VERSION "2021.24.4"

NS_ :

BS_:

BU_: VEH CH Receiver X

BA_DEF_ BO_ "GenMsgSendType" ENUM "Cyclic";
BA_DEF_ BO_ "GenMsgCycleTime" INT 0 10000;

BA_ "GenMsgSendType" BO_ 1019 0;
BA_ "GenMsgCycleTime" BO_ 1019 1000;

BO_ 946 BMS_log2: 8 Vector__XXX
 SG_ BMS_cacAgedMinRawIsValid m1 : 63|1@1+ (1,0) [0|0] "" Vector__XXX
 SG_ BMS_spmeBrick1ValidForCorrection m51 : 63|1@1+ (1,0) [0|0] "" Vector__XXX
 SG_ BMS_thermalEvent1pDetectConfigDi m71 : 63|1@1+ (1,0) [0|0] "" Vector__XXX
 SG_ BMS_vChangeWindowChangeIsOutlier m23 : 63|1@1+ (1,0) [0|0] "" Vector__XXX
 SG_ BMS_energyBufferConfigNvramValid m71 : 62|1@1+ (1,0) [0|0] "" Vector__XXX
 SG_ BMS_histogramTemperatureIrration m30 : 62|1@1+ (1,0) [0|0] "" Vector__XXX
 SG_ BMS_spmeMaxBrickValidForCorrecti m53 : 62|1@1+ (1,0) [0|0] "" Vector__XXX
 SG_ BMS_spmeMinBrickValidForCorrecti m52 : 62|1@1+ (1,0) [0|0] "" Vector__XXX
 SG_ BMS_histogramStorageDataIsLow m30 : 61|1@1+ (1,0) [0|0] "" Vector__XXX
 SG_ BMS_sampleChargePower m4 : 61|1@1+ (1,0) [0|0] "" Vector__XXX
 SG_ BMS_cacEstimationSource m65 : 60|2@1+ (1,0) [0|0] "" Vector__XXX
 SG_ BMS_histogramTotalTimeIrrational m30 : 60|1@1+ (1,0) [0|0] "" Vector__XXX
 SG_ BMS_lifeModelNvramIsValid m63 : 60|1@1+ (1,0) [0|0] "" Vector__XXX
 SG_ BMS_spmeBrick1LowestCostIndex m50 : 60|4@1+ (1,0) [0|0] "" Vector__XXX
 SG_ BMS_histogramChargeThroughputIrr m30 : 59|1@1+ (1,0) [0|0] "" Vector__XXX
 SG_ BMS_maxSocCorrectionTypeWindowed m73 : 59|2@1+ (1,0) [0|0] "" Vector__XXX
 SG_ BMS_cpUserChargeStatus m4 : 58|3@1+ (1,0) [0|0] "" Vector__XXX
 SG_ BMS_histogramDischargeThroughput m30 : 58|1@1+ (1,0) [0|0] "" Vector__XXX
 SG_ BMS_hvChainConfig m2 : 58|3@1+ (1,0) [0|0] "" Vector__XXX
 SG_ BMS_packCalibrationBirthDat_0000 m67 : 58|1@1+ (1,0) [0|0] "" Vector__XXX
 SG_ BMS_spmeMaxSocLowestCostIndex m53 : 58|4@1+ (1,0) [0|0] "" Vector__XXX
 SG_ BMS_spmeMinSocLowestCostIndex m52 : 58|4@1+ (1,0) [0|0] "" Vector__XXX
 SG_ BMS_cacMaxBrickId m0 : 57|7@1+ (1,1) [0|0] "" Vector__XXX
 SG_ BMS_histogramStartTimeIrrational m30 : 57|1@1+ (1,0) [0|0] "" Vector__XXX
 SG_ BMS_lifeModelOutputsAreTrustwort m31 : 57|1@1+ (1,0) [0|0] "" Vector__XXX
 SG_ BMS_spmeLastReInitReason m48 : 57|2@1+ (1,0) [0|0] "" Vector__XXX
 SG_ BMS_brickBleedByVoltageTargetBri m35 : 56|7@1+ (1,1) [0|0] "" Vector__XXX
 SG_ BMS_cacNvramEstimationSource m2 : 56|2@1+ (1,0) [0|0] "" Vector__XXX
 SG_ BMS_largestSynchronizedCacErrorP m56 : 56|8@1+ (0.1,0) [0|0] "" Vector__XXX
 SG_ BMS_minPackTempForChargeToStart m91 : 56|7@1+ (0.5,-40) [0|0] "" Vector__XXX
 SG_ BMS_numBricksRestingForCac m58 : 56|8@1+ (1,0) [0|0] "" Vector__XXX
 SG_ BMS_peakRegenCurrentLimitMode m3 : 56|4@1+ (1,0) [0|0] "" Vector__XXX
 SG_ BMS_powerVsVoltageChgEnergy_0000 m68 : 56|8@1+ (0.01,2) [0|0] "" Vector__XXX
 SG_ BMS_runtimeSocMinTempForModel m71 : 56|6@1+ (0.5,0) [0|0] "" Vector__XXX
 SG_ BMS_socByDvMaxBrickId m90 : 56|8@1+ (1,1) [0|0] "" Vector__XXX
 SG_ BMS_socImbalancePct m82 : 56|8@1+ (0.1,0) [0|0] "" Vector__XXX
 SG_ BMS_tempVsVoltageDcChgWeigh_0000 m69 : 56|8@1+ (0.01,2) [0|0] "" Vector__XXX
 SG_ BMS_thmGradient m21 : 56|8@1+ (0.1,0) [0|0] "" Vector__XXX
 SG_ BMS_vChangeWindowTimeAfterWake m23 : 56|7@1+ (0.1,0) [0|0] "" Vector__XXX
 SG_ BMS_acRippleStartTemperatureMin m18 : 55|9@1+ (0.25,-25) [0|0] "" Vector__XXX
 SG_ BMS_cellAttributesShipPackForFai m85 : 55|1@1+ (1,0) [0|0] "" Vector__XXX
 SG_ BMS_dSocCacMargin m33 : 55|9@1+ (0.0030517578125,0) [0|0] "" Vector__XXX
 SG_ BMS_passiveCoolCellTargetT m54 : 55|9@1+ (0.25,-25) [0|0] "" Vector__XXX
 SG_ BMS_rubberBandingConfigNvramVali m71 : 55|1@1+ (1,0) [0|0] "" Vector__XXX
 SG_ BMS_spmeInitCountSinceReset m51 : 55|8@1+ (1,0) [0|0] "" Vector__XXX
 SG_ BMS_acRippleMaxSocAllowed m36 : 54|10@1+ (0.1,0) [0|0] "" Vector__XXX
 SG_ BMS_acRippleMinSocAllowed m37 : 54|10@1+ (0.1,0) [0|0] "" Vector__XXX
 SG_ BMS_brick1SocCorrectionSpmeLower m74 : 54|10@1+ (0.1,0) [0|0] "" Vector__XXX
 SG_ BMS_cacBlendPercentPerDayUpperBo m27 : 54|10@1+ (0.001,0) [0|0] "" Vector__XXX
 SG_ BMS_cellAttributesAutocloseAndSc m85 : 54|1@1+ (1,0) [0|0] "" Vector__XXX
 SG_ BMS_continuousDcrBlendFactor m34 : 54|10@1+ (0.001,0) [0|0] "" Vector__XXX
 SG_ BMS_dcrBlendFactorPerDayUpperBou m57 : 54|10@1+ (0.001,0) [0|0] "" Vector__XXX
 SG_ BMS_energyChargeSocTarget m87 : 54|10@1+ (0.1,0) [0|0] "" Vector__XXX
 SG_ BMS_percentCacUpdatesInTimeWindo m64 : 54|10@1+ (0.1,0) [0|0] "" Vector__XXX
 SG_ BMS_rubberBandingEnabled m71 : 54|1@1+ (1,0) [0|0] "" Vector__XXX
 SG_ BMS_cacBlendPercentPerCycle m20 : 53|10@1+ (0.001,0) [0|0] "" Vector__XXX
 SG_ BMS_cacImbalanceCurrentAdjustmen m38 : 53|10@1+ (0.1,0) [0|0] "" Vector__XXX
 SG_ BMS_cacMaxKalmanError m1 : 53|10@1+ (0.01,0) [0|0] "" Vector__XXX
 SG_ BMS_diNodeModelTemp m60 : 53|11@1+ (0.1,-50) [0|0] "" Vector__XXX
 SG_ BMS_lowCurrentInterruptionCurren m45 : 53|9@1- (0.1,0) [0|0] "" Vector__XXX
 SG_ BMS_runtimeSocCorrectionsEnabled m71 : 53|1@1+ (1,0) [0|0] "" Vector__XXX
 SG_ BMS_shuntOffsetCalibrationTemp m84 : 53|11@1- (0.05,0) [0|0] "" Vector__XXX
 SG_ BMS_cacBlendingEnabled m20 : 52|1@1+ (1,0) [0|0] "" Vector__XXX
 SG_ BMS_dSocNoiseMargin m24 : 52|10@1+ (0.0030517578125,0) [0|0] "" Vector__XXX
 SG_ BMS_lifeModelThroughputDcrCycleC m80 : 52|12@1+ (1,0) [0|0] "" Vector__XXX
 SG_ BMS_prevUserFacingSohEnergy m79 : 52|11@1+ (0.1,0) [0|0] "" Vector__XXX
 SG_ BMS_restingPointCacBrick1 m66 : 52|12@1+ (0.1,0) [0|0] "" Vector__XXX
 SG_ BMS_runtimeSocConfigNvramValid m71 : 52|1@1+ (1,0) [0|0] "" Vector__XXX
 SG_ BMS_runtimeSocElectrolyteVoltage m72 : 52|10@1- (0.001,-0.5) [0|0] "" Vector__XXX
 SG_ BMS_soloWakeCount m44 : 52|12@1+ (1,0) [0|0] "" Vector__XXX
 SG_ BMS_spmeBrick1CathodeSurfaceConc m49 : 52|10@1+ (0.001,0) [0|0] "" Vector__XXX
 SG_ BMS_vshResMax2 m25 : 52|12@1+ (0.002,0) [0|0] "" Vector__XXX
 SG_ BMS_vshResMin3 m26 : 52|12@1+ (0.002,0) [0|0] "" Vector__XXX
 SG_ BMS_cacBlendingConfigNvramValid m20 : 51|1@1+ (1,0) [0|0] "" Vector__XXX
 SG_ BMS_cellChargeDcCurrentLimit m89 : 51|12@1+ (0.5,0) [0|0] "" Vector__XXX
 SG_ BMS_largestSyncCacErrorLower m62 : 51|12@1+ (0.1,0) [0|0] "" Vector__XXX
 SG_ BMS_lowCurrentInterruptionReason m45 : 51|2@1+ (1,0) [0|0] "" Vector__XXX
 SG_ BMS_cacAvgAgedRawEstimate m59 : 50|13@1+ (0.1,0) [0|0] "" Vector__XXX
 SG_ BMS_cacAvgOffsetUpdateEndPointSo m81 : 50|10@1+ (0.1,0) [0|0] "" Vector__XXX
 SG_ BMS_cacTransitionBlendOffset m40 : 50|10@1- (0.1,0) [0|0] "" Vector__XXX
 SG_ BMS_cacUpdateDeltaSocByAhSpread m61 : 50|11@1- (0.01,0) [0|0] "" Vector__XXX
 SG_ BMS_dSocMinAlphaSocBleedMargin m41 : 50|12@1+ (0.0030517578125,0) [0|0] "" Vector__XXX
 SG_ BMS_maxSpreadChangeSocStart m75 : 50|10@1+ (0.1,0) [0|0] "" Vector__XXX
 SG_ BMS_negCtrDeviationConfidenceMax m14 : 50|13@1+ (0.000122100107192,0) [0|0] "" Vector__XXX
 SG_ BMS_negCtrDeviationFiltConfMax m15 : 50|13@1+ (0.000122100107192,0) [0|0] "" Vector__XXX
 SG_ BMS_negCtrDropCorrectedFiltMax m16 : 50|13@1- (0.001221299164314,0) [0|0] "" Vector__XXX
 SG_ BMS_negCtrOffsetErrorConf m17 : 50|13@1+ (0.000122100107192,0) [0|0] "" Vector__XXX
 SG_ BMS_negCtrResistanceConfidence m9 : 50|13@1+ (12.21001071916841,0) [0|0] "" Vector__XXX
 SG_ BMS_posCtrDeviationConfidenceMax m10 : 50|13@1+ (0.000122100107192,0) [0|0] "" Vector__XXX
 SG_ BMS_posCtrDeviationFiltConfMax m11 : 50|13@1+ (0.000122100107192,0) [0|0] "" Vector__XXX
 SG_ BMS_posCtrDropCorrectedFiltMax m12 : 50|13@1- (0.001221299164314,0) [0|0] "" Vector__XXX
 SG_ BMS_posCtrOffsetErrorConf m13 : 50|13@1+ (0.000122100107192,0) [0|0] "" Vector__XXX
 SG_ BMS_recentBmbMiaAlert m20 : 50|1@1+ (1,0) [0|0] "" Vector__XXX
 SG_ BMS_rubberBandingConfigDischarge m76 : 50|10@1+ (0.1,0) [0|0] "" Vector__XXX
 SG_ BMS_socTopVsSocBtmDchWeightedAvg m46 : 50|14@1+ (0.01,0) [0|0] "" Vector__XXX
 SG_ BMS_1kHzTask_maxExecTime m8 : 49|11@1+ (1,0) [0|0] "" Vector__XXX
 SG_ BMS_cellTempTargetMode m91 : 49|4@1+ (1,0) [0|0] "" Vector__XXX
 SG_ BMS_dcrBlendFactorPerCycle m43 : 49|10@1+ (0.001,0) [0|0] "" Vector__XXX
 SG_ BMS_recentIsoAlert m20 : 49|1@1+ (1,0) [0|0] "" Vector__XXX
 SG_ BMS_avgShuntAsicCurrentOffset m83 : 48|15@1- (0.2,0) [0|0] "" Vector__XXX
 SG_ BMS_capacityImbalancePct m22 : 48|10@1+ (0.1,0) [0|0] "" Vector__XXX
 SG_ BMS_cellAttributesCellType m85 : 48|6@1+ (1,0) [0|0] "" Vector__XXX
 SG_ BMS_chargeTimeEstimate m86 : 48|14@1+ (0.1,0) [0|0] "" Vector__XXX
 SG_ BMS_dSocMinAlphaBrickID m33 : 48|7@1+ (1,1) [0|0] "" Vector__XXX
 SG_ BMS_dcrBlendingEnabled m43 : 48|1@1+ (1,0) [0|0] "" Vector__XXX
 SG_ BMS_energyReserveAvg m19 : 48|16@1+ (0.001,0) [0|0] "" Vector__XXX
 SG_ BMS_largestCacSpreadErrorUpper m63 : 48|12@1+ (0.1,0) [0|0] "" Vector__XXX
 SG_ BMS_latchedFullPackEnergyError m88 : 48|10@1- (0.1,0) [0|0] "" Vector__XXX
 SG_ BMS_lifeModelDcrGrowthPercent m55 : 48|14@1- (0.1,200) [0|0] "" Vector__XXX
 SG_ BMS_lifeModelThroughputDcrGrowth m77 : 48|14@1- (0.1,200) [0|0] "" Vector__XXX
 SG_ BMS_maxCapacityLossModuleId m38 : 48|5@1+ (1,1) [0|0] "" Vector__XXX
 SG_ BMS_maxPossibleDcChargePower m2 : 48|8@1+ (1,0) [0|0] "" Vector__XXX
 SG_ BMS_maxSocChangeWindowed m73 : 48|11@1- (0.1,0) [0|0] "" Vector__XXX
 SG_ BMS_recentOvUvAlert m20 : 48|1@1+ (1,0) [0|0] "" Vector__XXX
 SG_ BMS_restingPointCacAvg m65 : 48|12@1+ (0.1,0) [0|0] "" Vector__XXX
 SG_ BMS_sohTestBlockReason m45 : 48|3@1+ (1,0) [0|0] "" Vector__XXX
 SG_ BMS_spmeBrick1BestFitCost m50 : 48|12@1+ (1e-05,0) [0|0] "" Vector__XXX
 SG_ BMS_stateOfHealthMinCacLowerBoun m78 : 48|13@1+ (0.1,0) [0|0] "" Vector__XXX
 SG_ BMS_unexpectedLossOfLvCounter m57 : 48|6@1+ (1,0) [0|0] "" Vector__XXX
 SG_ BMS_vshTestMinDeltaVBrickID m3 : 48|7@1+ (1,1) [0|0] "" Vector__XXX
 SG_ BMS_brickBleedByAhMinBrickId m36 : 47|7@1+ (1,1) [0|0] "" Vector__XXX
 SG_ BMS_brickBleedChargeMaxBrickId m34 : 47|7@1+ (1,1) [0|0] "" Vector__XXX
 SG_ BMS_brickBleedExcessChargeMaxBri m37 : 47|7@1+ (1,1) [0|0] "" Vector__XXX
 SG_ BMS_currentReg_targetI m4 : 47|11@1+ (0.5,0) [0|0] "" Vector__XXX
 SG_ BMS_powerVsVoltageChgEnergyWeigh m68 : 47|9@1+ (0.01,0) [0|0] "" Vector__XXX
 SG_ BMS_acRippleStartTemperatureMax m18 : 46|9@1+ (0.25,-25) [0|0] "" Vector__XXX
 SG_ BMS_lifeModelThroughputCapacityL m54 : 46|9@1+ (0.1,0) [0|0] "" Vector__XXX
 SG_ BMS_sohMinCacConfidenceBound m82 : 46|10@1+ (0.1,0) [0|0] "" Vector__XXX
 SG_ BMS_spmeMaxSocBestFitCost m53 : 46|12@1+ (1e-05,0) [0|0] "" Vector__XXX
 SG_ BMS_spmeMinSocBestFitCost m52 : 46|12@1+ (1e-05,0) [0|0] "" Vector__XXX
 SG_ BMS_vshResMaxIndex2 m25 : 46|6@1+ (1,0) [0|0] "" Vector__XXX
 SG_ BMS_vshResMinIndex3 m26 : 46|6@1+ (1,0) [0|0] "" Vector__XXX
 SG_ BMS_acRippleIsSupported m18 : 45|1@1+ (1,0) [0|0] "" Vector__XXX
 SG_ BMS_brick1SocCorrectionSpmeUpper m74 : 44|10@1+ (0.1,0) [0|0] "" Vector__XXX
 SG_ BMS_brick1SocCorrectionType m73 : 44|2@1+ (1,0) [0|0] "" Vector__XXX
 SG_ BMS_cacBlendPercentPerDayLowerBo m27 : 44|10@1+ (0.001,0) [0|0] "" Vector__XXX
 SG_ BMS_cacMax m0 : 44|13@1+ (0.1,0) [0|0] "" Vector__XXX
 SG_ BMS_cellAttributesConfigNvramVal m85 : 44|1@1+ (1,0) [0|0] "" Vector__XXX
 SG_ BMS_dSocMaxLowAlphaCounter m33 : 44|4@1+ (1,0) [0|0] "" Vector__XXX
 SG_ BMS_lifeModelAverageOffset m64 : 44|10@1- (0.1,0) [0|0] "" Vector__XXX
 SG_ BMS_sohTestEndMode m45 : 44|4@1+ (1,0) [0|0] "" Vector__XXX
 SG_ BMS_spmeBrick1ModelVsNominalSocO m51 : 44|11@1- (0.1,0) [0|0] "" Vector__XXX
 SG_ BMS_thmGradientSlope m21 : 44|10@1- (0.01,0) [0|0] "" Vector__XXX
 SG_ BMS_userChargeCalibratingReason m57 : 44|2@1+ (1,0) [0|0] "" Vector__XXX
 SG_ BMS_vChangeWindowMinBrickV m23 : 44|12@1+ (0.002,0) [0|0] "" Vector__XXX
 SG_ BMS_cacMinAgedUpperBoundEst m58 : 43|13@1+ (0.1,0) [0|0] "" Vector__XXX
 SG_ BMS_cellAttributesRemanufactured m85 : 43|1@1+ (1,0) [0|0] "" Vector__XXX
 SG_ BMS_numOfBricks m89 : 43|8@1+ (1,0) [0|0] "" Vector__XXX
 SG_ BMS_temperatureCondition m21 : 43|1@1+ (1,0) [0|0] "" Vector__XXX
 SG_ BMS_largestSyncCacErrorEndSoc m71 : 42|10@1+ (0.1,0) [0|0] "" Vector__XXX
 SG_ BMS_runtimeSocMinCorrectionThres m72 : 42|10@1+ (0.1,0) [0|0] "" Vector__XXX
 SG_ BMS_socChangeSocByOcvMax m24 : 42|10@1+ (0.1,0) [0|0] "" Vector__XXX
 SG_ BMS_spmeBrick1CathodeBulkConcent m49 : 42|10@1+ (0.001,0) [0|0] "" Vector__XXX
 SG_ BMS_energyLowestDchBrickCac m87 : 41|13@1+ (0.1,0) [0|0] "" Vector__XXX
 SG_ BMS_estimatedCapacitySohEnergy m79 : 41|11@1+ (0.1,0) [0|0] "" Vector__XXX
 SG_ BMS_spmeAhDischargedAfterZero m48 : 41|16@1+ (0.1,0) [0|0] "" Vector__XXX
 SG_ BMS_activeCoolCellTargetT m91 : 40|9@1+ (0.25,-25) [0|0] "" Vector__XXX
 SG_ BMS_brickBleedByAhTargetBrickId m36 : 40|7@1+ (1,1) [0|0] "" Vector__XXX
 SG_ BMS_brickBleedByVoltageTarget m35 : 40|16@1+ (0.0001,0) [0|0] "" Vector__XXX
 SG_ BMS_brickBleedChargeMinBrickId m34 : 40|7@1+ (1,1) [0|0] "" Vector__XXX
 SG_ BMS_brickBleedExcessChargeMinBri m37 : 40|7@1+ (1,1) [0|0] "" Vector__XXX
 SG_ BMS_cacAvgOffsetUpdateStartPoint m81 : 40|10@1+ (0.1,0) [0|0] "" Vector__XXX
 SG_ BMS_cacEndPointSocSpread m61 : 40|10@1+ (0.1,0) [0|0] "" Vector__XXX
 SG_ BMS_cacMinUpperBoundEst m1 : 40|13@1+ (0.1,0) [0|0] "" Vector__XXX
 SG_ BMS_cellAttributesPackManufactur m85 : 40|3@1+ (1,0) [0|0] "" Vector__XXX
 SG_ BMS_cumulativeBrickBleedTimeMaxB m41 : 40|10@1+ (1,1) [0|0] "" Vector__XXX
 SG_ BMS_cumulativeBrickBleedTimeMinB m40 : 40|10@1+ (1,1) [0|0] "" Vector__XXX
 SG_ BMS_energyChgWhWhPerDayTotalTime m28 : 40|24@1+ (0.05,0) [0|0] "" Vector__XXX
 SG_ BMS_energyDcChgWhWhPerDayTotalTi m29 : 40|24@1+ (0.05,0) [0|0] "" Vector__XXX
 SG_ BMS_idealEnergyRemainingBuffered m56 : 40|16@1+ (0.02,0) [0|0] "" Vector__XXX
 SG_ BMS_lifeModelThroughputCycleCoun m80 : 40|12@1+ (1,0) [0|0] "" Vector__XXX
 SG_ BMS_lifeModelThroughputDcrTemper m78 : 40|7@1+ (0.1,0) [0|0] "" Vector__XXX
 SG_ BMS_minCapacityLossModuleId m38 : 40|5@1+ (1,1) [0|0] "" Vector__XXX
 SG_ BMS_pctTimeAtHighSoc m70 : 40|14@1+ (0.01,0) [0|0] "" Vector__XXX
 SG_ BMS_restingPointCacMin m66 : 40|12@1+ (0.1,0) [0|0] "" Vector__XXX
 SG_ BMS_shuntMeasurementSoloWakeCoun m44 : 40|12@1+ (1,0) [0|0] "" Vector__XXX
 SG_ BMS_socByDvMaxBrickVoltage m90 : 40|12@1+ (0.002,0) [0|0] "" Vector__XXX
 SG_ BMS_synchronizedCacRawAverage m60 : 40|13@1+ (0.1,0) [0|0] "" Vector__XXX
 SG_ BMS_tempVsVoltageDcChgWeightedAv m69 : 40|14@1- (0.1,0) [0|0] "" Vector__XXX
 SG_ BMS_cacMinUpdateAhError m22 : 39|9@1- (0.05,0) [0|0] "" Vector__XXX
 SG_ BMS_largestSyncCacErrorUpper m62 : 39|12@1+ (0.1,0) [0|0] "" Vector__XXX
 SG_ BMS_isoResistanceExtNegative m43 : 38|10@1+ (10,0) [0|0] "" Vector__XXX
 SG_ BMS_maxSpreadChangeCacPrev m75 : 38|12@1+ (0.1,0) [0|0] "" Vector__XXX
 SG_ BMS_missingCellCurrentLimit m88 : 38|10@1+ (1,0) [0|0] "" Vector__XXX
 SG_ BMS_numOfThermistors m89 : 38|5@1+ (1,0) [0|0] "" Vector__XXX
 SG_ BMS_shuntAsicCurrentOffset m84 : 38|15@1- (0.2,0) [0|0] "" Vector__XXX
 SG_ BMS_spmeBrick1SocUpperBound m50 : 38|10@1+ (0.1,0) [0|0] "" Vector__XXX
 SG_ BMS_acRippleCurrentAmplitudeIdea m68 : 37|10@1+ (1,0) [0|0] "" Vector__XXX
 SG_ BMS_cacAgedUpperBoundEstBrick1 m59 : 37|13@1+ (0.1,0) [0|0] "" Vector__XXX
 SG_ BMS_cacMinBrickId m0 : 37|7@1+ (1,1) [0|0] "" Vector__XXX
 SG_ BMS_lifeModelStorageCapacityLoss m54 : 37|9@1+ (0.1,0) [0|0] "" Vector__XXX
 SG_ BMS_negCtrDeviationConfidenceMin m14 : 37|13@1+ (0.000122100107192,0) [0|0] "" Vector__XXX
 SG_ BMS_negCtrDeviationFiltConfMin m15 : 37|13@1+ (0.000122100107192,0) [0|0] "" Vector__XXX
 SG_ BMS_negCtrDropCorrectedFiltMin m16 : 37|13@1- (0.001221299164314,0) [0|0] "" Vector__XXX
 SG_ BMS_negCtrOffsetError m17 : 37|13@1- (0.001221299164314,0) [0|0] "" Vector__XXX
 SG_ BMS_negCtrResistance m9 : 37|13@1- (2.442598329e-06,0) [0|0] "" Vector__XXX
 SG_ BMS_posCtrDeviationConfidenceMin m10 : 37|13@1+ (0.000122100107192,0) [0|0] "" Vector__XXX
 SG_ BMS_posCtrDeviationFiltConfMin m11 : 37|13@1+ (0.000122100107192,0) [0|0] "" Vector__XXX
 SG_ BMS_posCtrDropCorrectedFiltMin m12 : 37|13@1- (0.001221299164314,0) [0|0] "" Vector__XXX
 SG_ BMS_posCtrOffsetError m13 : 37|13@1- (0.001221299164314,0) [0|0] "" Vector__XXX
 SG_ BMS_predictedEnergyCharged m86 : 37|11@1+ (0.1,0) [0|0] "" Vector__XXX
 SG_ BMS_largestCacSpreadErrorRaw m63 : 36|12@1+ (0.1,0) [0|0] "" Vector__XXX
 SG_ BMS_lifeModelMinCac m65 : 36|12@1+ (0.1,0) [0|0] "" Vector__XXX
 SG_ BMS_maxDcCurrentAvailable m4 : 36|11@1+ (0.5,0) [0|0] "" Vector__XXX
 SG_ BMS_sohCacMinSocByOcvStart m82 : 36|10@1+ (0.1,0) [0|0] "" Vector__XXX
 SG_ BMS_spmeMaxSocUpperBound m53 : 36|10@1+ (0.1,0) [0|0] "" Vector__XXX
 SG_ BMS_spmeMinSocUpperBound m52 : 36|10@1+ (0.1,0) [0|0] "" Vector__XXX
 SG_ BMS_tempVsSocChgAndDchWeightedAv m46 : 36|14@1- (0.1,0) [0|0] "" Vector__XXX
 SG_ BMS_100HzTask_maxExecTime m8 : 35|14@1+ (1,0) [0|0] "" Vector__XXX
 SG_ BMS_stateOfHealth m83 : 35|10@1+ (0.1,0) [0|0] "" Vector__XXX
 SG_ BMS_cacMinSocByAgedOcvEnd m57 : 34|10@1+ (0.1,0) [0|0] "" Vector__XXX
 SG_ BMS_lifeModelStorageDcrGrowthPer m77 : 34|14@1- (0.1,200) [0|0] "" Vector__XXX
 SG_ BMS_vshResMax3 m26 : 34|12@1+ (0.002,0) [0|0] "" Vector__XXX
 SG_ BMS_vshResMin1 m25 : 34|12@1+ (0.002,0) [0|0] "" Vector__XXX
 SG_ BMS_chargeNeededState m4 : 33|3@1+ (1,0) [0|0] "" Vector__XXX
 SG_ BMS_dynamicEnergyBuffer m21 : 33|10@1+ (0.1,0) [0|0] "" Vector__XXX
 SG_ BMS_lifeModelHistogramBrickCapac m55 : 33|13@1+ (0.1,0) [0|0] "" Vector__XXX
 SG_ BMS_10HzTask_maxExecTime m7 : 32|17@1+ (1,0) [0|0] "" Vector__XXX
 SG_ BMS_1HzTask_maxExecTime m6 : 32|20@1+ (1,0) [0|0] "" Vector__XXX
 SG_ BMS_ahDischargeTotal m5 : 32|24@1+ (0.1,0) [0|0] "" Vector__XXX
 SG_ BMS_brick1SocCorrectionSpmeCost m74 : 32|12@1+ (1e-05,0) [0|0] "" Vector__XXX
 SG_ BMS_cumulativeAvailableBleedTime m39 : 32|24@1+ (1,0) [0|0] "" Vector__XXX
 SG_ BMS_cumulativeAvailableBlee_0000 m47 : 32|24@1+ (1,0) [0|0] "" Vector__XXX
 SG_ BMS_cumulativeBrickBleedTimeAvg m42 : 32|32@1+ (1,0) [0|0] "" Vector__XXX
 SG_ BMS_dSocMinAlpha m33 : 32|12@1+ (0.0030517578125,-12.4969482421875) [0|0] "" Vector__XXX
 SG_ BMS_energyReserveMax m19 : 32|16@1+ (0.001,0) [0|0] "" Vector__XXX
 SG_ BMS_floodPortV2 m2 : 32|16@1+ (0.001,0) [0|0] "" Vector__XXX
 SG_ BMS_hvChain_limitingStateTempera m18 : 32|13@1- (0.1,367.6) [0|0] "" Vector__XXX
 SG_ BMS_largestSyncCacErrorStartSoc m71 : 32|10@1+ (0.1,0) [0|0] "" Vector__XXX
 SG_ BMS_lifeModelCacBrick1 m64 : 32|12@1+ (0.1,0) [0|0] "" Vector__XXX
 SG_ BMS_lifeModelThroughputTemperatu m78 : 32|6@1+ (0.1,0) [0|0] "" Vector__XXX
 SG_ BMS_minBrickSocCorrectionSpmeCos m73 : 32|12@1+ (1e-05,0) [0|0] "" Vector__XXX
 SG_ BMS_pcsPrechargeTargetVoltage m20 : 32|16@1- (0.1,0) [0|0] "" Vector__XXX
 SG_ BMS_powerVsVoltageTotalChgEnergy m31 : 32|25@1+ (0.0001490116163793688,0) [0|0] "" Vector__XXX
 SG_ BMS_recentSlopeConditon m21 : 32|1@1+ (1,0) [0|0] "" Vector__XXX
 SG_ BMS_restingPointCacMinBrickId m66 : 32|8@1+ (1,1) [0|0] "" Vector__XXX
 SG_ BMS_runtimeSocResetThresholdInSu m72 : 32|10@1+ (0.1,0) [0|0] "" Vector__XXX
 SG_ BMS_socChangeSocByOcvMin m24 : 32|10@1+ (0.1,0) [0|0] "" Vector__XXX
 SG_ BMS_socTopVsSocBottomTotalDchEne m32 : 32|25@1+ (0.0001490116163793688,0) [0|0] "" Vector__XXX
 SG_ BMS_spmeBrick1AnodeSurfaceConcen m49 : 32|10@1+ (0.001,0) [0|0] "" Vector__XXX
 SG_ BMS_spmeMinBrickModel10Cost m51 : 32|12@1+ (1e-05,0) [0|0] "" Vector__XXX
 SG_ BMS_tempVsSocTotalDchEnergy m30 : 32|25@1+ (0.0001490116163793688,0) [0|0] "" Vector__XXX
 SG_ BMS_vChangeWindowChangeInitV m23 : 32|12@1+ (0.002,0) [0|0] "" Vector__XXX
 SG_ BMS_vshResMin4 m27 : 32|12@1+ (0.002,0) [0|0] "" Vector__XXX
 SG_ BMS_vshTestMinDeltaV m3 : 32|16@1+ (0.0002,0) [0|0] "" Vector__XXX
 SG_ BMS_energyLowestDchBrickSoc m87 : 31|10@1+ (0.1,0) [0|0] "" Vector__XXX
 SG_ BMS_thmGradientSlopeCondition m21 : 31|1@1+ (1,0) [0|0] "" Vector__XXX
 SG_ BMS_cacMinAgedRawEstimate m58 : 30|13@1+ (0.1,0) [0|0] "" Vector__XXX
 SG_ BMS_cacStartPointSocSpread m61 : 30|10@1+ (0.1,0) [0|0] "" Vector__XXX
 SG_ BMS_calibratedCapacitySohEnergy m79 : 30|11@1+ (0.1,0) [0|0] "" Vector__XXX
 SG_ BMS_maxModelThermistorTempDelta m91 : 30|10@1- (0.1,0) [0|0] "" Vector__XXX
 SG_ BMS_pcsPrechargeRequest m20 : 30|2@1+ (1,0) [0|0] "" Vector__XXX
 SG_ BMS_percentCacAvgOffsetUpdatesIn m81 : 30|10@1+ (0.1,0) [0|0] "" Vector__XXX
 SG_ BMS_cacsSynchronizedForSpreadUpd m61 : 29|1@1+ (1,0) [0|0] "" Vector__XXX
 SG_ BMS_avgCapacityLoss m38 : 28|10@1+ (0.1,0) [0|0] "" Vector__XXX
 SG_ BMS_cacMinDeltaAh m22 : 28|11@1- (0.5,0) [0|0] "" Vector__XXX
 SG_ BMS_cacRawImbalanceLowerBound m44 : 28|10@1+ (0.1,0) [0|0] "" Vector__XXX
 SG_ BMS_cacsSynchronizedForAvgUpdate m61 : 28|1@1+ (1,0) [0|0] "" Vector__XXX
 SG_ BMS_energyRemainingTDisplayError m89 : 28|10@1- (0.1,0) [0|0] "" Vector__XXX
 SG_ BMS_fuseChargeCurrentLimit m88 : 28|10@1+ (1,0) [0|0] "" Vector__XXX
 SG_ BMS_isoResistanceExtPositive m43 : 28|10@1+ (10,0) [0|0] "" Vector__XXX
 SG_ BMS_lifeModelMinCacBrickId m65 : 28|8@1+ (1,1) [0|0] "" Vector__XXX
 SG_ BMS_lifeModelSpreadAvgOffset m60 : 28|10@1- (0.1,0) [0|0] "" Vector__XXX
 SG_ BMS_socByDvMaxSocByAhCorrected m90 : 28|10@1+ (0.1,0) [0|0] "" Vector__XXX
 SG_ BMS_socByOcvMin m69 : 28|10@1+ (0.1,0) [0|0] "" Vector__XXX
 SG_ BMS_spmeBrick1SocLowerBound m50 : 28|10@1+ (0.1,0) [0|0] "" Vector__XXX
 SG_ BMS_vshResMaxIndex3 m26 : 28|6@1+ (1,0) [0|0] "" Vector__XXX
 SG_ BMS_vshResMinIndex1 m25 : 28|6@1+ (1,0) [0|0] "" Vector__XXX
 SG_ BMS_largestSyncCacErrorRaw m62 : 27|12@1+ (0.1,0) [0|0] "" Vector__XXX
 SG_ BMS_largestCacSpreadErrorBrickEn m63 : 26|10@1+ (0.1,0) [0|0] "" Vector__XXX
 SG_ BMS_maxSpreadChangeCacRaw m75 : 26|12@1+ (0.1,0) [0|0] "" Vector__XXX
 SG_ BMS_packCalibrationBirthDateBinn m67 : 26|32@1+ (1,0) [0|0] "" Vector__XXX
 SG_ BMS_sohCacMinSocByOcvEnd m82 : 26|10@1+ (0.1,0) [0|0] "" Vector__XXX
 SG_ BMS_spmeMaxSocLowerBound m53 : 26|10@1+ (0.1,0) [0|0] "" Vector__XXX
 SG_ BMS_spmeMinSocLowerBound m52 : 26|10@1+ (0.1,0) [0|0] "" Vector__XXX
 SG_ BMS_chargeTargetLookupSoc m83 : 25|10@1+ (0.1,0) [0|0] "" Vector__XXX
 SG_ BMS_energyLatchedMaxChargeCurren m86 : 25|12@1+ (1,0) [0|0] "" Vector__XXX
 SG_ BMS_socChangeByAgedOcvTempCorrec m68 : 25|12@1+ (0.001,1) [0|0] "" Vector__XXX
 SG_ BMS_spmeRestAhThroughput m48 : 25|16@1+ (0.1,0) [0|0] "" Vector__XXX
 SG_ BMS_1kHzTask_avgExecTime m8 : 24|11@1+ (1,0) [0|0] "" Vector__XXX
 SG_ BMS_balanceTimeThisCycle m35 : 24|16@1+ (0.5,0) [0|0] "" Vector__XXX
 SG_ BMS_brick1AhDischargedAfterZero m70 : 24|16@1+ (0.1,0) [0|0] "" Vector__XXX
 SG_ BMS_brickBleedByAhMin m36 : 24|13@1+ (0.1,0) [0|0] "" Vector__XXX
 SG_ BMS_brickBleedChargeMax m34 : 24|16@1+ (0.1,0) [0|0] "" Vector__XXX
 SG_ BMS_brickBleedExcessChargeMax m37 : 24|16@1+ (0.1,0) [0|0] "" Vector__XXX
 SG_ BMS_cacAgedRawEstimateBrick1 m59 : 24|13@1+ (0.1,0) [0|0] "" Vector__XXX
 SG_ BMS_cacMin m0 : 24|13@1+ (0.1,0) [0|0] "" Vector__XXX
 SG_ BMS_cacMinRawEstimate m1 : 24|13@1+ (0.1,0) [0|0] "" Vector__XXX
 SG_ BMS_cacMinSocByAgedOcvStart m57 : 24|10@1+ (0.1,0) [0|0] "" Vector__XXX
 SG_ BMS_dSocMaxAlphaBrickID m42 : 24|7@1+ (1,1) [0|0] "" Vector__XXX
 SG_ BMS_dynamicCcvEnabled m83 : 24|1@1+ (1,0) [0|0] "" Vector__XXX
 SG_ BMS_lifeModelHistogramCapacityLo m55 : 24|9@1+ (0.1,0) [0|0] "" Vector__XXX
 SG_ BMS_lifeModelLongDcr m54 : 24|13@1- (0.1,309.6) [0|0] "" Vector__XXX
 SG_ BMS_lifeModelStorageDcr2Temperat m78 : 24|7@1+ (0.025,0) [0|0] "" Vector__XXX
 SG_ BMS_lifeModelStorageLossPackAge m80 : 24|14@1+ (1,0) [0|0] "" Vector__XXX
 SG_ BMS_maxSocChangeBrickId m24 : 24|7@1+ (1,1) [0|0] "" Vector__XXX
 SG_ BMS_minZScoreInTimeWindow m81 : 24|6@1+ (0.1,0) [0|0] "" Vector__XXX
 SG_ BMS_negCtrCommonModeRejErrorConf m17 : 24|13@1+ (1.221001071916841,0) [0|0] "" Vector__XXX
 SG_ BMS_negCtrDeviationFiltMax m15 : 24|13@1- (0.001221299164314,0) [0|0] "" Vector__XXX
 SG_ BMS_negCtrDeviationMax m14 : 24|13@1- (0.001221299164314,0) [0|0] "" Vector__XXX
 SG_ BMS_negCtrDropCorrectedMax m16 : 24|13@1- (0.001221299164314,0) [0|0] "" Vector__XXX
 SG_ BMS_nominalEnergyRemainingBuffer m56 : 24|16@1+ (0.02,0) [0|0] "" Vector__XXX
 SG_ BMS_posCtrCommonModeRejErrorConf m13 : 24|13@1+ (1.221001071916841,0) [0|0] "" Vector__XXX
 SG_ BMS_posCtrDeviationFiltMax m11 : 24|13@1- (0.001221299164314,0) [0|0] "" Vector__XXX
 SG_ BMS_posCtrDeviationMax m10 : 24|13@1- (0.001221299164314,0) [0|0] "" Vector__XXX
 SG_ BMS_posCtrDropCorrectedMax m12 : 24|13@1- (0.001221299164314,0) [0|0] "" Vector__XXX
 SG_ BMS_posCtrResistanceConfidence m9 : 24|13@1+ (12.21001071916841,0) [0|0] "" Vector__XXX
 SG_ BMS_vChangeWindowMinBrickVId m23 : 24|7@1+ (1,1) [0|0] "" Vector__XXX
 SG_ BMS_vshTestMaxDeltaVBrickID m3 : 24|7@1+ (1,1) [0|0] "" Vector__XXX
 SG_ BMS_hvChain_limitingState m18 : 23|9@1+ (1,1) [0|0] "" Vector__XXX
 SG_ BMS_sleepCurrentSampleMax m84 : 23|15@1- (0.2,0) [0|0] "" Vector__XXX
 SG_ BMS_minBrickSocCorrectionFinalSo m73 : 22|10@1+ (0.1,0) [0|0] "" Vector__XXX
 SG_ BMS_tempVsSocTimeWeightedAvgTemp m46 : 22|14@1- (0.1,0) [0|0] "" Vector__XXX
 SG_ BMS_alphaSnapshotExpirationTime m68 : 21|4@1+ (1,0) [0|0] "" Vector__XXX
 SG_ BMS_idealEnergyFloor m21 : 21|10@1+ (0.1,0) [0|0] "" Vector__XXX
 SG_ BMS_maxChargeNearComplete m0 : 21|1@1+ (1,0) [0|0] "" Vector__XXX
 SG_ BMS_rubberBandingConfigMaxPctErr m72 : 21|10@1+ (0.1,0) [0|0] "" Vector__XXX
 SG_ BMS_spmeBrick1AnodeBulkConcentra m49 : 21|10@1+ (0.001,0) [0|0] "" Vector__XXX
 SG_ BMS_stateOfHealthByFreshOcv m77 : 21|13@1+ (0.1,0) [0|0] "" Vector__XXX
 SG_ BMS_dSocNormalizedFiltMin m33 : 20|12@1+ (0.0030517578125,-12.4969482421875) [0|0] "" Vector__XXX
 SG_ BMS_largestSyncCacErrorBrickId m62 : 20|7@1+ (1,1) [0|0] "" Vector__XXX
 SG_ BMS_lifeModelAverageCac m64 : 20|12@1+ (0.1,0) [0|0] "" Vector__XXX
 SG_ BMS_spmeMinBrickModel5Cost m51 : 20|12@1+ (1e-05,0) [0|0] "" Vector__XXX
 SG_ BMS_synchronizedCacMinRaw m71 : 20|12@1+ (0.1,0) [0|0] "" Vector__XXX
 SG_ BMS_vshResMax4 m27 : 20|12@1+ (0.002,0) [0|0] "" Vector__XXX
 SG_ BMS_brick1SocCorrectionFinalSoc m74 : 19|10@1+ (0.1,0) [0|0] "" Vector__XXX
 SG_ BMS_fullCapacitySohEnergy m79 : 19|11@1+ (0.1,0) [0|0] "" Vector__XXX
 SG_ BMS_offsetReg_output m4 : 19|14@1- (0.1,0) [0|0] "" Vector__XXX
 SG_ BMS_socByDvVoltageChangeOverAh m90 : 19|9@1+ (0.002,0) [0|0] "" Vector__XXX
 SG_ BMS_vChangeWindowNumOutlierChang m24 : 19|5@1+ (1,0) [0|0] "" Vector__XXX
 SG_ BMS_cacMinSocByOcvEnd m22 : 18|10@1+ (0.1,0) [0|0] "" Vector__XXX
 SG_ BMS_cacRawImbalanceUpperBound m44 : 18|10@1+ (0.1,0) [0|0] "" Vector__XXX
 SG_ BMS_configChargeCurrentLimit m88 : 18|10@1+ (1,0) [0|0] "" Vector__XXX
 SG_ BMS_energyLowestChgBrickCac m87 : 18|13@1+ (0.1,0) [0|0] "" Vector__XXX
 SG_ BMS_energyRemainingDisplayError m89 : 18|10@1- (0.1,0) [0|0] "" Vector__XXX
 SG_ BMS_fcLinkTestTimeSinceLastRun m20 : 18|12@1+ (0.01758241758,0) [0|0] "" Vector__XXX
 SG_ BMS_firstSynchronizedCacUpdateTi m76 : 18|32@1+ (1,0) [0|0] "" Vector__XXX
 SG_ BMS_isoResistanceIntNegative m43 : 18|10@1+ (10,0) [0|0] "" Vector__XXX
 SG_ BMS_lifeModelSpreadMaxOffset m60 : 18|10@1- (0.1,0) [0|0] "" Vector__XXX
 SG_ BMS_maxCapacityLoss m38 : 18|10@1+ (0.1,0) [0|0] "" Vector__XXX
 SG_ BMS_maxSpreadChangeBrickId m75 : 18|8@1+ (1,1) [0|0] "" Vector__XXX
 SG_ BMS_minCacBrickBiasedSpreadAhErr m61 : 18|10@1+ (0.01,0) [0|0] "" Vector__XXX
 SG_ BMS_socByOcvMax m69 : 18|10@1+ (0.1,0) [0|0] "" Vector__XXX
 SG_ BMS_spmeBrick1SocLowestCost m50 : 18|10@1+ (0.1,0) [0|0] "" Vector__XXX
 SG_ BMS_voltageInstabilityExcessNois m91 : 18|12@1+ (0.1,0) [0|0] "" Vector__XXX
 SG_ BMS_cacMinAgedLowerBoundEst m58 : 17|13@1+ (0.1,0) [0|0] "" Vector__XXX
 SG_ BMS_sohHighSocPointMinPackTemp m82 : 17|9@1+ (0.25,-25) [0|0] "" Vector__XXX
 SG_ BMS_energyLatchedMaxChargePower m86 : 16|9@1+ (1,0) [0|0] "" Vector__XXX
 SG_ BMS_energyReserveMin m19 : 16|16@1+ (0.001,0) [0|0] "" Vector__XXX
 SG_ BMS_energyWalkTimeoutCounter m83 : 16|8@1+ (1,0) [0|0] "" Vector__XXX
 SG_ BMS_floodPortV1 m2 : 16|16@1+ (0.001,0) [0|0] "" Vector__XXX
 SG_ BMS_largestCacSpreadErrorBrickSt m63 : 16|10@1+ (0.1,0) [0|0] "" Vector__XXX
 SG_ BMS_largestDerivedCacError m67 : 16|10@1- (0.01,0) [0|0] "" Vector__XXX
 SG_ BMS_lifeModelDepthOfDischargeSev m55 : 16|8@1+ (0.01,0) [0|0] "" Vector__XXX
 SG_ BMS_lifeModelMaxCac m65 : 16|12@1+ (0.1,0) [0|0] "" Vector__XXX
 SG_ BMS_lifeModelShortDcr m54 : 16|8@1+ (0.01,0) [0|0] "" Vector__XXX
 SG_ BMS_lifeModelStorageDcr1Temperat m78 : 16|7@1+ (0.1,0) [0|0] "" Vector__XXX
 SG_ BMS_maxZScoreInTimeWindow m81 : 16|6@1+ (0.1,0) [0|0] "" Vector__XXX
 SG_ BMS_restingPointCacMax m66 : 16|12@1+ (0.1,0) [0|0] "" Vector__XXX
 SG_ BMS_spmeMaxSocLowestCost m53 : 16|10@1+ (0.1,0) [0|0] "" Vector__XXX
 SG_ BMS_spmeMinSocLowestCost m52 : 16|10@1+ (0.1,0) [0|0] "" Vector__XXX
 SG_ BMS_vChangeWindowMaxVChangeId m23 : 16|7@1+ (1,1) [0|0] "" Vector__XXX
 SG_ BMS_vshResMax1 m25 : 16|12@1+ (0.002,0) [0|0] "" Vector__XXX
 SG_ BMS_vshResMin2 m26 : 16|12@1+ (0.002,0) [0|0] "" Vector__XXX
 SG_ BMS_vshResMinIndex4 m27 : 14|6@1+ (1,0) [0|0] "" Vector__XXX
 SG_ BMS_floodPortState2 m2 : 13|3@1+ (1,0) [0|0] "" Vector__XXX
 SG_ BMS_kwhDchAtSohCapture m45 : 12|32@1+ (1,0) [0|0] "" Vector__XXX
 SG_ BMS_minBrickSocCorrectionMagnitu m73 : 11|11@1- (0.1,0) [0|0] "" Vector__XXX
 SG_ BMS_floodPortState1 m2 : 10|3@1+ (1,0) [0|0] "" Vector__XXX
 SG_ BMS_stateOfHealthAvgCac m57 : 10|13@1+ (0.1,0) [0|0] "" Vector__XXX
 SG_ BMS_alphaAlertThreshold m68 : 9|12@1+ (0.0030517578125,-12.4969482421875) [0|0] "" Vector__XXX
 SG_ BMS_cacNvramIsValid m2 : 9|1@1+ (1,0) [0|0] "" Vector__XXX
 SG_ BMS_hvChain_iLimit m18 : 9|14@1+ (0.2,0) [0|0] "" Vector__XXX
 SG_ BMS_minBrickSocCorrectionType m73 : 9|2@1+ (1,0) [0|0] "" Vector__XXX
 SG_ BMS_packRestTime m21 : 9|12@1+ (0.01758241758,0) [0|0] "" Vector__XXX
 SG_ BMS_socByDvMaxSocLimit m90 : 9|10@1+ (0.1,0) [0|0] "" Vector__XXX
 SG_ BMS_spmeNominalAhThroughput m48 : 9|16@1+ (0.1,0) [0|0] "" Vector__XXX
 SG_ BMS_100HzTask_avgExecTime m8 : 8|14@1+ (1,0) [0|0] "" Vector__XXX
 SG_ BMS_10HzTask_avgExecTime m7 : 8|17@1+ (1,0) [0|0] "" Vector__XXX
 SG_ BMS_1HzTask_avgExecTime m6 : 8|20@1+ (1,0) [0|0] "" Vector__XXX
 SG_ BMS_ahChargeTotal m5 : 8|24@1+ (0.1,0) [0|0] "" Vector__XXX
 SG_ BMS_alphaConfigNvramValid m68 : 8|1@1+ (1,0) [0|0] "" Vector__XXX
 SG_ BMS_avgRawCacForSpread m62 : 8|12@1+ (0.1,0) [0|0] "" Vector__XXX
 SG_ BMS_brick1SocCorrectionMagnitude m74 : 8|11@1- (0.1,0) [0|0] "" Vector__XXX
 SG_ BMS_brickBleedByAhTarget m36 : 8|13@1+ (0.1,0) [0|0] "" Vector__XXX
 SG_ BMS_brickBleedChargeMin m34 : 8|16@1+ (0.1,0) [0|0] "" Vector__XXX
 SG_ BMS_brickBleedChargeRef m35 : 8|16@1+ (0.1,0) [0|0] "" Vector__XXX
 SG_ BMS_brickBleedExcessChargeMin m37 : 8|16@1+ (0.1,0) [0|0] "" Vector__XXX
 SG_ BMS_brickCacSpreadErrorStdDeviat m61 : 8|10@1+ (0.01,0) [0|0] "" Vector__XXX
 SG_ BMS_cacAgedLowerBoundEstBrick1 m59 : 8|13@1+ (0.1,0) [0|0] "" Vector__XXX
 SG_ BMS_cacAgedUpdateShuntAhError m58 : 8|9@1+ (0.1,-10) [0|0] "" Vector__XXX
 SG_ BMS_cacAvg m0 : 8|13@1+ (0.1,0) [0|0] "" Vector__XXX
 SG_ BMS_cacMetadataNvramIsValid m2 : 8|1@1+ (1,0) [0|0] "" Vector__XXX
 SG_ BMS_cacMinLowerBoundEst m1 : 8|13@1+ (0.1,0) [0|0] "" Vector__XXX
 SG_ BMS_cacMinSocByOcvStart m22 : 8|10@1+ (0.1,0) [0|0] "" Vector__XXX
 SG_ BMS_cacRawImbalanceEstimate m44 : 8|10@1+ (0.1,0) [0|0] "" Vector__XXX
 SG_ BMS_cellAttributesGeneralAttribu m85 : 8|32@1+ (1,0) [0|0] "" Vector__XXX
 SG_ BMS_chargeEnergyCounter m86 : 8|8@1+ (1,0) [0|0] "" Vector__XXX
 SG_ BMS_cumulativeBleedTime m39 : 8|24@1+ (1,0) [0|0] "" Vector__XXX
 SG_ BMS_cumulativeBleedTimeDaily m47 : 8|24@1+ (1,0) [0|0] "" Vector__XXX
 SG_ BMS_cumulativeBrickBleedTimeMax m41 : 8|32@1+ (1,0) [0|0] "" Vector__XXX
 SG_ BMS_cumulativeBrickBleedTimeMin m40 : 8|32@1+ (1,0) [0|0] "" Vector__XXX
 SG_ BMS_dSocMaxAlphaSocBleedMargin m42 : 8|12@1+ (0.0030517578125,0) [0|0] "" Vector__XXX
 SG_ BMS_dSocNormalizedMin m33 : 8|12@1+ (0.0030517578125,-12.4969482421875) [0|0] "" Vector__XXX
 SG_ BMS_energyLowestChgBrickSoc m87 : 8|10@1+ (0.1,0) [0|0] "" Vector__XXX
 SG_ BMS_energyVariableChgRequested m21 : 8|1@1+ (1,0) [0|0] "" Vector__XXX
 SG_ BMS_energyWalkCounter m83 : 8|8@1+ (1,0) [0|0] "" Vector__XXX
 SG_ BMS_epochTimeEstimate m29 : 8|32@1+ (1,0) [0|0] "" Vector__XXX
 SG_ BMS_fcLinkTestDecayTime m20 : 8|10@1+ (2,0) [0|0] "" Vector__XXX
 SG_ BMS_histStartEpochTime m28 : 8|32@1+ (1,0) [0|0] "" Vector__XXX
 SG_ BMS_hvChain_useLeakyBucket m18 : 8|1@1+ (1,0) [0|0] "" Vector__XXX
 SG_ BMS_hvacCoolingChargeCurrentLimi m88 : 8|10@1+ (1,0) [0|0] "" Vector__XXX
 SG_ BMS_isoResistanceIntPositive m43 : 8|10@1+ (10,0) [0|0] "" Vector__XXX
 SG_ BMS_largestCacSpreadErrorBrickId m63 : 8|7@1+ (1,1) [0|0] "" Vector__XXX
 SG_ BMS_largestCacSpreadErrorLower m64 : 8|12@1+ (0.1,0) [0|0] "" Vector__XXX
 SG_ BMS_largestDerivedCacErrorBrickI m67 : 8|8@1+ (1,1) [0|0] "" Vector__XXX
 SG_ BMS_largestSynchronizedCacE_0000 m81 : 8|8@1+ (0.1,0) [0|0] "" Vector__XXX
 SG_ BMS_lifeModelAvgTempSeverity m55 : 8|5@1+ (0.1,0) [0|0] "" Vector__XXX
 SG_ BMS_lifeModelMaxCacBrickId m65 : 8|8@1+ (1,1) [0|0] "" Vector__XXX
 SG_ BMS_lifeModelSpreadMinOffset m60 : 8|10@1- (0.1,0) [0|0] "" Vector__XXX
 SG_ BMS_lifeModelStorageTemperatureS m78 : 8|7@1+ (0.1,0) [0|0] "" Vector__XXX
 SG_ BMS_limpChargeCurrentLimit m89 : 8|10@1+ (1,0) [0|0] "" Vector__XXX
 SG_ BMS_loadReg_output m4 : 8|11@1- (0.1,0) [0|0] "" Vector__XXX
 SG_ BMS_maxSocChange m24 : 8|11@1- (0.1,0) [0|0] "" Vector__XXX
 SG_ BMS_maxSpreadCacChange m75 : 8|10@1- (0.1,0) [0|0] "" Vector__XXX
 SG_ BMS_maxSpreadChangeSocEnd m76 : 8|10@1+ (0.1,0) [0|0] "" Vector__XXX
 SG_ BMS_minBrickAhDischargedAfterZer m70 : 8|16@1+ (0.1,0) [0|0] "" Vector__XXX
 SG_ BMS_minCapacityLoss m38 : 8|10@1+ (0.1,0) [0|0] "" Vector__XXX
 SG_ BMS_negCtrCommonModeRejError m17 : 8|13@1- (2.442592959e-05,0) [0|0] "" Vector__XXX
 SG_ BMS_negCtrDeviationFiltMin m15 : 8|13@1- (0.001221299164314,0) [0|0] "" Vector__XXX
 SG_ BMS_negCtrDeviationMin m14 : 8|13@1- (0.001221299164314,0) [0|0] "" Vector__XXX
 SG_ BMS_negCtrDropCorrectedMin m16 : 8|13@1- (0.001221299164314,0) [0|0] "" Vector__XXX
 SG_ BMS_nominalFullPackEnergyRaw m56 : 8|16@1+ (0.02,0) [0|0] "" Vector__XXX
 SG_ BMS_posCtrCommonModeRejError m13 : 8|13@1- (2.4425983286e-05,0) [0|0] "" Vector__XXX
 SG_ BMS_posCtrDeviationFiltMin m11 : 8|13@1- (0.001221299164314,0) [0|0] "" Vector__XXX
 SG_ BMS_posCtrDeviationMin m10 : 8|13@1- (0.001221299164314,0) [0|0] "" Vector__XXX
 SG_ BMS_posCtrDropCorrectedMin m12 : 8|13@1- (0.001221299164314,0) [0|0] "" Vector__XXX
 SG_ BMS_posCtrResistance m9 : 8|13@1- (2.442598329e-06,0) [0|0] "" Vector__XXX
 SG_ BMS_restingPointCacMaxBrickId m66 : 8|8@1+ (1,1) [0|0] "" Vector__XXX
 SG_ BMS_rubberBandingConfigMaxBlendR m72 : 8|13@1+ (0.01,0) [0|0] "" Vector__XXX
 SG_ BMS_sleepCurrentSampleMin m84 : 8|15@1- (0.2,0) [0|0] "" Vector__XXX
 SG_ BMS_socByDeltaVEnabled m90 : 8|1@1+ (1,0) [0|0] "" Vector__XXX
 SG_ BMS_socByDvMaxSocByAhRaw m91 : 8|10@1+ (0.1,0) [0|0] "" Vector__XXX
 SG_ BMS_socByOcvEst m69 : 8|10@1+ (0.1,0) [0|0] "" Vector__XXX
 SG_ BMS_socCorrectionCycleFlag m73 : 8|1@1+ (1,0) [0|0] "" Vector__XXX
 SG_ BMS_sohEnergy m79 : 8|11@1+ (0.1,0) [0|0] "" Vector__XXX
 SG_ BMS_sohLowSocPointMinPackTemp m82 : 8|9@1+ (0.25,-25) [0|0] "" Vector__XXX
 SG_ BMS_sohTestStateInternal m45 : 8|4@1+ (1,0) [0|0] "" Vector__XXX
 SG_ BMS_spmeBrick1BrickSocNominal m50 : 8|10@1+ (0.1,0) [0|0] "" Vector__XXX
 SG_ BMS_spmeBrick1ElectrolyteVoltage m49 : 8|13@1- (0.001,0) [0|0] "" Vector__XXX
 SG_ BMS_spmeMaxSocBrickId m53 : 8|8@1+ (1,1) [0|0] "" Vector__XXX
 SG_ BMS_spmeMinBrickModel0Cost m51 : 8|12@1+ (1e-05,0) [0|0] "" Vector__XXX
 SG_ BMS_spmeMinSocBrickId m52 : 8|8@1+ (1,1) [0|0] "" Vector__XXX
 SG_ BMS_spmeModelRunning m48 : 8|1@1+ (1,0) [0|0] "" Vector__XXX
 SG_ BMS_stateOfHealthAvgCacByFreshOc m77 : 8|13@1+ (0.1,0) [0|0] "" Vector__XXX
 SG_ BMS_stateOfHealthMinCac m80 : 8|13@1+ (0.1,0) [0|0] "" Vector__XXX
 SG_ BMS_synchronizedCacMaxRaw m71 : 8|12@1+ (0.1,0) [0|0] "" Vector__XXX
 SG_ BMS_tempVsSocTimeWeightedAvgSoc m46 : 8|14@1+ (0.01,0) [0|0] "" Vector__XXX
 SG_ BMS_unexpectedLossOfLvPcsDcDcLvS m57 : 8|2@1+ (1,0) [0|0] "" Vector__XXX
 SG_ BMS_vChangeWindowMaxVChange m23 : 8|7@1- (0.0025,0) [0|0] "" Vector__XXX
 SG_ BMS_vshResMaxIndex1 m25 : 8|6@1+ (1,0) [0|0] "" Vector__XXX
 SG_ BMS_vshResMaxIndex4 m27 : 8|6@1+ (1,0) [0|0] "" Vector__XXX
 SG_ BMS_vshResMinIndex2 m26 : 8|6@1+ (1,0) [0|0] "" Vector__XXX
 SG_ BMS_vshTestMaxDeltaV m3 : 8|16@1- (0.0002,0) [0|0] "" Vector__XXX
 SG_ BMS_acRippleConfigNvramValid m18 : 7|1@1+ (1,0) [0|0] "" Vector__XXX
 SG_ BMS_acRippleHeatingDesired m28 : 7|1@1+ (1,0) [0|0] "" Vector__XXX
 SG_ BMS_acRippleStopTemperatureMax m19 : 7|9@1+ (0.25,-25) [0|0] "" Vector__XXX
 SG_ BMS_alphaAlertLimitingEnabled m68 : 7|1@1+ (1,0) [0|0] "" Vector__XXX
 SG_ BMS_alphaSoc1SnapshotState m34 : 7|1@1+ (1,0) [0|0] "" Vector__XXX
 SG_ BMS_lifeModelNoCurrentStorageCap m54 : 7|9@1+ (0.1,0) [0|0] "" Vector__XXX
 SG_ BMS_maxChargeRestartNeededByVolt m0 : 7|1@1+ (1,0) [0|0] "" Vector__XXX
 SG_ BMS_spmeElyteModelValidFlag m48 : 7|1@1+ (1,0) [0|0] "" Vector__XXX
 SG_ BMS_tempVsSocTotalChgEnergy m31 : 7|25@1+ (0.0001490116163793688,0) [0|0] "" Vector__XXX
 SG_ BMS_tempVsSocTotalTime m30 : 7|25@1+ (0.01,0) [0|0] "" Vector__XXX
 SG_ BMS_tempVsVoltageTotalDcChgEnerg m32 : 7|25@1+ (0.0001490116163793688,0) [0|0] "" Vector__XXX
 SG_ BMS_unexpectedLossOfLvPcsMia m57 : 7|1@1+ (1,0) [0|0] "" Vector__XXX
 SG_ BMS_log2MuxId M : 0|7@1+ (1,0) [0|0] "" Vector__XXX

BO_ 954 USM_alertMatrix: 8 Vector__XXX
 SG_ USM_a240_s1HwComErrDiagnostics m3 : 63|1@1+ (1,0) [0|0] "" Vector__XXX
 SG_ USM_a180_s4Blocked m2 : 63|1@1+ (1,0) [0|0] "" Vector__XXX
 SG_ USM_a120_DI_DRIVE_MIA m1 : 63|1@1+ (1,0) [0|0] "" Vector__XXX
 SG_ USM_a060_engineeringBuild m0 : 63|1@1+ (1,0) [0|0] "" Vector__XXX
 SG_ USM_a179_s3Blocked m2 : 62|1@1+ (1,0) [0|0] "" Vector__XXX
 SG_ USM_a119_SCCM_MIA m1 : 62|1@1+ (1,0) [0|0] "" Vector__XXX
 SG_ USM_a059_inputResistanceHigh m0 : 62|1@1+ (1,0) [0|0] "" Vector__XXX
 SG_ USM_a238_s12InitError m3 : 61|1@1+ (1,0) [0|0] "" Vector__XXX
 SG_ USM_a178_s2Blocked m2 : 61|1@1+ (1,0) [0|0] "" Vector__XXX
 SG_ USM_a118_VCFRONT_MIA m1 : 61|1@1+ (1,0) [0|0] "" Vector__XXX
 SG_ USM_a058_inputRHighSyncDebug m0 : 61|1@1+ (1,0) [0|0] "" Vector__XXX
 SG_ USM_a237_s11InitError m3 : 60|1@1+ (1,0) [0|0] "" Vector__XXX
 SG_ USM_a177_s1Blocked m2 : 60|1@1+ (1,0) [0|0] "" Vector__XXX
 SG_ USM_a117_VCLEFT_MIA m1 : 60|1@1+ (1,0) [0|0] "" Vector__XXX
 SG_ USM_a057_HVP_MIA m0 : 60|1@1+ (1,0) [0|0] "" Vector__XXX
 SG_ USM_a236_s10InitError m3 : 59|1@1+ (1,0) [0|0] "" Vector__XXX
 SG_ USM_a116_VCRIGHT_MIA m1 : 59|1@1+ (1,0) [0|0] "" Vector__XXX
 SG_ USM_a235_s9InitError m3 : 58|1@1+ (1,0) [0|0] "" Vector__XXX
 SG_ USM_a115_VCSEC_MIA m1 : 58|1@1+ (1,0) [0|0] "" Vector__XXX
 SG_ USM_a234_s8InitError m3 : 57|1@1+ (1,0) [0|0] "" Vector__XXX
 SG_ USM_a114_ESP_MIA m1 : 57|1@1+ (1,0) [0|0] "" Vector__XXX
 SG_ USM_a233_s7InitError m3 : 56|1@1+ (1,0) [0|0] "" Vector__XXX
 SG_ USM_a113_UI_MIA m1 : 56|1@1+ (1,0) [0|0] "" Vector__XXX
 SG_ USM_a232_s6InitError m3 : 55|1@1+ (1,0) [0|0] "" Vector__XXX
 SG_ USM_a112_EPBL_MIA m1 : 55|1@1+ (1,0) [0|0] "" Vector__XXX
 SG_ USM_a231_s5InitError m3 : 54|1@1+ (1,0) [0|0] "" Vector__XXX
 SG_ USM_a111_EPBR_MIA m1 : 54|1@1+ (1,0) [0|0] "" Vector__XXX
 SG_ USM_a230_s4InitError m3 : 53|1@1+ (1,0) [0|0] "" Vector__XXX
 SG_ USM_a110_GTW_MIA m1 : 53|1@1+ (1,0) [0|0] "" Vector__XXX
 SG_ USM_a229_s3InitError m3 : 52|1@1+ (1,0) [0|0] "" Vector__XXX
 SG_ USM_a109_RCM_MIA m1 : 52|1@1+ (1,0) [0|0] "" Vector__XXX
 SG_ USM_a228_s2InitError m3 : 51|1@1+ (1,0) [0|0] "" Vector__XXX
 SG_ USM_a108_DIF_MIA m1 : 51|1@1+ (1,0) [0|0] "" Vector__XXX
 SG_ USM_a227_s1InitError m3 : 50|1@1+ (1,0) [0|0] "" Vector__XXX
 SG_ USM_a107_BMS_MIA m1 : 50|1@1+ (1,0) [0|0] "" Vector__XXX
 SG_ USM_a226_s12DebugEepromInvalid m3 : 49|1@1+ (1,0) [0|0] "" Vector__XXX
 SG_ USM_a166_s12OverTemp m2 : 49|1@1+ (1,0) [0|0] "" Vector__XXX
 SG_ USM_a106_PCS_MIA m1 : 49|1@1+ (1,0) [0|0] "" Vector__XXX
 SG_ USM_a046_Task1000msError m0 : 49|1@1+ (1,0) [0|0] "" Vector__XXX
 SG_ USM_a225_s11DebugEepromInvalid m3 : 48|1@1+ (1,0) [0|0] "" Vector__XXX
 SG_ USM_a165_s11OverTemp m2 : 48|1@1+ (1,0) [0|0] "" Vector__XXX
 SG_ USM_a105_TAS_MIA m1 : 48|1@1+ (1,0) [0|0] "" Vector__XXX
 SG_ USM_a045_Task100msError m0 : 48|1@1+ (1,0) [0|0] "" Vector__XXX
 SG_ USM_a224_s10DebugEepromInvalid m3 : 47|1@1+ (1,0) [0|0] "" Vector__XXX
 SG_ USM_a164_s10OverTemp m2 : 47|1@1+ (1,0) [0|0] "" Vector__XXX
 SG_ USM_a104_DAS_MIA m1 : 47|1@1+ (1,0) [0|0] "" Vector__XXX
 SG_ USM_a044_Task10msError m0 : 47|1@1+ (1,0) [0|0] "" Vector__XXX
 SG_ USM_a223_s9DebugEepromInvalid m3 : 46|1@1+ (1,0) [0|0] "" Vector__XXX
 SG_ USM_a163_s9OverTemp m2 : 46|1@1+ (1,0) [0|0] "" Vector__XXX
 SG_ USM_a103_CP_MIA m1 : 46|1@1+ (1,0) [0|0] "" Vector__XXX
 SG_ USM_a043_Task1msError m0 : 46|1@1+ (1,0) [0|0] "" Vector__XXX
 SG_ USM_a222_s8DebugEepromInvalid m3 : 45|1@1+ (1,0) [0|0] "" Vector__XXX
 SG_ USM_a162_s8OverTemp m2 : 45|1@1+ (1,0) [0|0] "" Vector__XXX
 SG_ USM_a102_PTC_MIA m1 : 45|1@1+ (1,0) [0|0] "" Vector__XXX
 SG_ USM_a042_HighStackUsage m0 : 45|1@1+ (1,0) [0|0] "" Vector__XXX
 SG_ USM_a221_s7DebugEepromInvalid m3 : 44|1@1+ (1,0) [0|0] "" Vector__XXX
 SG_ USM_a161_s7OverTemp m2 : 44|1@1+ (1,0) [0|0] "" Vector__XXX
 SG_ USM_a101_PM_MIA m1 : 44|1@1+ (1,0) [0|0] "" Vector__XXX
 SG_ USM_a041_HighCPULoad m0 : 44|1@1+ (1,0) [0|0] "" Vector__XXX
 SG_ USM_a220_s6DebugEepromInvalid m3 : 43|1@1+ (1,0) [0|0] "" Vector__XXX
 SG_ USM_a160_s6OverTemp m2 : 43|1@1+ (1,0) [0|0] "" Vector__XXX
 SG_ USM_a100_CANbus_MIA m1 : 43|1@1+ (1,0) [0|0] "" Vector__XXX
 SG_ USM_a219_s5DebugEepromInvalid m3 : 42|1@1+ (1,0) [0|0] "" Vector__XXX
 SG_ USM_a159_s5OverTemp m2 : 42|1@1+ (1,0) [0|0] "" Vector__XXX
 SG_ USM_a099_PARK_MIA m1 : 42|1@1+ (1,0) [0|0] "" Vector__XXX
 SG_ USM_a218_s4DebugEepromInvalid m3 : 41|1@1+ (1,0) [0|0] "" Vector__XXX
 SG_ USM_a158_s4OverTemp m2 : 41|1@1+ (1,0) [0|0] "" Vector__XXX
 SG_ USM_a098_DIR_MIA m1 : 41|1@1+ (1,0) [0|0] "" Vector__XXX
 SG_ USM_a217_s3DebugEepromInvalid m3 : 40|1@1+ (1,0) [0|0] "" Vector__XXX
 SG_ USM_a157_s3OverTemp m2 : 40|1@1+ (1,0) [0|0] "" Vector__XXX
 SG_ USM_a097_CMP_MIA m1 : 40|1@1+ (1,0) [0|0] "" Vector__XXX
 SG_ USM_a216_s2DebugEepromInvalid m3 : 39|1@1+ (1,0) [0|0] "" Vector__XXX
 SG_ USM_a156_s2OverTemp m2 : 39|1@1+ (1,0) [0|0] "" Vector__XXX
 SG_ USM_a096_OCS1P_MIA m1 : 39|1@1+ (1,0) [0|0] "" Vector__XXX
 SG_ USM_a215_s1DebugEepromInvalid m3 : 38|1@1+ (1,0) [0|0] "" Vector__XXX
 SG_ USM_a155_s1OverTemp m2 : 38|1@1+ (1,0) [0|0] "" Vector__XXX
 SG_ USM_a095_CHG_MIA m1 : 38|1@1+ (1,0) [0|0] "" Vector__XXX
 SG_ USM_a214_s12NearFieldDetected m3 : 37|1@1+ (1,0) [0|0] "" Vector__XXX
 SG_ USM_a154_s12HwError m2 : 37|1@1+ (1,0) [0|0] "" Vector__XXX
 SG_ USM_a094_EPAS3P_MIA m1 : 37|1@1+ (1,0) [0|0] "" Vector__XXX
 SG_ USM_a213_s11NearFieldDetected m3 : 36|1@1+ (1,0) [0|0] "" Vector__XXX
 SG_ USM_a153_s11HwError m2 : 36|1@1+ (1,0) [0|0] "" Vector__XXX
 SG_ USM_a093_VCSEATP_MIA m1 : 36|1@1+ (1,0) [0|0] "" Vector__XXX
 SG_ USM_a212_s10NearFieldDetected m3 : 35|1@1+ (1,0) [0|0] "" Vector__XXX
 SG_ USM_a152_s10HwError m2 : 35|1@1+ (1,0) [0|0] "" Vector__XXX
 SG_ USM_a092_VCSEATD_MIA m1 : 35|1@1+ (1,0) [0|0] "" Vector__XXX
 SG_ USM_a211_s9NearFieldDetected m3 : 34|1@1+ (1,0) [0|0] "" Vector__XXX
 SG_ USM_a151_s9HwError m2 : 34|1@1+ (1,0) [0|0] "" Vector__XXX
 SG_ USM_a091_CMPD_MIA m1 : 34|1@1+ (1,0) [0|0] "" Vector__XXX
 SG_ USM_a031_UDSActive m0 : 34|1@1+ (1,0) [0|0] "" Vector__XXX
 SG_ USM_a210_s8NearFieldDetected m3 : 33|1@1+ (1,0) [0|0] "" Vector__XXX
 SG_ USM_a150_s8HwError m2 : 33|1@1+ (1,0) [0|0] "" Vector__XXX
 SG_ USM_a090_APS_MIA m1 : 33|1@1+ (1,0) [0|0] "" Vector__XXX
 SG_ USM_a030_ECULogUploadRequest m0 : 33|1@1+ (1,0) [0|0] "" Vector__XXX
 SG_ USM_a209_s7NearFieldDetected m3 : 32|1@1+ (1,0) [0|0] "" Vector__XXX
 SG_ USM_a149_s7HwError m2 : 32|1@1+ (1,0) [0|0] "" Vector__XXX
 SG_ USM_a089_IBST_MIA m1 : 32|1@1+ (1,0) [0|0] "" Vector__XXX
 SG_ USM_a029_CoreDump m0 : 32|1@1+ (1,0) [0|0] "" Vector__XXX
 SG_ USM_a208_s6NearFieldDetected m3 : 31|1@1+ (1,0) [0|0] "" Vector__XXX
 SG_ USM_a148_s6HwError m2 : 31|1@1+ (1,0) [0|0] "" Vector__XXX
 SG_ USM_a088_DIRER_MIA m1 : 31|1@1+ (1,0) [0|0] "" Vector__XXX
 SG_ USM_a207_s5NearFieldDetected m3 : 30|1@1+ (1,0) [0|0] "" Vector__XXX
 SG_ USM_a147_s5HwError m2 : 30|1@1+ (1,0) [0|0] "" Vector__XXX
 SG_ USM_a087_DIREL_MIA m1 : 30|1@1+ (1,0) [0|0] "" Vector__XXX
 SG_ USM_a206_s4NearFieldDetected m3 : 29|1@1+ (1,0) [0|0] "" Vector__XXX
 SG_ USM_a146_s4HwError m2 : 29|1@1+ (1,0) [0|0] "" Vector__XXX
 SG_ USM_a086_VCBATT_MIA m1 : 29|1@1+ (1,0) [0|0] "" Vector__XXX
 SG_ USM_a205_s3NearFieldDetected m3 : 28|1@1+ (1,0) [0|0] "" Vector__XXX
 SG_ USM_a145_s3HwError m2 : 28|1@1+ (1,0) [0|0] "" Vector__XXX
 SG_ USM_a085_CCCM_MIA m1 : 28|1@1+ (1,0) [0|0] "" Vector__XXX
 SG_ USM_a204_s2NearFieldDetected m3 : 27|1@1+ (1,0) [0|0] "" Vector__XXX
 SG_ USM_a144_s2HwError m2 : 27|1@1+ (1,0) [0|0] "" Vector__XXX
 SG_ USM_a084_TPMS_MIA m1 : 27|1@1+ (1,0) [0|0] "" Vector__XXX
 SG_ USM_a203_s1NearFieldDetected m3 : 26|1@1+ (1,0) [0|0] "" Vector__XXX
 SG_ USM_a143_s1HwError m2 : 26|1@1+ (1,0) [0|0] "" Vector__XXX
 SG_ USM_a083_VCLEFT_IPC_MIA m1 : 26|1@1+ (1,0) [0|0] "" Vector__XXX
 SG_ USM_a202_e52417Fault m3 : 25|1@1+ (1,0) [0|0] "" Vector__XXX
 SG_ USM_a142_s12ComError m2 : 25|1@1+ (1,0) [0|0] "" Vector__XXX
 SG_ USM_a082_VCRIGHT_IPC_MIA m1 : 25|1@1+ (1,0) [0|0] "" Vector__XXX
 SG_ USM_a022_TaskInitError m0 : 25|1@1+ (1,0) [0|0] "" Vector__XXX
 SG_ USM_a201_e52142Fault m3 : 24|1@1+ (1,0) [0|0] "" Vector__XXX
 SG_ USM_a141_s11ComError m2 : 24|1@1+ (1,0) [0|0] "" Vector__XXX
 SG_ USM_a021_TaskSchedulerError m0 : 24|1@1+ (1,0) [0|0] "" Vector__XXX
 SG_ USM_a200_s12Disconnected m3 : 23|1@1+ (1,0) [0|0] "" Vector__XXX
 SG_ USM_a140_s10ComError m2 : 23|1@1+ (1,0) [0|0] "" Vector__XXX
 SG_ USM_a199_s11Disconnected m3 : 22|1@1+ (1,0) [0|0] "" Vector__XXX
 SG_ USM_a139_s9ComError m2 : 22|1@1+ (1,0) [0|0] "" Vector__XXX
 SG_ USM_a198_s10Disconnected m3 : 21|1@1+ (1,0) [0|0] "" Vector__XXX
 SG_ USM_a138_s8ComError m2 : 21|1@1+ (1,0) [0|0] "" Vector__XXX
 SG_ USM_a197_s9Disconnected m3 : 20|1@1+ (1,0) [0|0] "" Vector__XXX
 SG_ USM_a137_s7ComError m2 : 20|1@1+ (1,0) [0|0] "" Vector__XXX
 SG_ USM_a196_s8Disconnected m3 : 19|1@1+ (1,0) [0|0] "" Vector__XXX
 SG_ USM_a136_s6ComError m2 : 19|1@1+ (1,0) [0|0] "" Vector__XXX
 SG_ USM_a016_NVMMRecordError m0 : 19|1@1+ (1,0) [0|0] "" Vector__XXX
 SG_ USM_a255_rearSensorsOvercurrent m4 : 18|1@1+ (1,0) [0|0] "" Vector__XXX
 SG_ USM_a195_s7Disconnected m3 : 18|1@1+ (1,0) [0|0] "" Vector__XXX
 SG_ USM_a135_s5ComError m2 : 18|1@1+ (1,0) [0|0] "" Vector__XXX
 SG_ USM_a015_NVMMError m0 : 18|1@1+ (1,0) [0|0] "" Vector__XXX
 SG_ USM_a254_frontSensorsOvercurrent m4 : 17|1@1+ (1,0) [0|0] "" Vector__XXX
 SG_ USM_a194_s6Disconnected m3 : 17|1@1+ (1,0) [0|0] "" Vector__XXX
 SG_ USM_a134_s4ComError m2 : 17|1@1+ (1,0) [0|0] "" Vector__XXX
 SG_ USM_a253_anyHwErrorSet m4 : 16|1@1+ (1,0) [0|0] "" Vector__XXX
 SG_ USM_a193_s5Disconnected m3 : 16|1@1+ (1,0) [0|0] "" Vector__XXX
 SG_ USM_a133_s3ComError m2 : 16|1@1+ (1,0) [0|0] "" Vector__XXX
 SG_ USM_a013_AlertManagerFault m0 : 16|1@1+ (1,0) [0|0] "" Vector__XXX
 SG_ USM_a252_anyComErrorSet m4 : 15|1@1+ (1,0) [0|0] "" Vector__XXX
 SG_ USM_a192_s4Disconnected m3 : 15|1@1+ (1,0) [0|0] "" Vector__XXX
 SG_ USM_a132_s2ComError m2 : 15|1@1+ (1,0) [0|0] "" Vector__XXX
 SG_ USM_a012_CPUReset m0 : 15|1@1+ (1,0) [0|0] "" Vector__XXX
 SG_ USM_a251_s12HwComErrDiagnostics m4 : 14|1@1+ (1,0) [0|0] "" Vector__XXX
 SG_ USM_a191_s3Disconnected m3 : 14|1@1+ (1,0) [0|0] "" Vector__XXX
 SG_ USM_a131_s1ComError m2 : 14|1@1+ (1,0) [0|0] "" Vector__XXX
 SG_ USM_a250_s11HwComErrDiagnostics m4 : 13|1@1+ (1,0) [0|0] "" Vector__XXX
 SG_ USM_a190_s2Disconnected m3 : 13|1@1+ (1,0) [0|0] "" Vector__XXX
 SG_ USM_a249_s10HwComErrDiagnostics m4 : 12|1@1+ (1,0) [0|0] "" Vector__XXX
 SG_ USM_a189_s1Disconnected m3 : 12|1@1+ (1,0) [0|0] "" Vector__XXX
 SG_ USM_a248_s9HwComErrDiagnostics m4 : 11|1@1+ (1,0) [0|0] "" Vector__XXX
 SG_ USM_a188_s12Blocked m3 : 11|1@1+ (1,0) [0|0] "" Vector__XXX
 SG_ USM_a247_s8HwComErrDiagnostics m4 : 10|1@1+ (1,0) [0|0] "" Vector__XXX
 SG_ USM_a187_s11Blocked m3 : 10|1@1+ (1,0) [0|0] "" Vector__XXX
 SG_ USM_a246_s7HwComErrDiagnostics m4 : 9|1@1+ (1,0) [0|0] "" Vector__XXX
 SG_ USM_a186_s10Blocked m3 : 9|1@1+ (1,0) [0|0] "" Vector__XXX
 SG_ USM_a006_CANTX_cyclicError m0 : 9|1@1+ (1,0) [0|0] "" Vector__XXX
 SG_ USM_a245_s6HwComErrDiagnostics m4 : 8|1@1+ (1,0) [0|0] "" Vector__XXX
 SG_ USM_a185_s9Blocked m3 : 8|1@1+ (1,0) [0|0] "" Vector__XXX
 SG_ USM_a005_CANTXError m0 : 8|1@1+ (1,0) [0|0] "" Vector__XXX
 SG_ USM_a244_s5HwComErrDiagnostics m4 : 7|1@1+ (1,0) [0|0] "" Vector__XXX
 SG_ USM_a184_s8Blocked m3 : 7|1@1+ (1,0) [0|0] "" Vector__XXX
 SG_ USM_a064_busSleepReqTimeout m1 : 7|1@1+ (1,0) [0|0] "" Vector__XXX
 SG_ USM_a243_s4HwComErrDiagnostics m4 : 6|1@1+ (1,0) [0|0] "" Vector__XXX
 SG_ USM_a183_s7Blocked m3 : 6|1@1+ (1,0) [0|0] "" Vector__XXX
 SG_ USM_a063_SwitchFault m1 : 6|1@1+ (1,0) [0|0] "" Vector__XXX
 SG_ USM_a003_SWAssertion m0 : 6|1@1+ (1,0) [0|0] "" Vector__XXX
 SG_ USM_a242_s3HwComErrDiagnostics m4 : 5|1@1+ (1,0) [0|0] "" Vector__XXX
 SG_ USM_a182_s6Blocked m3 : 5|1@1+ (1,0) [0|0] "" Vector__XXX
 SG_ USM_a062_XCPWasConnected m1 : 5|1@1+ (1,0) [0|0] "" Vector__XXX
 SG_ USM_a002_PowerLossReset m0 : 5|1@1+ (1,0) [0|0] "" Vector__XXX
 SG_ USM_a241_s2HwComErrDiagnostics m4 : 4|1@1+ (1,0) [0|0] "" Vector__XXX
 SG_ USM_a181_s5Blocked m3 : 4|1@1+ (1,0) [0|0] "" Vector__XXX
 SG_ USM_a061_XCPConnected m1 : 4|1@1+ (1,0) [0|0] "" Vector__XXX
 SG_ USM_a001_WatchdogReset m0 : 4|1@1+ (1,0) [0|0] "" Vector__XXX
 SG_ USM_matrixIndex M : 0|4@1+ (1,0) [0|0] "" Vector__XXX

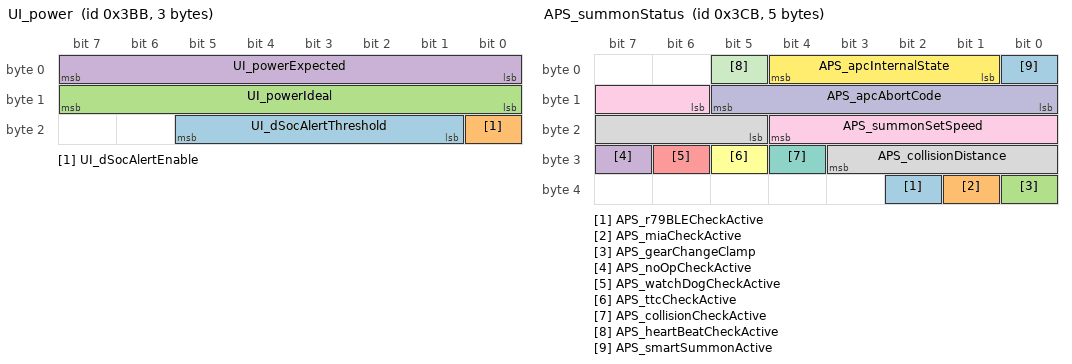
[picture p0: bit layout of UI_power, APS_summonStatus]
BO_ 955 UI_power: 3 Vector__XXX
 SG_ UI_dSocAlertThreshold : 17|5@1+ (0.1,-3) [0|0] "" Vector__XXX
 SG_ UI_dSocAlertEnable : 16|1@1+ (1,0) [0|0] "" Vector__XXX
 SG_ UI_powerIdeal : 8|8@1+ (1,0) [0|0] "" Vector__XXX
 SG_ UI_powerExpected : 0|8@1+ (1,0) [0|0] "" Vector__XXX

BO_ 956 UI_tpmsRCPsetting_3BC: 4 Vector__XXX
 SG_ UI_setRCPRear : 24|8@1+ (0.025,0) [0|0] "" Vector__XXX
 SG_ UI_setRCPFront : 16|8@1+ (0.025,0) [0|0] "" Vector__XXX

BO_ 957 VCFRONT_parkedEnergyLoss: 8 Vector__XXX
 SG_ VCFRONT_evapDryingEnergyLossSinceCharge m4 : 50|14@1+ (0.01,0) [0|0] "" Vector__XXX
 SG_ VCFRONT_evapDryingEnergyLossSinceDrive m2 : 50|14@1+ (0.01,0) [0|0] "" Vector__XXX
 SG_ VCFRONT_mobileAppEnergyLossSinceCharge m3 : 50|14@1+ (0.01,0) [0|0] "" Vector__XXX
 SG_ VCFRONT_mobileAppEnergyLossSinceDrive m1 : 50|14@1+ (0.01,0) [0|0] "" Vector__XXX
 SG_ VCFRONT_backgroundEnergyLossSinceCharge m4 : 36|14@1+ (0.01,0) [0|0] "" Vector__XXX
 SG_ VCFRONT_backgroundEnergyLossSinceDrive m2 : 36|14@1+ (0.01,0) [0|0] "" Vector__XXX
 SG_ VCFRONT_cabinOverheatEnergyLossSinceCharge m3 : 36|14@1+ (0.01,0) [0|0] "" Vector__XXX
 SG_ VCFRONT_cabinOverheatEnergyLossSinceDrive m1 : 36|14@1+ (0.01,0) [0|0] "" Vector__XXX
 SG_ VCFRONT_preconditioningEnergyLossSinceCharge m3 : 22|14@1+ (0.01,0) [0|0] "" Vector__XXX
 SG_ VCFRONT_preconditioningEnergyLossSinceDrive m1 : 22|14@1+ (0.01,0) [0|0] "" Vector__XXX
 SG_ VCFRONT_sentryModeEnergyLossSinceCharge m4 : 22|14@1+ (0.01,0) [0|0] "" Vector__XXX
 SG_ VCFRONT_sentryModeEnergyLossSinceDrive m2 : 22|14@1+ (0.01,0) [0|0] "" Vector__XXX
 SG_ VCFRONT_currentEnergyLossReason m0 : 8|3@1+ (1,0) [0|0] "" Vector__XXX
 SG_ VCFRONT_summonStandbyEnergyLossSinceCharge m4 : 8|14@1+ (0.01,0) [0|0] "" Vector__XXX
 SG_ VCFRONT_summonStandbyEnergyLossSinceDrive m2 : 8|14@1+ (0.01,0) [0|0] "" Vector__XXX
 SG_ VCFRONT_userEnergyLossSinceCharge m3 : 8|14@1+ (0.01,0) [0|0] "" Vector__XXX
 SG_ VCFRONT_userEnergyLossSinceDrive m1 : 8|14@1+ (0.01,0) [0|0] "" Vector__XXX
 SG_ VCFRONT_parkedEnergyLossState m0 : 3|3@1+ (1,0) [0|0] "" Vector__XXX
 SG_ VCFRONT_energyLossIndex M : 0|3@1+ (1,0) [0|0] "" Vector__XXX

BO_ 963 VCRIGHT_switchStatus: 8 Vector__XXX
 SG_ VCRIGHT_3RowRightBuckleSwitch m0 : 62|2@1+ (1,0) [0|0] "" Vector__XXX
 SG_ VCRIGHT_3RowLeftBuckleSwitch m0 : 60|2@1+ (1,0) [0|0] "" Vector__XXX
 SG_ VCRIGHT_hvacHeatingAllowedRight m1 : 59|1@1+ (1,0) [0|0] "" Vector__XXX
 SG_ VCRIGHT_3RowRightOccupancySwitch m0 : 58|2@1+ (1,0) [0|0] "" Vector__XXX
 SG_ VCRIGHT_3RowLeftOccupancySwitch m0 : 56|2@1+ (1,0) [0|0] "" Vector__XXX
 SG_ VCRIGHT_frontSeatResistiveOccupancy m1 : 54|2@1+ (1,0) [0|0] "" Vector__XXX
 SG_ VCRIGHT_rearRightOccupancySwitch m0 : 54|2@1+ (1,0) [0|0] "" Vector__XXX
 SG_ VCRIGHT_liftgateShutfaceSwitchPressed m0 : 53|1@1+ (1,0) [0|0] "" Vector__XXX
 SG_ VCRIGHT_btnWindowSwPackAutoDwnRR m0 : 52|1@1+ (1,0) [0|0] "" Vector__XXX
 SG_ VCRIGHT_btnWindowSwPackDownRR m0 : 51|1@1+ (1,0) [0|0] "" Vector__XXX
 SG_ VCRIGHT_btnWindowSwPackAutoUpRR m0 : 50|1@1+ (1,0) [0|0] "" Vector__XXX
 SG_ VCRIGHT_btnWindowSwPackUpRR m0 : 49|1@1+ (1,0) [0|0] "" Vector__XXX
 SG_ VCRIGHT_trunkExtReleasePressed m0 : 48|1@1+ (1,0) [0|0] "" Vector__XXX
 SG_ VCRIGHT_gloveboxLightCurrent m1 : 47|5@1+ (2,0) [0|0] "" Vector__XXX
 SG_ VCRIGHT_rearRightBuckleSwitch m0 : 46|2@1+ (1,0) [0|0] "" Vector__XXX
 SG_ VCRIGHT_rearCenterBuckleSwitch m0 : 44|2@1+ (1,0) [0|0] "" Vector__XXX
 SG_ VCRIGHT_frontOccupancySwitch m0 : 42|2@1+ (1,0) [0|0] "" Vector__XXX
 SG_ VCRIGHT_frontBuckleSwitch m0 : 40|2@1+ (1,0) [0|0] "" Vector__XXX
 SG_ VCRIGHT_rearHandlePWM m1 : 40|7@1+ (1,0) [0|0] "" Vector__XXX
 SG_ VCRIGHT_btnWindowSwPackAutoDwnLR m0 : 39|1@1+ (1,0) [0|0] "" Vector__XXX
 SG_ VCRIGHT_hvacHeatingAllowedLeft m1 : 39|1@1+ (1,0) [0|0] "" Vector__XXX
 SG_ VCRIGHT_btnWindowSwPackDownLR m0 : 38|1@1+ (1,0) [0|0] "" Vector__XXX
 SG_ VCRIGHT_btnWindowSwPackAutoUpLR m0 : 37|1@1+ (1,0) [0|0] "" Vector__XXX
 SG_ VCRIGHT_btnWindowSwPackUpLR m0 : 36|1@1+ (1,0) [0|0] "" Vector__XXX
 SG_ VCRIGHT_btnWindowSwPackAutoDwnLF m0 : 35|1@1+ (1,0) [0|0] "" Vector__XXX
 SG_ VCRIGHT_btnWindowSwPackDownLF m0 : 34|1@1+ (1,0) [0|0] "" Vector__XXX
 SG_ VCRIGHT_btnWindowSwPackAutoUpLF m0 : 33|1@1+ (1,0) [0|0] "" Vector__XXX
 SG_ VCRIGHT_btnWindowSwPackUpLF m0 : 32|1@1+ (1,0) [0|0] "" Vector__XXX
 SG_ VCRIGHT_frontHandlePWM m1 : 32|7@1+ (1,0) [0|0] "" Vector__XXX
 SG_ VCRIGHT_btnWindowAutoDownRR m0 : 31|1@1+ (1,0) [0|0] "" Vector__XXX
 SG_ VCRIGHT_btnWindowDownRR m0 : 30|1@1+ (1,0) [0|0] "" Vector__XXX
 SG_ VCRIGHT_btnWindowAutoUpRR m0 : 29|1@1+ (1,0) [0|0] "" Vector__XXX
 SG_ VCRIGHT_btnWindowUpRR m0 : 28|1@1+ (1,0) [0|0] "" Vector__XXX
 SG_ VCRIGHT_2RowSeatBackrestFoldSwitch m1 : 27|1@1+ (1,0) [0|0] "" Vector__XXX
 SG_ VCRIGHT_btnWindowAutoDownRF m0 : 27|1@1+ (1,0) [0|0] "" Vector__XXX
 SG_ VCRIGHT_2RowSeatReclineSwitch m1 : 26|1@1+ (1,0) [0|0] "" Vector__XXX
 SG_ VCRIGHT_btnWindowDownRF m0 : 26|1@1+ (1,0) [0|0] "" Vector__XXX
 SG_ VCRIGHT_btnWindowAutoUpRF m0 : 25|1@1+ (1,0) [0|0] "" Vector__XXX
 SG_ VCRIGHT_btnWindowUpRF m0 : 24|1@1+ (1,0) [0|0] "" Vector__XXX
 SG_ VCRIGHT_frontSeatLumbarOut m1 : 24|2@1+ (1,0) [0|0] "" Vector__XXX
 SG_ VCRIGHT_frontSeatLumbarIn m1 : 22|2@1+ (1,0) [0|0] "" Vector__XXX
 SG_ VCRIGHT_frontSeatLumbarUp m1 : 20|2@1+ (1,0) [0|0] "" Vector__XXX
 SG_ VCRIGHT_frontSeatLumbarDown m1 : 18|2@1+ (1,0) [0|0] "" Vector__XXX
 SG_ VCRIGHT_frontSeatBackrestForward m1 : 16|2@1+ (1,0) [0|0] "" Vector__XXX
 SG_ VCRIGHT_frontSeatBackrestBack m1 : 14|2@1+ (1,0) [0|0] "" Vector__XXX
 SG_ VCRIGHT_frontSeatLiftUp m1 : 12|2@1+ (1,0) [0|0] "" Vector__XXX
 SG_ VCRIGHT_frontSeatLiftDown m1 : 10|2@1+ (1,0) [0|0] "" Vector__XXX
 SG_ VCRIGHT_frontSeatTiltUp m1 : 8|2@1+ (1,0) [0|0] "" Vector__XXX
 SG_ VCRIGHT_frontSeatTiltDown m1 : 6|2@1+ (1,0) [0|0] "" Vector__XXX
 SG_ VCRIGHT_frontSeatTrackForward m1 : 4|2@1+ (1,0) [0|0] "" Vector__XXX
 SG_ VCRIGHT_frontSeatTrackBack m1 : 2|2@1+ (1,0) [0|0] "" Vector__XXX
 SG_ VCRIGHT_trunkExtReleasePressedPersist m1 : 1|1@1+ (1,0) [0|0] "" Vector__XXX
 SG_ VCRIGHT_switchStatusIndex M : 0|1@1+ (1,0) [0|0] "" Vector__XXX

BO_ 971 APS_summonStatus: 5 Vector__XXX
 SG_ APS_r79BLECheckActive : 34|1@1+ (1,0) [0|0] "" Vector__XXX
 SG_ APS_miaCheckActive : 33|1@1+ (1,0) [0|0] "" Vector__XXX
 SG_ APS_gearChangeClamp : 32|1@1+ (1,0) [0|0] "" Vector__XXX
 SG_ APS_noOpCheckActive : 31|1@1+ (1,0) [0|0] "" Vector__XXX
 SG_ APS_watchDogCheckActive : 30|1@1+ (1,0) [0|0] "" Vector__XXX
 SG_ APS_ttcCheckActive : 29|1@1+ (1,0) [0|0] "" Vector__XXX
 SG_ APS_collisionCheckActive : 28|1@1+ (1,0) [0|0] "" Vector__XXX
 SG_ APS_collisionDistance : 21|7@1+ (0.05,0) [0|0] "" Vector__XXX
 SG_ APS_summonSetSpeed : 14|7@1+ (0.1,0) [0|0] "" Vector__XXX
 SG_ APS_apcAbortCode : 8|6@1+ (1,0) [0|0] "" Vector__XXX
 SG_ APS_heartBeatCheckActive : 5|1@1+ (1,0) [0|0] "" Vector__XXX
 SG_ APS_apcInternalState : 1|4@1+ (1,0) [0|0] "" Vector__XXX
 SG_ APS_smartSummonActive : 0|1@1+ (1,0) [0|0] "" Vector__XXX

BO_ 972 APS_status: 8 Vector__XXX
 SG_ APS_apbActivePlannerType : 61|3@1+ (1,0) [0|0] "" Vector__XXX
 SG_ APS_appActivePlannerType : 58|3@1+ (1,0) [0|0] "" Vector__XXX
 SG_ APS_otherArbState : 55|3@1+ (1,0) [0|0] "" Vector__XXX
 SG_ APS_socPowerOperatingMode : 53|2@1+ (1,0) [0|0] "" Vector__XXX
 SG_ APS_arbState : 50|3@1+ (1,0) [0|0] "" Vector__XXX
 SG_ APS_gpsAntennaState : 48|2@1+ (1,0) [0|0] "" Vector__XXX
 SG_ APS_autosummonAlert : 47|1@1+ (1,0) [0|0] "" Vector__XXX
 SG_ APS_autosummonCounter : 44|3@1+ (1,0) [0|0] "" Vector__XXX
 SG_ APS_heaterStateDebug : 41|3@1+ (1,0) [0|0] "" Vector__XXX
 SG_ APS_apbPowerStateReason : 37|4@1+ (1,0) [0|0] "" Vector__XXX
 SG_ APS_apbPowerStateRequest : 35|2@1+ (1,0) [0|0] "" Vector__XXX
 SG_ APS_appPowerStateReason : 31|4@1+ (1,0) [0|0] "" Vector__XXX
 SG_ APS_appPowerStateRequest : 29|2@1+ (1,0) [0|0] "" Vector__XXX
 SG_ APS_locLimitReason : 26|3@1+ (1,0) [0|0] "" Vector__XXX
 SG_ APS_statusCounter : 22|4@1+ (1,0) [0|0] "" Vector__XXX
 SG_ APS_apbGpioState : 20|2@1+ (1,0) [0|0] "" Vector__XXX
 SG_ APS_apbStatusMonitorState : 16|3@1+ (1,0) [0|0] "" Vector__XXX
 SG_ APS_switchState : 15|1@1+ (1,0) [0|0] "" Vector__XXX
 SG_ APS_eacInternalState : 12|3@1+ (1,0) [0|0] "" Vector__XXX
 SG_ APS_appGpioState : 10|2@1+ (1,0) [0|0] "" Vector__XXX
 SG_ APS_canMaster : 8|2@1+ (1,0) [0|0] "" Vector__XXX
 SG_ APS_vehBehaviorState : 4|4@1+ (1,0) [0|0] "" Vector__XXX
 SG_ APS_appStatusMonitorState : 0|3@1+ (1,0) [0|0] "" Vector__XXX

BO_ 974 VCBATT1_alertMatrix: 8 Vector__XXX
 SG_ VCBATT1_a060_engineeringBuild m0 : 63|1@1+ (1,0) [0|0] "" Vector__XXX
 SG_ VCBATT1_a120_DI_DRIVE_MIA m1 : 63|1@1+ (1,0) [0|0] "" Vector__XXX
 SG_ VCBATT1_a180_DCDCNotSupportingLV m2 : 63|1@1+ (1,0) [0|0] "" Vector__XXX
 SG_ VCBATT1_a420_LVBridgeRetryInDriv m6 : 63|1@1+ (1,0) [0|0] "" Vector__XXX
 SG_ VCBATT1_a600_currentSensorMismat m9 : 63|1@1+ (1,0) [0|0] "" Vector__XXX
 SG_ VCBATT1_a059_inputResistanceHigh m0 : 62|1@1+ (1,0) [0|0] "" Vector__XXX
 SG_ VCBATT1_a119_SCCM_MIA m1 : 62|1@1+ (1,0) [0|0] "" Vector__XXX
 SG_ VCBATT1_a359_postPORExcessiveAh m5 : 62|1@1+ (1,0) [0|0] "" Vector__XXX
 SG_ VCBATT1_a419_TLVBMS_BrickSocLow m6 : 62|1@1+ (1,0) [0|0] "" Vector__XXX
 SG_ VCBATT1_a479_LVBMS_ECPA_NotClose m7 : 62|1@1+ (1,0) [0|0] "" Vector__XXX
 SG_ VCBATT1_a599_LVBatteryTypeUnsupp m9 : 62|1@1+ (1,0) [0|0] "" Vector__XXX
 SG_ VCBATT1_a058_inputRHighSyncDebug m0 : 61|1@1+ (1,0) [0|0] "" Vector__XXX
 SG_ VCBATT1_a118_VCFRONT_MIA m1 : 61|1@1+ (1,0) [0|0] "" Vector__XXX
 SG_ VCBATT1_a418_TLVBMS_BrickOverVol m6 : 61|1@1+ (1,0) [0|0] "" Vector__XXX
 SG_ VCBATT1_a478_LVBMS_MOSFET_Open m7 : 61|1@1+ (1,0) [0|0] "" Vector__XXX
 SG_ VCBATT1_a117_VCLEFT_MIA m1 : 60|1@1+ (1,0) [0|0] "" Vector__XXX
 SG_ VCBATT1_a297_TLVBMS_BmbHwOverTem m4 : 60|1@1+ (1,0) [0|0] "" Vector__XXX
 SG_ VCBATT1_a417_TLVBMS_BrickOverVol m6 : 60|1@1+ (1,0) [0|0] "" Vector__XXX
 SG_ VCBATT1_a477_LVBatteryUnrecovera m7 : 60|1@1+ (1,0) [0|0] "" Vector__XXX
 SG_ VCBATT1_a116_VCRIGHT_MIA m1 : 59|1@1+ (1,0) [0|0] "" Vector__XXX
 SG_ VCBATT1_a236_hvcDualPowerSelfTes m3 : 59|1@1+ (1,0) [0|0] "" Vector__XXX
 SG_ VCBATT1_a416_TLVBMS_BrickOverDis m6 : 59|1@1+ (1,0) [0|0] "" Vector__XXX
 SG_ VCBATT1_a476_LVBMSMIA m7 : 59|1@1+ (1,0) [0|0] "" Vector__XXX
 SG_ VCBATT1_a115_VCSEC_MIA m1 : 58|1@1+ (1,0) [0|0] "" Vector__XXX
 SG_ VCBATT1_a235_dualPowerLoadsSelfT m3 : 58|1@1+ (1,0) [0|0] "" Vector__XXX
 SG_ VCBATT1_a415_undervoltageSelfTes m6 : 58|1@1+ (1,0) [0|0] "" Vector__XXX
 SG_ VCBATT1_a475_vnf1248Fault m7 : 58|1@1+ (1,0) [0|0] "" Vector__XXX
 SG_ VCBATT1_a595_voltageSensorMismat m9 : 58|1@1+ (1,0) [0|0] "" Vector__XXX
 SG_ VCBATT1_a114_ESP_MIA m1 : 57|1@1+ (1,0) [0|0] "" Vector__XXX
 SG_ VCBATT1_a414_undervoltageSelfTes m6 : 57|1@1+ (1,0) [0|0] "" Vector__XXX
 SG_ VCBATT1_a113_UI_MIA m1 : 56|1@1+ (1,0) [0|0] "" Vector__XXX
 SG_ VCBATT1_a413_TLVBMS_BmbVrefWarni m6 : 56|1@1+ (1,0) [0|0] "" Vector__XXX
 SG_ VCBATT1_a533_TLVBMS_MosfetOverTe m8 : 56|1@1+ (1,0) [0|0] "" Vector__XXX
 SG_ VCBATT1_a593_vcleftFastBlowPower m9 : 56|1@1+ (1,0) [0|0] "" Vector__XXX
 SG_ VCBATT1_a112_EPBL_MIA m1 : 55|1@1+ (1,0) [0|0] "" Vector__XXX
 SG_ VCBATT1_a412_dcrData3 m6 : 55|1@1+ (1,0) [0|0] "" Vector__XXX
 SG_ VCBATT1_a592_vcleftCurvePowerCut m9 : 55|1@1+ (1,0) [0|0] "" Vector__XXX
 SG_ VCBATT1_a111_EPBR_MIA m1 : 54|1@1+ (1,0) [0|0] "" Vector__XXX
 SG_ VCBATT1_a411_LVBatteryDataCollec m6 : 54|1@1+ (1,0) [0|0] "" Vector__XXX
 SG_ VCBATT1_a110_GTW_MIA m1 : 53|1@1+ (1,0) [0|0] "" Vector__XXX
 SG_ VCBATT1_a230_ingoingOvercurrentS m3 : 53|1@1+ (1,0) [0|0] "" Vector__XXX
 SG_ VCBATT1_a410_LVBatteryDataCollec m6 : 53|1@1+ (1,0) [0|0] "" Vector__XXX
 SG_ VCBATT1_a229_LVHealthCompromised m3 : 52|1@1+ (1,0) [0|0] "" Vector__XXX
 SG_ VCBATT1_a529_discnctdBatteryStat m8 : 52|1@1+ (1,0) [0|0] "" Vector__XXX
 SG_ VCBATT1_a589_vcleftFastBlowDetec m9 : 52|1@1+ (1,0) [0|0] "" Vector__XXX
 SG_ VCBATT1_a108_DIF_MIA m1 : 51|1@1+ (1,0) [0|0] "" Vector__XXX
 SG_ VCBATT1_a228_overcurrentSelfTest m3 : 51|1@1+ (1,0) [0|0] "" Vector__XXX
 SG_ VCBATT1_a408_standbyChargeProfil m6 : 51|1@1+ (1,0) [0|0] "" Vector__XXX
 SG_ VCBATT1_a528_LVBatteryCommsDiscn m8 : 51|1@1+ (1,0) [0|0] "" Vector__XXX
 SG_ VCBATT1_a588_vcleftPwrRationalit m9 : 51|1@1+ (1,0) [0|0] "" Vector__XXX
 SG_ VCBATT1_a107_BMS_MIA m1 : 50|1@1+ (1,0) [0|0] "" Vector__XXX
 SG_ VCBATT1_a227_overcurrentSelfTest m3 : 50|1@1+ (1,0) [0|0] "" Vector__XXX
 SG_ VCBATT1_a407_dcrMilliOhmsAboveTh m6 : 50|1@1+ (1,0) [0|0] "" Vector__XXX
 SG_ VCBATT1_a527_LVBatteryCellImbala m8 : 50|1@1+ (1,0) [0|0] "" Vector__XXX
 SG_ VCBATT1_a587_externalLVPowerSupp m9 : 50|1@1+ (1,0) [0|0] "" Vector__XXX
 SG_ VCBATT1_a046_Task1000msError m0 : 49|1@1+ (1,0) [0|0] "" Vector__XXX
 SG_ VCBATT1_a106_PCS_MIA m1 : 49|1@1+ (1,0) [0|0] "" Vector__XXX
 SG_ VCBATT1_a226_overcurrentSelfTest m3 : 49|1@1+ (1,0) [0|0] "" Vector__XXX
 SG_ VCBATT1_a406_dcrData2 m6 : 49|1@1+ (1,0) [0|0] "" Vector__XXX
 SG_ VCBATT1_a045_Task100msError m0 : 48|1@1+ (1,0) [0|0] "" Vector__XXX
 SG_ VCBATT1_a105_TAS_MIA m1 : 48|1@1+ (1,0) [0|0] "" Vector__XXX
 SG_ VCBATT1_a165_unxpctdEFuseLckout m2 : 48|1@1+ (1,0) [0|0] "" Vector__XXX
 SG_ VCBATT1_a225_overcurrentSelfTest m3 : 48|1@1+ (1,0) [0|0] "" Vector__XXX
 SG_ VCBATT1_a405_dcrData1 m6 : 48|1@1+ (1,0) [0|0] "" Vector__XXX
 SG_ VCBATT1_a525_LVBatterySWMisconfi m8 : 48|1@1+ (1,0) [0|0] "" Vector__XXX
 SG_ VCBATT1_a044_Task10msError m0 : 47|1@1+ (1,0) [0|0] "" Vector__XXX
 SG_ VCBATT1_a104_DAS_MIA m1 : 47|1@1+ (1,0) [0|0] "" Vector__XXX
 SG_ VCBATT1_a164_eFuseLckoutMissing m2 : 47|1@1+ (1,0) [0|0] "" Vector__XXX
 SG_ VCBATT1_a224_overcurrentLoadshed m3 : 47|1@1+ (1,0) [0|0] "" Vector__XXX
 SG_ VCBATT1_a404_resistanceEstimatio m6 : 47|1@1+ (1,0) [0|0] "" Vector__XXX
 SG_ VCBATT1_a043_Task1msError m0 : 46|1@1+ (1,0) [0|0] "" Vector__XXX
 SG_ VCBATT1_a103_CP_MIA m1 : 46|1@1+ (1,0) [0|0] "" Vector__XXX
 SG_ VCBATT1_a223_bridgeOvervoltageSe m3 : 46|1@1+ (1,0) [0|0] "" Vector__XXX
 SG_ VCBATT1_a403_chargeExitHardCurre m6 : 46|1@1+ (1,0) [0|0] "" Vector__XXX
 SG_ VCBATT1_a042_HighStackUsage m0 : 45|1@1+ (1,0) [0|0] "" Vector__XXX
 SG_ VCBATT1_a402_LVBatteryCannotSupp m6 : 45|1@1+ (1,0) [0|0] "" Vector__XXX
 SG_ VCBATT1_a462_LVBMSFault m7 : 45|1@1+ (1,0) [0|0] "" Vector__XXX
 SG_ VCBATT1_a582_goodForPCSPowerCycl m9 : 45|1@1+ (1,0) [0|0] "" Vector__XXX
 SG_ VCBATT1_a041_HighCPULoad m0 : 44|1@1+ (1,0) [0|0] "" Vector__XXX
 SG_ VCBATT1_a221_reverseBatteryFault m3 : 44|1@1+ (1,0) [0|0] "" Vector__XXX
 SG_ VCBATT1_a401_deadLVMinimalAhDisc m6 : 44|1@1+ (1,0) [0|0] "" Vector__XXX
 SG_ VCBATT1_a461_TLVBMS_SocHighAhErr m7 : 44|1@1+ (1,0) [0|0] "" Vector__XXX
 SG_ VCBATT1_a521_vcleftEFuseLoadShed m8 : 44|1@1+ (1,0) [0|0] "" Vector__XXX
 SG_ VCBATT1_a581_harnessResistanceIn m9 : 44|1@1+ (1,0) [0|0] "" Vector__XXX
 SG_ VCBATT1_a040_Backtrace m0 : 43|1@1+ (1,0) [0|0] "" Vector__XXX
 SG_ VCBATT1_a100_CANbus_MIA m1 : 43|1@1+ (1,0) [0|0] "" Vector__XXX
 SG_ VCBATT1_a220_LVUnhealthy m3 : 43|1@1+ (1,0) [0|0] "" Vector__XXX
 SG_ VCBATT1_a400_TLVBMS_BmbVrefBad m6 : 43|1@1+ (1,0) [0|0] "" Vector__XXX
 SG_ VCBATT1_a580_rightHeadlightEFuse m9 : 43|1@1+ (1,0) [0|0] "" Vector__XXX
 SG_ VCBATT1_a039_ProtFaultAddress m0 : 42|1@1+ (1,0) [0|0] "" Vector__XXX
 SG_ VCBATT1_a219_LVVoltFloorRchd m3 : 42|1@1+ (1,0) [0|0] "" Vector__XXX
 SG_ VCBATT1_a038_ProtFaultInfo m0 : 41|1@1+ (1,0) [0|0] "" Vector__XXX
 SG_ VCBATT1_a098_DIR_MIA m1 : 41|1@1+ (1,0) [0|0] "" Vector__XXX
 SG_ VCBATT1_a278_TLVBMS_BmbHwOverCur m4 : 41|1@1+ (1,0) [0|0] "" Vector__XXX
 SG_ VCBATT1_a518_LVBMSFault_MOS_Open m8 : 41|1@1+ (1,0) [0|0] "" Vector__XXX
 SG_ VCBATT1_a037_MemManageFault m0 : 40|1@1+ (1,0) [0|0] "" Vector__XXX
 SG_ VCBATT1_a217_LVProtectionSelfTes m3 : 40|1@1+ (1,0) [0|0] "" Vector__XXX
 SG_ VCBATT1_a277_TLVBMS_BmbStatusReg m4 : 40|1@1+ (1,0) [0|0] "" Vector__XXX
 SG_ VCBATT1_a036_UnknownIrq m0 : 39|1@1+ (1,0) [0|0] "" Vector__XXX
 SG_ VCBATT1_a096_OCS1P_MIA m1 : 39|1@1+ (1,0) [0|0] "" Vector__XXX
 SG_ VCBATT1_a216_powerCutoffImminent m3 : 39|1@1+ (1,0) [0|0] "" Vector__XXX
 SG_ VCBATT1_a276_TLVBMS_BmbDataInteg m4 : 39|1@1+ (1,0) [0|0] "" Vector__XXX
 SG_ VCBATT1_a576_mcuLogicEFuseTrip m9 : 39|1@1+ (1,0) [0|0] "" Vector__XXX
 SG_ VCBATT1_a215_selfTestOrchestrato m3 : 38|1@1+ (1,0) [0|0] "" Vector__XXX
 SG_ VCBATT1_a275_TLVBMS_BmbCommunica m4 : 38|1@1+ (1,0) [0|0] "" Vector__XXX
 SG_ VCBATT1_a515_LVBMSFault_MOS_Open m8 : 38|1@1+ (1,0) [0|0] "" Vector__XXX
 SG_ VCBATT1_a575_vbatFusedLoadShedEF m9 : 38|1@1+ (1,0) [0|0] "" Vector__XXX
 SG_ VCBATT1_a514_LVBMSFault_MOS_Open m8 : 37|1@1+ (1,0) [0|0] "" Vector__XXX
 SG_ VCBATT1_a213_LVOvercharge m3 : 36|1@1+ (1,0) [0|0] "" Vector__XXX
 SG_ VCBATT1_a513_LVBMSFault_MOS_Open m8 : 36|1@1+ (1,0) [0|0] "" Vector__XXX
 SG_ VCBATT1_a573_radarEFuseTrip m9 : 36|1@1+ (1,0) [0|0] "" Vector__XXX
 SG_ VCBATT1_a212_IBSOverTemp m3 : 35|1@1+ (1,0) [0|0] "" Vector__XXX
 SG_ VCBATT1_a392_TLVBMS_BmbHwUnderVo m6 : 35|1@1+ (1,0) [0|0] "" Vector__XXX
 SG_ VCBATT1_a512_LVBMSFault_MOS_Open m8 : 35|1@1+ (1,0) [0|0] "" Vector__XXX
 SG_ VCBATT1_a031_UDSActive m0 : 34|1@1+ (1,0) [0|0] "" Vector__XXX
 SG_ VCBATT1_a091_CMPD_MIA m1 : 34|1@1+ (1,0) [0|0] "" Vector__XXX
 SG_ VCBATT1_a030_ECULogUploadRequest m0 : 33|1@1+ (1,0) [0|0] "" Vector__XXX
 SG_ VCBATT1_a090_APS_MIA m1 : 33|1@1+ (1,0) [0|0] "" Vector__XXX
 SG_ VCBATT1_a510_LVBatteryRecoveryTi m8 : 33|1@1+ (1,0) [0|0] "" Vector__XXX
 SG_ VCBATT1_a029_CoreDump m0 : 32|1@1+ (1,0) [0|0] "" Vector__XXX
 SG_ VCBATT1_a509_eFuseASICManagerSta m8 : 32|1@1+ (1,0) [0|0] "" Vector__XXX
 SG_ VCBATT1_a629_TLVBMS_PackTemperat m10 : 32|1@1+ (1,0) [0|0] "" Vector__XXX
 SG_ VCBATT1_a028_UsageFault m0 : 31|1@1+ (1,0) [0|0] "" Vector__XXX
 SG_ VCBATT1_a388_shortedCell m6 : 31|1@1+ (1,0) [0|0] "" Vector__XXX
 SG_ VCBATT1_a508_TLVBMS_ImpedanceGro m8 : 31|1@1+ (1,0) [0|0] "" Vector__XXX
 SG_ VCBATT1_a628_TLVBMS_BmbThermisto m10 : 31|1@1+ (1,0) [0|0] "" Vector__XXX
 SG_ VCBATT1_a387_shortedCellInstc m6 : 30|1@1+ (1,0) [0|0] "" Vector__XXX
 SG_ VCBATT1_a086_VCBATT_MIA m1 : 29|1@1+ (1,0) [0|0] "" Vector__XXX
 SG_ VCBATT1_a446_LVBatteryUnrecovera m7 : 29|1@1+ (1,0) [0|0] "" Vector__XXX
 SG_ VCBATT1_a205_overvoltageProtecti m3 : 28|1@1+ (1,0) [0|0] "" Vector__XXX
 SG_ VCBATT1_a144_EPAS3S_MIA m2 : 27|1@1+ (1,0) [0|0] "" Vector__XXX
 SG_ VCBATT1_a204_undervoltageLoadshe m3 : 27|1@1+ (1,0) [0|0] "" Vector__XXX
 SG_ VCBATT1_a443_TLVBMS_BmbDieOverTe m7 : 26|1@1+ (1,0) [0|0] "" Vector__XXX
 SG_ VCBATT1_a503_TLVBMS_BrickExtende m8 : 26|1@1+ (1,0) [0|0] "" Vector__XXX
 SG_ VCBATT1_a022_TaskInitError m0 : 25|1@1+ (1,0) [0|0] "" Vector__XXX
 SG_ VCBATT1_a082_VCFRONT2_MIA m1 : 25|1@1+ (1,0) [0|0] "" Vector__XXX
 SG_ VCBATT1_a442_TLVBMS_SocChange m7 : 25|1@1+ (1,0) [0|0] "" Vector__XXX
 SG_ VCBATT1_a502_TLVBMS_WeakShortImp m8 : 25|1@1+ (1,0) [0|0] "" Vector__XXX
 SG_ VCBATT1_a562_LVBMSModuleOvertemp m9 : 25|1@1+ (1,0) [0|0] "" Vector__XXX
 SG_ VCBATT1_a021_TaskSchedulerError m0 : 24|1@1+ (1,0) [0|0] "" Vector__XXX
 SG_ VCBATT1_a081_VCFRONT1_MIA m1 : 24|1@1+ (1,0) [0|0] "" Vector__XXX
 SG_ VCBATT1_a441_TLVBMS_ResetNeededF m7 : 24|1@1+ (1,0) [0|0] "" Vector__XXX
 SG_ VCBATT1_a561_LVBMSEFuseOvertempe m9 : 24|1@1+ (1,0) [0|0] "" Vector__XXX
 SG_ VCBATT1_a080_VCFRONT0_MIA m1 : 23|1@1+ (1,0) [0|0] "" Vector__XXX
 SG_ VCBATT1_a260_deadLVBattery m4 : 23|1@1+ (1,0) [0|0] "" Vector__XXX
 SG_ VCBATT1_a440_TLVBMS_PackSNInvali m7 : 23|1@1+ (1,0) [0|0] "" Vector__XXX
 SG_ VCBATT1_a019_BusFault m0 : 22|1@1+ (1,0) [0|0] "" Vector__XXX
 SG_ VCBATT1_a079_VCBATT2_MIA m1 : 22|1@1+ (1,0) [0|0] "" Vector__XXX
 SG_ VCBATT1_a259_LVVoltageDropOnHigh m4 : 22|1@1+ (1,0) [0|0] "" Vector__XXX
 SG_ VCBATT1_a379_shortedCellTestRunD m6 : 22|1@1+ (1,0) [0|0] "" Vector__XXX
 SG_ VCBATT1_a439_TLVBMS_PackOverTemp m7 : 22|1@1+ (1,0) [0|0] "" Vector__XXX
 SG_ VCBATT1_a559_LVBatteryLowSOC m9 : 22|1@1+ (1,0) [0|0] "" Vector__XXX
 SG_ VCBATT1_a018_HardFault m0 : 21|1@1+ (1,0) [0|0] "" Vector__XXX
 SG_ VCBATT1_a078_VCBATT1_MIA m1 : 21|1@1+ (1,0) [0|0] "" Vector__XXX
 SG_ VCBATT1_a258_resistanceEstimatio m4 : 21|1@1+ (1,0) [0|0] "" Vector__XXX
 SG_ VCBATT1_a438_TLVBMS_PackOverTemp m7 : 21|1@1+ (1,0) [0|0] "" Vector__XXX
 SG_ VCBATT1_a498_TLVBMS_ImpedanceTes m8 : 21|1@1+ (1,0) [0|0] "" Vector__XXX
 SG_ VCBATT1_a017_NVMMStatusDbg m0 : 20|1@1+ (1,0) [0|0] "" Vector__XXX
 SG_ VCBATT1_a077_VCBATT0_MIA m1 : 20|1@1+ (1,0) [0|0] "" Vector__XXX
 SG_ VCBATT1_a437_TLVBMS_NvmRegistrat m7 : 20|1@1+ (1,0) [0|0] "" Vector__XXX
 SG_ VCBATT1_a497_LVBatteryWarnDiscon m8 : 20|1@1+ (1,0) [0|0] "" Vector__XXX
 SG_ VCBATT1_a617_APP_MIA m10 : 20|1@1+ (1,0) [0|0] "" Vector__XXX
 SG_ VCBATT1_a016_NVMMRecordError m0 : 19|1@1+ (1,0) [0|0] "" Vector__XXX
 SG_ VCBATT1_a196_discnctdLVBattery m3 : 19|1@1+ (1,0) [0|0] "" Vector__XXX
 SG_ VCBATT1_a376_controllerWakeupDeb m6 : 19|1@1+ (1,0) [0|0] "" Vector__XXX
 SG_ VCBATT1_a436_TLVBMS_DischargeOve m7 : 19|1@1+ (1,0) [0|0] "" Vector__XXX
 SG_ VCBATT1_a496_LVBatteryExitDriveW m8 : 19|1@1+ (1,0) [0|0] "" Vector__XXX
 SG_ VCBATT1_a556_falseTriggerOfDiscn m9 : 19|1@1+ (1,0) [0|0] "" Vector__XXX
 SG_ VCBATT1_a015_NVMMError m0 : 18|1@1+ (1,0) [0|0] "" Vector__XXX
 SG_ VCBATT1_a435_TLVBMS_DchgCurrentL m7 : 18|1@1+ (1,0) [0|0] "" Vector__XXX
 SG_ VCBATT1_a495_LVBatteryRecoveryBl m8 : 18|1@1+ (1,0) [0|0] "" Vector__XXX
 SG_ VCBATT1_a555_LVBatteryCellRebala m9 : 18|1@1+ (1,0) [0|0] "" Vector__XXX
 SG_ VCBATT1_a615_TLVBMS_BatteryHeate m10 : 18|1@1+ (1,0) [0|0] "" Vector__XXX
 SG_ VCBATT1_a134_hvContactorsEFuseTr m2 : 17|1@1+ (1,0) [0|0] "" Vector__XXX
 SG_ VCBATT1_a434_TLVBMS_ConfigInitFa m7 : 17|1@1+ (1,0) [0|0] "" Vector__XXX
 SG_ VCBATT1_a494_LVBatteryTempBlocki m8 : 17|1@1+ (1,0) [0|0] "" Vector__XXX
 SG_ VCBATT1_a013_AlertManagerFault m0 : 16|1@1+ (1,0) [0|0] "" Vector__XXX
 SG_ VCBATT1_a133_BRAKE_MIA m2 : 16|1@1+ (1,0) [0|0] "" Vector__XXX
 SG_ VCBATT1_a253_maxChrgeSssionTmeou m4 : 16|1@1+ (1,0) [0|0] "" Vector__XXX
 SG_ VCBATT1_a433_TLVBMS_ConfigFromBm m7 : 16|1@1+ (1,0) [0|0] "" Vector__XXX
 SG_ VCBATT1_a493_TLVBMS_SocImbalance m8 : 16|1@1+ (1,0) [0|0] "" Vector__XXX
 SG_ VCBATT1_a012_CPUReset m0 : 15|1@1+ (1,0) [0|0] "" Vector__XXX
 SG_ VCBATT1_a132_iBoosterEFuseTrip m2 : 15|1@1+ (1,0) [0|0] "" Vector__XXX
 SG_ VCBATT1_a252_controllerWakeup m4 : 15|1@1+ (1,0) [0|0] "" Vector__XXX
 SG_ VCBATT1_a372_TLVBMS_BmbHwOverVol m6 : 15|1@1+ (1,0) [0|0] "" Vector__XXX
 SG_ VCBATT1_a432_TLVBMS_ChargeRegula m7 : 15|1@1+ (1,0) [0|0] "" Vector__XXX
 SG_ VCBATT1_a492_TLVBMS_SocImbalance m8 : 15|1@1+ (1,0) [0|0] "" Vector__XXX
 SG_ VCBATT1_a131_PCSCOMMON_MIA m2 : 14|1@1+ (1,0) [0|0] "" Vector__XXX
 SG_ VCBATT1_a191_exitDriveLowLVBusVo m3 : 14|1@1+ (1,0) [0|0] "" Vector__XXX
 SG_ VCBATT1_a371_failureToPrechargeR m6 : 14|1@1+ (1,0) [0|0] "" Vector__XXX
 SG_ VCBATT1_a431_TLVBMS_ChargeOverCu m7 : 14|1@1+ (1,0) [0|0] "" Vector__XXX
 SG_ VCBATT1_a491_vnf1248Configuratio m8 : 14|1@1+ (1,0) [0|0] "" Vector__XXX
 SG_ VCBATT1_a130_autopilot1EFuseTrip m2 : 13|1@1+ (1,0) [0|0] "" Vector__XXX
 SG_ VCBATT1_a370_noLVSupportSocTooLo m6 : 13|1@1+ (1,0) [0|0] "" Vector__XXX
 SG_ VCBATT1_a430_TLVBMS_ChargeCurren m7 : 13|1@1+ (1,0) [0|0] "" Vector__XXX
 SG_ VCBATT1_a490_vnf1248SelfTestFail m8 : 13|1@1+ (1,0) [0|0] "" Vector__XXX
 SG_ VCBATT1_a670_TLVBMS_EfuseStateIr m11 : 13|1@1+ (1,0) [0|0] "" Vector__XXX
 SG_ VCBATT1_a129_epas1EFuseTrip m2 : 12|1@1+ (1,0) [0|0] "" Vector__XXX
 SG_ VCBATT1_a189_IBSMIA m3 : 12|1@1+ (1,0) [0|0] "" Vector__XXX
 SG_ VCBATT1_a429_TLVBMS_CapacityTest m7 : 12|1@1+ (1,0) [0|0] "" Vector__XXX
 SG_ VCBATT1_a489_vnf1248SelfTestDebu m8 : 12|1@1+ (1,0) [0|0] "" Vector__XXX
 SG_ VCBATT1_a188_sleepFailed m3 : 11|1@1+ (1,0) [0|0] "" Vector__XXX
 SG_ VCBATT1_a428_TLVBMS_CacImbalance m7 : 11|1@1+ (1,0) [0|0] "" Vector__XXX
 SG_ VCBATT1_a548_HVFaultLoadShed m9 : 11|1@1+ (1,0) [0|0] "" Vector__XXX
 SG_ VCBATT1_a608_TLVBMS_BleedFetFail m10 : 11|1@1+ (1,0) [0|0] "" Vector__XXX
 SG_ VCBATT1_a127_vcleftEFuseTrip m2 : 10|1@1+ (1,0) [0|0] "" Vector__XXX
 SG_ VCBATT1_a427_TLVBMS_CacChange m7 : 10|1@1+ (1,0) [0|0] "" Vector__XXX
 SG_ VCBATT1_a006_CANTX_cyclicError m0 : 9|1@1+ (1,0) [0|0] "" Vector__XXX
 SG_ VCBATT1_a126_EPAS3P_MIA m2 : 9|1@1+ (1,0) [0|0] "" Vector__XXX
 SG_ VCBATT1_a426_TLVBMS_BusVoltageTo m7 : 9|1@1+ (1,0) [0|0] "" Vector__XXX
 SG_ VCBATT1_a486_undervoltageSelfTes m8 : 9|1@1+ (1,0) [0|0] "" Vector__XXX
 SG_ VCBATT1_a005_CANTXError m0 : 8|1@1+ (1,0) [0|0] "" Vector__XXX
 SG_ VCBATT1_a125_SCCM_MIA m2 : 8|1@1+ (1,0) [0|0] "" Vector__XXX
 SG_ VCBATT1_a245_sleepBypassFault m4 : 8|1@1+ (1,0) [0|0] "" Vector__XXX
 SG_ VCBATT1_a425_TLVBMS_BusVoltageTo m7 : 8|1@1+ (1,0) [0|0] "" Vector__XXX
 SG_ VCBATT1_a485_uvSelfTestLoadUnatt m8 : 8|1@1+ (1,0) [0|0] "" Vector__XXX
 SG_ VCBATT1_a545_LVBatteryTypeUnknow m9 : 8|1@1+ (1,0) [0|0] "" Vector__XXX
 SG_ VCBATT1_a064_busSleepReqTimeout m1 : 7|1@1+ (1,0) [0|0] "" Vector__XXX
 SG_ VCBATT1_a124_BB_MIA m2 : 7|1@1+ (1,0) [0|0] "" Vector__XXX
 SG_ VCBATT1_a244_brakeValveECUEFuseT m4 : 7|1@1+ (1,0) [0|0] "" Vector__XXX
 SG_ VCBATT1_a424_TLVBMS_BrickUnderVo m7 : 7|1@1+ (1,0) [0|0] "" Vector__XXX
 SG_ VCBATT1_a484_undervoltageSelfTes m8 : 7|1@1+ (1,0) [0|0] "" Vector__XXX
 SG_ VCBATT1_a544_LVBatteryCommsBusTu m9 : 7|1@1+ (1,0) [0|0] "" Vector__XXX
 SG_ VCBATT1_a003_SWAssertion m0 : 6|1@1+ (1,0) [0|0] "" Vector__XXX
 SG_ VCBATT1_a063_SwitchFault m1 : 6|1@1+ (1,0) [0|0] "" Vector__XXX
 SG_ VCBATT1_a183_replaceLVBattery2 m3 : 6|1@1+ (1,0) [0|0] "" Vector__XXX
 SG_ VCBATT1_a243_LVOverchargeInstc m4 : 6|1@1+ (1,0) [0|0] "" Vector__XXX
 SG_ VCBATT1_a363_TLVBMS_BleedBasedWe m6 : 6|1@1+ (1,0) [0|0] "" Vector__XXX
 SG_ VCBATT1_a423_TLVBMS_BrickUnderVo m7 : 6|1@1+ (1,0) [0|0] "" Vector__XXX
 SG_ VCBATT1_a002_PowerLossReset m0 : 5|1@1+ (1,0) [0|0] "" Vector__XXX
 SG_ VCBATT1_a062_XCPWasConnected m1 : 5|1@1+ (1,0) [0|0] "" Vector__XXX
 SG_ VCBATT1_a122_ICR_MIA m2 : 5|1@1+ (1,0) [0|0] "" Vector__XXX
 SG_ VCBATT1_a182_replaceLVBattery m3 : 5|1@1+ (1,0) [0|0] "" Vector__XXX
 SG_ VCBATT1_a362_TLVBMS_AllSocCorrec m6 : 5|1@1+ (1,0) [0|0] "" Vector__XXX
 SG_ VCBATT1_a422_rtosSleepFailed m7 : 5|1@1+ (1,0) [0|0] "" Vector__XXX
 SG_ VCBATT1_a482_lvBridgeEFuseTrip m8 : 5|1@1+ (1,0) [0|0] "" Vector__XXX
 SG_ VCBATT1_a001_WatchdogReset m0 : 4|1@1+ (1,0) [0|0] "" Vector__XXX
 SG_ VCBATT1_a061_XCPConnected m1 : 4|1@1+ (1,0) [0|0] "" Vector__XXX
 SG_ VCBATT1_a481_LVBridgeCloseDBG m8 : 4|1@1+ (1,0) [0|0] "" Vector__XXX
 SG_ VCBATT1_a541_LVBatteryChargeOCLe m9 : 4|1@1+ (1,0) [0|0] "" Vector__XXX
 SG_ VCBATT1_a601_LVBatteryHeaterNotP m10 : 4|1@1+ (1,0) [0|0] "" Vector__XXX
 SG_ VCBATT1_matrixIndex M : 0|4@1+ (1,0) [0|0] "" Vector__XXX

BO_ 975 VCBATT2_alertMatrix: 8 Vector__XXX
 SG_ VCBATT2_a060_engineeringBuild m0 : 63|1@1+ (1,0) [0|0] "" Vector__XXX
 SG_ VCBATT2_a120_DI_DRIVE_MIA m1 : 63|1@1+ (1,0) [0|0] "" Vector__XXX
 SG_ VCBATT2_a300_louverActuatorSwapD m4 : 63|1@1+ (1,0) [0|0] "" Vector__XXX
 SG_ VCBATT2_a059_inputResistanceHigh m0 : 62|1@1+ (1,0) [0|0] "" Vector__XXX
 SG_ VCBATT2_a119_SCCM_MIA m1 : 62|1@1+ (1,0) [0|0] "" Vector__XXX
 SG_ VCBATT2_a299_homelinkConfigurati m4 : 62|1@1+ (1,0) [0|0] "" Vector__XXX
 SG_ VCBATT2_a058_inputRHighSyncDebug m0 : 61|1@1+ (1,0) [0|0] "" Vector__XXX
 SG_ VCBATT2_a118_VCFRONT_MIA m1 : 61|1@1+ (1,0) [0|0] "" Vector__XXX
 SG_ VCBATT2_a117_VCLEFT_MIA m1 : 60|1@1+ (1,0) [0|0] "" Vector__XXX
 SG_ VCBATT2_a116_VCRIGHT_MIA m1 : 59|1@1+ (1,0) [0|0] "" Vector__XXX
 SG_ VCBATT2_a115_VCSEC_MIA m1 : 58|1@1+ (1,0) [0|0] "" Vector__XXX
 SG_ VCBATT2_a295_rightSideRepeaterLi m4 : 58|1@1+ (1,0) [0|0] "" Vector__XXX
 SG_ VCBATT2_a475_rightHeadlampIntern m7 : 58|1@1+ (1,0) [0|0] "" Vector__XXX
 SG_ VCBATT2_a114_ESP_MIA m1 : 57|1@1+ (1,0) [0|0] "" Vector__XXX
 SG_ VCBATT2_a354_windshieldCameraHea m5 : 57|1@1+ (1,0) [0|0] "" Vector__XXX
 SG_ VCBATT2_a113_UI_MIA m1 : 56|1@1+ (1,0) [0|0] "" Vector__XXX
 SG_ VCBATT2_a353_wiperHeaterUndercur m5 : 56|1@1+ (1,0) [0|0] "" Vector__XXX
 SG_ VCBATT2_a112_EPBL_MIA m1 : 55|1@1+ (1,0) [0|0] "" Vector__XXX
 SG_ VCBATT2_a292_sideMarkerLightPipe m4 : 55|1@1+ (1,0) [0|0] "" Vector__XXX
 SG_ VCBATT2_a111_EPBR_MIA m1 : 54|1@1+ (1,0) [0|0] "" Vector__XXX
 SG_ VCBATT2_a291_rightFogLightFault m4 : 54|1@1+ (1,0) [0|0] "" Vector__XXX
 SG_ VCBATT2_a471_emergencyFrunkButto m7 : 54|1@1+ (1,0) [0|0] "" Vector__XXX
 SG_ VCBATT2_a110_GTW_MIA m1 : 53|1@1+ (1,0) [0|0] "" Vector__XXX
 SG_ VCBATT2_a290_leftFogLightFault m4 : 53|1@1+ (1,0) [0|0] "" Vector__XXX
 SG_ VCBATT2_a649_persistAccPortPower m10 : 52|1@1+ (1,0) [0|0] "" Vector__XXX
 SG_ VCBATT2_a108_DIF_MIA m1 : 51|1@1+ (1,0) [0|0] "" Vector__XXX
 SG_ VCBATT2_a107_BMS_MIA m1 : 50|1@1+ (1,0) [0|0] "" Vector__XXX
 SG_ VCBATT2_a227_radFanCompromised m3 : 50|1@1+ (1,0) [0|0] "" Vector__XXX
 SG_ VCBATT2_a046_Task1000msError m0 : 49|1@1+ (1,0) [0|0] "" Vector__XXX
 SG_ VCBATT2_a106_PCS_MIA m1 : 49|1@1+ (1,0) [0|0] "" Vector__XXX
 SG_ VCBATT2_a166_rightHCMMIA m2 : 49|1@1+ (1,0) [0|0] "" Vector__XXX
 SG_ VCBATT2_a586_rightLowOrHighBeamL m9 : 49|1@1+ (1,0) [0|0] "" Vector__XXX
 SG_ VCBATT2_a646_washPumpHealthCalcu m10 : 49|1@1+ (1,0) [0|0] "" Vector__XXX
 SG_ VCBATT2_a045_Task100msError m0 : 48|1@1+ (1,0) [0|0] "" Vector__XXX
 SG_ VCBATT2_a105_TAS_MIA m1 : 48|1@1+ (1,0) [0|0] "" Vector__XXX
 SG_ VCBATT2_a645_washPumpHealthCalcu m10 : 48|1@1+ (1,0) [0|0] "" Vector__XXX
 SG_ VCBATT2_a044_Task10msError m0 : 47|1@1+ (1,0) [0|0] "" Vector__XXX
 SG_ VCBATT2_a104_DAS_MIA m1 : 47|1@1+ (1,0) [0|0] "" Vector__XXX
 SG_ VCBATT2_a524_rightHeadlampAiming m8 : 47|1@1+ (1,0) [0|0] "" Vector__XXX
 SG_ VCBATT2_a584_frunkSwitchGroupDeb m9 : 47|1@1+ (1,0) [0|0] "" Vector__XXX
 SG_ VCBATT2_a644_washPumpHealthCalcu m10 : 47|1@1+ (1,0) [0|0] "" Vector__XXX
 SG_ VCBATT2_a043_Task1msError m0 : 46|1@1+ (1,0) [0|0] "" Vector__XXX
 SG_ VCBATT2_a103_CP_MIA m1 : 46|1@1+ (1,0) [0|0] "" Vector__XXX
 SG_ VCBATT2_a463_frunkSensorService m7 : 46|1@1+ (1,0) [0|0] "" Vector__XXX
 SG_ VCBATT2_a583_frunkSwitchGroupDis m9 : 46|1@1+ (1,0) [0|0] "" Vector__XXX
 SG_ VCBATT2_a643_rightHeadlampUartCo m10 : 46|1@1+ (1,0) [0|0] "" Vector__XXX
 SG_ VCBATT2_a042_HighStackUsage m0 : 45|1@1+ (1,0) [0|0] "" Vector__XXX
 SG_ VCBATT2_a522_hibernationActiveLo m8 : 45|1@1+ (1,0) [0|0] "" Vector__XXX
 SG_ VCBATT2_a041_HighCPULoad m0 : 44|1@1+ (1,0) [0|0] "" Vector__XXX
 SG_ VCBATT2_a040_Backtrace m0 : 43|1@1+ (1,0) [0|0] "" Vector__XXX
 SG_ VCBATT2_a100_CANbus_MIA m1 : 43|1@1+ (1,0) [0|0] "" Vector__XXX
 SG_ VCBATT2_a039_ProtFaultAddress m0 : 42|1@1+ (1,0) [0|0] "" Vector__XXX
 SG_ VCBATT2_a399_frunkNeverReportedO m6 : 42|1@1+ (1,0) [0|0] "" Vector__XXX
 SG_ VCBATT2_a038_ProtFaultInfo m0 : 41|1@1+ (1,0) [0|0] "" Vector__XXX
 SG_ VCBATT2_a098_DIR_MIA m1 : 41|1@1+ (1,0) [0|0] "" Vector__XXX
 SG_ VCBATT2_a158_louverDisconnected m2 : 41|1@1+ (1,0) [0|0] "" Vector__XXX
 SG_ VCBATT2_a578_vbattFusedLowCurren m9 : 41|1@1+ (1,0) [0|0] "" Vector__XXX
 SG_ VCBATT2_a698_rightHeadlampNotAim m11 : 41|1@1+ (1,0) [0|0] "" Vector__XXX
 SG_ VCBATT2_a037_MemManageFault m0 : 40|1@1+ (1,0) [0|0] "" Vector__XXX
 SG_ VCBATT2_a157_louverBreakage m2 : 40|1@1+ (1,0) [0|0] "" Vector__XXX
 SG_ VCBATT2_a517_hibernationRecovery m8 : 40|1@1+ (1,0) [0|0] "" Vector__XXX
 SG_ VCBATT2_a036_UnknownIrq m0 : 39|1@1+ (1,0) [0|0] "" Vector__XXX
 SG_ VCBATT2_a096_OCS1P_MIA m1 : 39|1@1+ (1,0) [0|0] "" Vector__XXX
 SG_ VCBATT2_a156_louverBlockage m2 : 39|1@1+ (1,0) [0|0] "" Vector__XXX
 SG_ VCBATT2_a516_hibernationActive m8 : 39|1@1+ (1,0) [0|0] "" Vector__XXX
 SG_ VCBATT2_a575_frontOilPumpEFuseTr m9 : 38|1@1+ (1,0) [0|0] "" Vector__XXX
 SG_ VCBATT2_a634_indeterminateSwitch m10 : 37|1@1+ (1,0) [0|0] "" Vector__XXX
 SG_ VCBATT2_a031_UDSActive m0 : 34|1@1+ (1,0) [0|0] "" Vector__XXX
 SG_ VCBATT2_a091_CMPD_MIA m1 : 34|1@1+ (1,0) [0|0] "" Vector__XXX
 SG_ VCBATT2_a211_I2CFault m3 : 34|1@1+ (1,0) [0|0] "" Vector__XXX
 SG_ VCBATT2_a391_frunkLatchSwitchFau m6 : 34|1@1+ (1,0) [0|0] "" Vector__XXX
 SG_ VCBATT2_a631_rightHeadlampFactor m10 : 34|1@1+ (1,0) [0|0] "" Vector__XXX
 SG_ VCBATT2_a030_ECULogUploadRequest m0 : 33|1@1+ (1,0) [0|0] "" Vector__XXX
 SG_ VCBATT2_a090_APS_MIA m1 : 33|1@1+ (1,0) [0|0] "" Vector__XXX
 SG_ VCBATT2_a029_CoreDump m0 : 32|1@1+ (1,0) [0|0] "" Vector__XXX
 SG_ VCBATT2_a209_brakeFluidSNA m3 : 32|1@1+ (1,0) [0|0] "" Vector__XXX
 SG_ VCBATT2_a389_frunkInhibitingRele m6 : 32|1@1+ (1,0) [0|0] "" Vector__XXX
 SG_ VCBATT2_a569_rightDaytimeRunning m9 : 32|1@1+ (1,0) [0|0] "" Vector__XXX
 SG_ VCBATT2_a028_UsageFault m0 : 31|1@1+ (1,0) [0|0] "" Vector__XXX
 SG_ VCBATT2_a208_brakeFluidLow m3 : 31|1@1+ (1,0) [0|0] "" Vector__XXX
 SG_ VCBATT2_a567_rightFrontTurnLight m9 : 30|1@1+ (1,0) [0|0] "" Vector__XXX
 SG_ VCBATT2_a086_VCBATT_MIA m1 : 29|1@1+ (1,0) [0|0] "" Vector__XXX
 SG_ VCBATT2_a144_EPAS3S_MIA m2 : 27|1@1+ (1,0) [0|0] "" Vector__XXX
 SG_ VCBATT2_a143_powerLossDuringSlee m2 : 26|1@1+ (1,0) [0|0] "" Vector__XXX
 SG_ VCBATT2_a022_TaskInitError m0 : 25|1@1+ (1,0) [0|0] "" Vector__XXX
 SG_ VCBATT2_a082_VCFRONT2_MIA m1 : 25|1@1+ (1,0) [0|0] "" Vector__XXX
 SG_ VCBATT2_a021_TaskSchedulerError m0 : 24|1@1+ (1,0) [0|0] "" Vector__XXX
 SG_ VCBATT2_a081_VCFRONT1_MIA m1 : 24|1@1+ (1,0) [0|0] "" Vector__XXX
 SG_ VCBATT2_a080_VCFRONT0_MIA m1 : 23|1@1+ (1,0) [0|0] "" Vector__XXX
 SG_ VCBATT2_a019_BusFault m0 : 22|1@1+ (1,0) [0|0] "" Vector__XXX
 SG_ VCBATT2_a079_VCBATT2_MIA m1 : 22|1@1+ (1,0) [0|0] "" Vector__XXX
 SG_ VCBATT2_a619_frunkSwitchReleaseT m10 : 22|1@1+ (1,0) [0|0] "" Vector__XXX
 SG_ VCBATT2_a018_HardFault m0 : 21|1@1+ (1,0) [0|0] "" Vector__XXX
 SG_ VCBATT2_a078_VCBATT1_MIA m1 : 21|1@1+ (1,0) [0|0] "" Vector__XXX
 SG_ VCBATT2_a558_rightHeadlampAiming m9 : 21|1@1+ (1,0) [0|0] "" Vector__XXX
 SG_ VCBATT2_a017_NVMMStatusDbg m0 : 20|1@1+ (1,0) [0|0] "" Vector__XXX
 SG_ VCBATT2_a077_VCBATT0_MIA m1 : 20|1@1+ (1,0) [0|0] "" Vector__XXX
 SG_ VCBATT2_a617_APP_MIA m10 : 20|1@1+ (1,0) [0|0] "" Vector__XXX
 SG_ VCBATT2_a016_NVMMRecordError m0 : 19|1@1+ (1,0) [0|0] "" Vector__XXX
 SG_ VCBATT2_a015_NVMMError m0 : 18|1@1+ (1,0) [0|0] "" Vector__XXX
 SG_ VCBATT2_a013_AlertManagerFault m0 : 16|1@1+ (1,0) [0|0] "" Vector__XXX
 SG_ VCBATT2_a133_BRAKE_MIA m2 : 16|1@1+ (1,0) [0|0] "" Vector__XXX
 SG_ VCBATT2_a012_CPUReset m0 : 15|1@1+ (1,0) [0|0] "" Vector__XXX
 SG_ VCBATT2_a192_vehicleLoadShed m3 : 15|1@1+ (1,0) [0|0] "" Vector__XXX
 SG_ VCBATT2_a131_PCSCOMMON_MIA m2 : 14|1@1+ (1,0) [0|0] "" Vector__XXX
 SG_ VCBATT2_a610_frunkOpenFailureMet m10 : 13|1@1+ (1,0) [0|0] "" Vector__XXX
 SG_ VCBATT2_a309_frunkEmergencyRelea m5 : 12|1@1+ (1,0) [0|0] "" Vector__XXX
 SG_ VCBATT2_a188_sleepFailed m3 : 11|1@1+ (1,0) [0|0] "" Vector__XXX
 SG_ VCBATT2_a548_HVFaultLoadShed m9 : 11|1@1+ (1,0) [0|0] "" Vector__XXX
 SG_ VCBATT2_a668_rightHeadlampRegion m11 : 11|1@1+ (1,0) [0|0] "" Vector__XXX
 SG_ VCBATT2_a187_washerFluidLowPasse m3 : 10|1@1+ (1,0) [0|0] "" Vector__XXX
 SG_ VCBATT2_a547_postCrashLoadShed m9 : 10|1@1+ (1,0) [0|0] "" Vector__XXX
 SG_ VCBATT2_a006_CANTX_cyclicError m0 : 9|1@1+ (1,0) [0|0] "" Vector__XXX
 SG_ VCBATT2_a126_EPAS3P_MIA m2 : 9|1@1+ (1,0) [0|0] "" Vector__XXX
 SG_ VCBATT2_a186_washerFluidLowFasci m3 : 9|1@1+ (1,0) [0|0] "" Vector__XXX
 SG_ VCBATT2_a306_frunkPriUnderCurren m5 : 9|1@1+ (1,0) [0|0] "" Vector__XXX
 SG_ VCBATT2_a486_sleepPowerDebug m8 : 9|1@1+ (1,0) [0|0] "" Vector__XXX
 SG_ VCBATT2_a666_rightHeadlampRetryI m11 : 9|1@1+ (1,0) [0|0] "" Vector__XXX
 SG_ VCBATT2_a005_CANTXError m0 : 8|1@1+ (1,0) [0|0] "" Vector__XXX
 SG_ VCBATT2_a125_SCCM_MIA m2 : 8|1@1+ (1,0) [0|0] "" Vector__XXX
 SG_ VCBATT2_a185_washerFluidLow m3 : 8|1@1+ (1,0) [0|0] "" Vector__XXX
 SG_ VCBATT2_a305_frunkPriOverCurrent m5 : 8|1@1+ (1,0) [0|0] "" Vector__XXX
 SG_ VCBATT2_a485_mcuGamingEFuseFault m8 : 8|1@1+ (1,0) [0|0] "" Vector__XXX
 SG_ VCBATT2_a064_busSleepReqTimeout m1 : 7|1@1+ (1,0) [0|0] "" Vector__XXX
 SG_ VCBATT2_a124_BB_MIA m2 : 7|1@1+ (1,0) [0|0] "" Vector__XXX
 SG_ VCBATT2_a304_frunkReleaseFailed m5 : 7|1@1+ (1,0) [0|0] "" Vector__XXX
 SG_ VCBATT2_a364_heaterTypeEstimatio m6 : 7|1@1+ (1,0) [0|0] "" Vector__XXX
 SG_ VCBATT2_a664_rightHeadlampUartWa m11 : 7|1@1+ (1,0) [0|0] "" Vector__XXX
 SG_ VCBATT2_a003_SWAssertion m0 : 6|1@1+ (1,0) [0|0] "" Vector__XXX
 SG_ VCBATT2_a063_SwitchFault m1 : 6|1@1+ (1,0) [0|0] "" Vector__XXX
 SG_ VCBATT2_a123_VC_SECONDARY_LIGHTI m2 : 6|1@1+ (1,0) [0|0] "" Vector__XXX
 SG_ VCBATT2_a303_frunkAccessPostActi m5 : 6|1@1+ (1,0) [0|0] "" Vector__XXX
 SG_ VCBATT2_a423_rtosSleepFailed m7 : 6|1@1+ (1,0) [0|0] "" Vector__XXX
 SG_ VCBATT2_a002_PowerLossReset m0 : 5|1@1+ (1,0) [0|0] "" Vector__XXX
 SG_ VCBATT2_a062_XCPWasConnected m1 : 5|1@1+ (1,0) [0|0] "" Vector__XXX
 SG_ VCBATT2_a122_ICR_MIA m2 : 5|1@1+ (1,0) [0|0] "" Vector__XXX
 SG_ VCBATT2_a662_mculessRightHeadlam m11 : 5|1@1+ (1,0) [0|0] "" Vector__XXX
 SG_ VCBATT2_a001_WatchdogReset m0 : 4|1@1+ (1,0) [0|0] "" Vector__XXX
 SG_ VCBATT2_a061_XCPConnected m1 : 4|1@1+ (1,0) [0|0] "" Vector__XXX
 SG_ VCBATT2_a181_homelinkMIA m3 : 4|1@1+ (1,0) [0|0] "" Vector__XXX
 SG_ VCBATT2_a241_radFanMIA m4 : 4|1@1+ (1,0) [0|0] "" Vector__XXX
 SG_ VCBATT2_a361_washerFluidLowMomen m6 : 4|1@1+ (1,0) [0|0] "" Vector__XXX
 SG_ VCBATT2_matrixIndex M : 0|4@1+ (1,0) [0|0] "" Vector__XXX

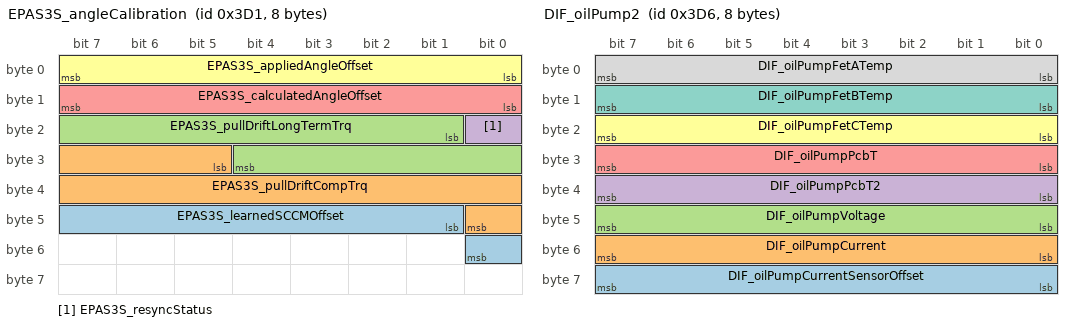
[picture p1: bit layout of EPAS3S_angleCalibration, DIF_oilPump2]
BO_ 977 EPAS3S_angleCalibration: 8 Vector__XXX
 SG_ EPAS3S_learnedSCCMOffset : 41|8@1+ (0.1,-12.8) [0|0] "" Vector__XXX
 SG_ EPAS3S_pullDriftCompTrq : 29|12@1+ (0.01,-10) [0|0] "" Vector__XXX
 SG_ EPAS3S_pullDriftLongTermTrq : 17|12@1+ (0.01,-10) [0|0] "" Vector__XXX
 SG_ EPAS3S_resyncStatus : 16|1@1+ (1,0) [0|0] "" Vector__XXX
 SG_ EPAS3S_calculatedAngleOffset : 8|8@1+ (0.1,-12.8) [0|0] "" Vector__XXX
 SG_ EPAS3S_appliedAngleOffset : 0|8@1+ (0.1,-12.8) [0|0] "" Vector__XXX

BO_ 982 DIF_oilPump2: 8 Vector__XXX
 SG_ DIF_oilPumpCurrentSensorOffset : 56|8@1+ (0.005,0) [0|0] "" Vector__XXX
 SG_ DIF_oilPumpCurrent : 48|8@1+ (0.1,0) [0|0] "" Vector__XXX
 SG_ DIF_oilPumpVoltage : 40|8@1+ (0.3,0) [0|0] "" Vector__XXX
 SG_ DIF_oilPumpPcbT2 : 32|8@1+ (1,-40) [0|0] "" Vector__XXX
 SG_ DIF_oilPumpPcbT : 24|8@1+ (1,-40) [0|0] "" Vector__XXX
 SG_ DIF_oilPumpFetCTemp : 16|8@1+ (1,-40) [0|0] "" Vector__XXX
 SG_ DIF_oilPumpFetBTemp : 8|8@1+ (1,-40) [0|0] "" Vector__XXX
 SG_ DIF_oilPumpFetATemp : 0|8@1+ (1,-40) [0|0] "" Vector__XXX

BO_ 987 VCSEC_endpointTemp: 8 Vector__XXX
 SG_ VCSEC_rightCenterRSSI m2 : 56|8@1- (1,0) [0|0] "" Vector__XXX
 SG_ VCSEC_rightFrontEndpointTemp m9 : 56|8@1- (1,0) [0|0] "" Vector__XXX
 SG_ VCSEC_silentWakeCountCenter m8 : 50|14@1+ (1,0) [0|0] "" Vector__XXX
 SG_ VCSEC_silentWakeCountRightRear m5 : 50|14@1+ (1,0) [0|0] "" Vector__XXX
 SG_ VCSEC_leftFrontEndpointTemp m9 : 48|8@1- (1,0) [0|0] "" Vector__XXX
 SG_ VCSEC_leftRearRSSI m2 : 48|8@1- (1,0) [0|0] "" Vector__XXX
 SG_ VCSEC_silentPresentTime m6 : 45|18@1+ (1,0) [0|0] "" Vector__XXX
 SG_ VCSEC_infotainmentPairingStatus m11 : 40|2@1+ (1,0) [0|0] "" Vector__XXX
 SG_ VCSEC_leftRightRSSI m2 : 40|8@1- (1,0) [0|0] "" Vector__XXX
 SG_ VCSEC_rearRightRSSI m1 : 40|8@1- (1,0) [0|0] "" Vector__XXX
 SG_ VCSEC_rightRearEndpointTemp m9 : 40|8@1- (1,0) [0|0] "" Vector__XXX
 SG_ VCSEC_sleepFlagECULogUpload m7 : 37|2@1+ (1,0) [0|0] "" Vector__XXX
 SG_ VCSEC_silentWakeCountLeftRear m5 : 36|14@1+ (1,0) [0|0] "" Vector__XXX
 SG_ VCSEC_silentWakeCountRear m8 : 36|14@1+ (1,0) [0|0] "" Vector__XXX
 SG_ VCSEC_wokeFromSleep m7 : 36|1@1+ (1,0) [0|0] "" Vector__XXX
 SG_ VCSEC_readyToSleepBitfield m3 : 34|30@1+ (1,0) [0|0] "" Vector__XXX
 SG_ VCSEC_sleepFlagUWBUpdater m7 : 34|2@1+ (1,0) [0|0] "" Vector__XXX
 SG_ VCSEC_leftCenterRSSI m2 : 32|8@1- (1,0) [0|0] "" Vector__XXX
 SG_ VCSEC_leftRearEndpointTemp m9 : 32|8@1- (1,0) [0|0] "" Vector__XXX
 SG_ VCSEC_rearEndpointTemp m10 : 32|8@1- (1,0) [0|0] "" Vector__XXX
 SG_ VCSEC_rearLeftRSSI m1 : 32|8@1- (1,0) [0|0] "" Vector__XXX
 SG_ VCSEC_sleepFlagTireId m7 : 32|2@1+ (1,0) [0|0] "" Vector__XXX
 SG_ VCSEC_sleepFlagNVMWriteFailed m7 : 30|2@1+ (1,0) [0|0] "" Vector__XXX
 SG_ VCSEC_sleepFlagNFCCardPresent m7 : 28|2@1+ (1,0) [0|0] "" Vector__XXX
 SG_ VCSEC_sleepFlgBLEEndpointSleepCo m7 : 26|2@1+ (1,0) [0|0] "" Vector__XXX
 SG_ VCSEC_NFCCradleEndpointTemp m9 : 24|8@1- (1,0) [0|0] "" Vector__XXX
 SG_ VCSEC_centerRearRSSI m2 : 24|8@1- (1,0) [0|0] "" Vector__XXX
 SG_ VCSEC_heapCurrentSize m11 : 24|16@1+ (1,0) [0|0] "" Vector__XXX
 SG_ VCSEC_rearCenterRSSI m1 : 24|8@1- (1,0) [0|0] "" Vector__XXX
 SG_ VCSEC_rightEndpointTemp m10 : 24|8@1- (1,0) [0|0] "" Vector__XXX
 SG_ VCSEC_silentAwakeTimeSeconds m6 : 24|21@1+ (1,0) [0|0] "" Vector__XXX
 SG_ VCSEC_sleepFlagGap m7 : 24|2@1+ (1,0) [0|0] "" Vector__XXX
 SG_ VCSEC_timeFromWakeToLoggingAvail m4 : 24|16@1+ (1,0) [0|0] "" Vector__XXX
 SG_ VCSEC_NFCCradleBLEDrift m0 : 22|2@1+ (1,0) [0|0] "" Vector__XXX
 SG_ VCSEC_silentWakeCountRight m8 : 22|14@1+ (1,0) [0|0] "" Vector__XXX
 SG_ VCSEC_silentWakeCountSecondary m5 : 22|14@1+ (1,0) [0|0] "" Vector__XXX
 SG_ VCSEC_sleepFlagKeyfobConnector m7 : 22|2@1+ (1,0) [0|0] "" Vector__XXX
 SG_ VCSEC_secondaryBLEDrift m0 : 20|2@1+ (1,0) [0|0] "" Vector__XXX
 SG_ VCSEC_sleepFlagAlarm m7 : 20|2@1+ (1,0) [0|0] "" Vector__XXX
 SG_ VCSEC_frontRightBLEDrift m0 : 18|2@1+ (1,0) [0|0] "" Vector__XXX
 SG_ VCSEC_sleepFlagConnectionMonitor m7 : 18|2@1+ (1,0) [0|0] "" Vector__XXX
 SG_ VCSEC_centerRightRSSI m2 : 16|8@1- (1,0) [0|0] "" Vector__XXX
 SG_ VCSEC_frontLeftBLEDrift m0 : 16|2@1+ (1,0) [0|0] "" Vector__XXX
 SG_ VCSEC_leftEndpointTemp m10 : 16|8@1- (1,0) [0|0] "" Vector__XXX
 SG_ VCSEC_rightRearRSSI m1 : 16|8@1- (1,0) [0|0] "" Vector__XXX
 SG_ VCSEC_secondaryEndpointTemp m9 : 16|8@1- (1,0) [0|0] "" Vector__XXX
 SG_ VCSEC_sleepFlagBLEConnections m7 : 16|2@1+ (1,0) [0|0] "" Vector__XXX
 SG_ VCSEC_rearRightBLEDrift m0 : 14|2@1+ (1,0) [0|0] "" Vector__XXX
 SG_ VCSEC_sleepFlagAdvScanner m7 : 14|2@1+ (1,0) [0|0] "" Vector__XXX
 SG_ VCSEC_rearLeftBLEDrift m0 : 12|2@1+ (1,0) [0|0] "" Vector__XXX
 SG_ VCSEC_sleepFlagOvertTemperatureM m7 : 12|2@1+ (1,0) [0|0] "" Vector__XXX
 SG_ VCSEC_frontBLEDrift m0 : 10|2@1+ (1,0) [0|0] "" Vector__XXX
 SG_ VCSEC_sleepFlagBLEEndpointReset m7 : 10|2@1+ (1,0) [0|0] "" Vector__XXX
 SG_ VCSEC_centerEndpointTemp m10 : 8|8@1- (1,0) [0|0] "" Vector__XXX
 SG_ VCSEC_centerLeftRSSI m2 : 8|8@1- (1,0) [0|0] "" Vector__XXX
 SG_ VCSEC_frontEndpointTemp m9 : 8|8@1- (1,0) [0|0] "" Vector__XXX
 SG_ VCSEC_heapWatermark m11 : 8|16@1+ (1,0) [0|0] "" Vector__XXX
 SG_ VCSEC_rearBLEDrift m0 : 8|2@1+ (1,0) [0|0] "" Vector__XXX
 SG_ VCSEC_rightLeftRSSI m1 : 8|8@1- (1,0) [0|0] "" Vector__XXX
 SG_ VCSEC_silentWakeCountFront m5 : 8|14@1+ (1,0) [0|0] "" Vector__XXX
 SG_ VCSEC_silentWakeCountLeft m8 : 8|14@1+ (1,0) [0|0] "" Vector__XXX
 SG_ VCSEC_silentWakeCountNFCCradle m4 : 8|14@1+ (1,0) [0|0] "" Vector__XXX
 SG_ VCSEC_sleepCountDelta m6 : 8|16@1+ (1,0) [0|0] "" Vector__XXX
 SG_ VCSEC_sleepFlagNFC m7 : 8|2@1+ (1,0) [0|0] "" Vector__XXX
 SG_ VCSEC_rightBLEDrift m0 : 6|2@1+ (1,0) [0|0] "" Vector__XXX
 SG_ VCSEC_sleepFlagGATTServer m7 : 6|2@1+ (1,0) [0|0] "" Vector__XXX
 SG_ VCSEC_leftBLEDrift m0 : 4|2@1+ (1,0) [0|0] "" Vector__XXX
 SG_ VCSEC_requestSleepBitfield m3 : 4|30@1+ (1,0) [0|0] "" Vector__XXX
 SG_ VCSEC_sleepFlagNFCFieldControl m7 : 4|2@1+ (1,0) [0|0] "" Vector__XXX
 SG_ VCSEC_endpointDataIndex M : 0|4@1+ (1,0) [0|0] "" Vector__XXX

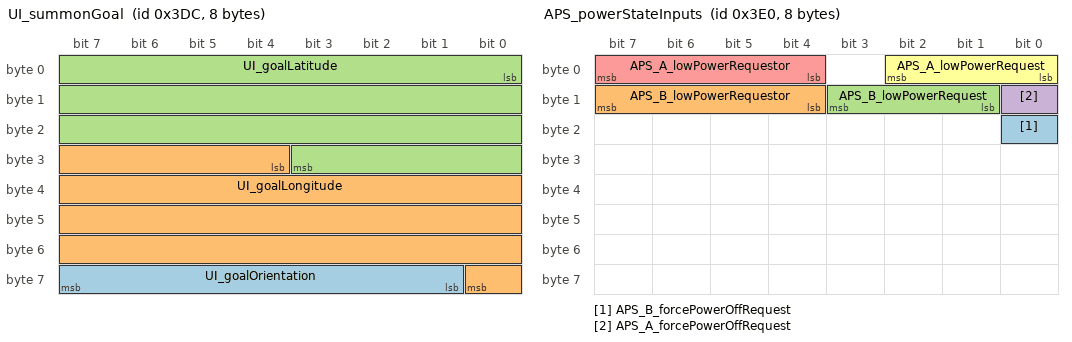
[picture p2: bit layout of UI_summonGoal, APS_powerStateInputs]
BO_ 988 UI_summonGoal: 8 Vector__XXX
 SG_ UI_goalOrientation : 57|7@1+ (2.8125,0) [0|0] "" Vector__XXX
 SG_ UI_goalLongitude : 28|29@1- (1e-06,0) [0|0] "" Vector__XXX
 SG_ UI_goalLatitude : 0|28@1- (1e-06,0) [0|0] "" Vector__XXX

BO_ 989 CP_loggingSlow: 8 Vector__XXX
 SG_ CP_doorPushLockoutActive m4 : 63|1@1+ (1,0) [0|0] "" Vector__XXX
 SG_ CP_faultLineSetByCP m2 : 62|1@1+ (1,0) [0|0] "" Vector__XXX
 SG_ CP_pilotWakeCounter m6 : 61|3@1+ (1,0) [0|0] "" Vector__XXX
 SG_ CP_proximityWakeCounter m5 : 61|3@1+ (1,0) [0|0] "" Vector__XXX
 SG_ CP_wakeOnPushCounter m4 : 60|3@1+ (1,0) [0|0] "" Vector__XXX
 SG_ CP_backCover2State m1 : 59|3@1+ (1,0) [0|0] "" Vector__XXX
 SG_ CP_inletHeaterDuty m3 : 57|7@1+ (1,0) [0|0] "" Vector__XXX
 SG_ CP_backCoverState m1 : 56|3@1+ (1,0) [0|0] "" Vector__XXX
 SG_ CP_doorCloseLimiterMaxRequestType m5 : 56|5@1+ (1,0) [0|0] "" Vector__XXX
 SG_ CP_uhfDoorRequestCounts m7 : 56|5@1+ (1,0) [0|0] "" Vector__XXX
 SG_ CP_inletHeaterState m3 : 55|2@1+ (1,0) [0|0] "" Vector__XXX
 SG_ CP_acNumRetries m6 : 53|8@1+ (1,0) [0|0] "" Vector__XXX
 SG_ CP_doorCloseLimiterMaxCount m5 : 52|4@1+ (1,0) [0|0] "" Vector__XXX
 SG_ CP_faultLineV m2 : 52|10@1+ (0.004550576735092864,0) [0|0] "" Vector__XXX
 SG_ CP_inlet2HarnessIdValue m3 : 52|3@1+ (1,0) [0|0] "" Vector__XXX
 SG_ CP_inlet2HarnessIdState m3 : 50|2@1+ (1,0) [0|0] "" Vector__XXX
 SG_ CP_inlet2HarnessV m0 : 50|14@1+ (0.001,0) [0|0] "" Vector__XXX
 SG_ CP_doorOpenLimiterMaxRequestType m5 : 48|4@1+ (1,0) [0|0] "" Vector__XXX
 SG_ CP_sensorExtV m1 : 48|8@1+ (0.01968504,0) [0|0] "" Vector__XXX
 SG_ CP_inlet1HarnessIdValue m3 : 47|3@1+ (1,0) [0|0] "" Vector__XXX
 SG_ CP_inlet1HarnessIdState m3 : 45|2@1+ (1,0) [0|0] "" Vector__XXX
 SG_ CP_doorOpenLimiterMaxCount m5 : 44|4@1+ (1,0) [0|0] "" Vector__XXX
 SG_ CP_nvm_pilotDiodeFaultCount m5 : 41|3@1+ (1,0) [0|0] "" Vector__XXX
 SG_ CP_nvm_badPilotDiodeDetected m5 : 40|1@1+ (1,0) [0|0] "" Vector__XXX
 SG_ CP_pilotHighValue_intervalMin10s m2 : 40|12@1- (0.01,0) [0|0] "" Vector__XXX
 SG_ CP_plcV m1 : 40|8@1+ (0.01294118,0) [0|0] "" Vector__XXX
 SG_ CP_nvm_doorPresentValid m5 : 39|1@1+ (1,0) [0|0] "" Vector__XXX
 SG_ CP_acNextRetryTimeoutS m6 : 38|15@1+ (1,0) [0|0] "" Vector__XXX
 SG_ CP_nvm_doorPresent m5 : 38|1@1+ (1,0) [0|0] "" Vector__XXX
 SG_ CP_nvm_doorOpen m5 : 37|1@1+ (1,0) [0|0] "" Vector__XXX
 SG_ CP_doorId_intervalMax10s m4 : 36|8@1+ (0.0196078431372549,0) [0|0] "" Vector__XXX
 SG_ CP_inlet1HarnessV m0 : 36|14@1+ (0.001,0) [0|0] "" Vector__XXX
 SG_ CP_latchI m3 : 33|12@1+ (0.0025,0) [0|0] "" Vector__XXX
 SG_ CP_ivledV m1 : 32|8@1+ (0.01968504,0) [0|0] "" Vector__XXX
 SG_ CP_doorId_intervalMin10s m4 : 28|8@1+ (0.0196078431372549,0) [0|0] "" Vector__XXX
 SG_ CP_inductiveSensorBaseline m7 : 28|28@1+ (0.08083879947662354,0) [0|0] "" Vector__XXX
 SG_ CP_ivledState m1 : 28|2@1+ (1,0) [0|0] "" Vector__XXX
 SG_ CP_pilotHighValue_intervalMax10s m2 : 28|12@1- (0.01,0) [0|0] "" Vector__XXX
 SG_ CP_UHF_selfTestRssi m3 : 25|8@1+ (1,0) [0|0] "" Vector__XXX
 SG_ CP_acRetryTimeoutS m6 : 23|15@1+ (1,0) [0|0] "" Vector__XXX
 SG_ CP_nvm_doorCloseCycles m5 : 21|16@1+ (1,0) [0|0] "" Vector__XXX
 SG_ CP_proximityV_intervalMin10s m0 : 20|16@1+ (0.0001,0) [0|0] "" Vector__XXX
 SG_ CP_refVoltage m4 : 20|8@1+ (0.0070588235,0) [0|0] "" Vector__XXX
 SG_ CP_doorButtonPressDurationMs m7 : 18|10@1+ (1,0) [0|0] "" Vector__XXX
 SG_ CP_UHF_rxNumBytes m3 : 17|8@1+ (1,0) [0|0] "" Vector__XXX
 SG_ CP_UHF_rxOverflow m3 : 16|1@1+ (1,0) [0|0] "" Vector__XXX
 SG_ CP_backCover2Counts m1 : 16|12@1+ (0.025,0) [0|0] "" Vector__XXX
 SG_ CP_pilotLowValue_intervalMin10s m2 : 16|12@1- (0.01,0) [0|0] "" Vector__XXX
 SG_ CP_tlsMemoryUsage_intervalMin10s m6 : 16|7@1+ (0.7874015748031497,0) [0|0] "" Vector__XXX
 SG_ CP_boardTemperature m4 : 12|8@1+ (1.29411764706,-50) [0|0] "" Vector__XXX
 SG_ CP_cpuUtilization_intervalMin10s m7 : 11|7@1+ (0.7874015748031497,0) [0|0] "" Vector__XXX
 SG_ CP_UHF_rssi m3 : 8|8@1+ (1,0) [0|0] "" Vector__XXX
 SG_ CP_tlsMemoryUsage_intervalMax10s m6 : 8|7@1+ (0.7874015748031497,0) [0|0] "" Vector__XXX
 SG_ CP_nvm_doorOpenCycles m5 : 5|16@1+ (1,0) [0|0] "" Vector__XXX
 SG_ CP_5vSwV m4 : 4|8@1+ (0.027450980392156862,0) [0|0] "" Vector__XXX
 SG_ CP_UHF_chipState m3 : 4|3@1+ (1,0) [0|0] "" Vector__XXX
 SG_ CP_backCoverCounts m1 : 4|12@1+ (0.025,0) [0|0] "" Vector__XXX
 SG_ CP_cpuUtilization_intervalMax10s m7 : 4|7@1+ (0.7874015748031497,0) [0|0] "" Vector__XXX
 SG_ CP_nvm_dataValid m5 : 4|1@1+ (1,0) [0|0] "" Vector__XXX
 SG_ CP_pilotLowValue_intervalMax10s m2 : 4|12@1- (0.01,0) [0|0] "" Vector__XXX
 SG_ CP_proximityV_intervalMax10s m0 : 4|16@1+ (0.0001,0) [0|0] "" Vector__XXX
 SG_ CP_loggingSlowSelect M : 0|4@1+ (1,0) [0|0] "" Vector__XXX

BO_ 992 APS_powerStateInputs: 8 Vector__XXX
 SG_ APS_B_forcePowerOffRequest : 16|1@1+ (1,0) [0|0] "" Vector__XXX
 SG_ APS_B_lowPowerRequestor : 12|4@1+ (1,0) [0|0] "" Vector__XXX
 SG_ APS_B_lowPowerRequest : 9|3@1+ (1,0) [0|0] "" Vector__XXX
 SG_ APS_A_forcePowerOffRequest : 8|1@1+ (1,0) [0|0] "" Vector__XXX
 SG_ APS_A_lowPowerRequestor : 4|4@1+ (1,0) [0|0] "" Vector__XXX
 SG_ APS_A_lowPowerRequest : 0|3@1+ (1,0) [0|0] "" Vector__XXX

BO_ 996 PCS2_alertMatrix: 8 Vector__XXX
 SG_ PCS2_a060_cycloAFaulted m0 : 63|1@1+ (1,0) [0|0] "" Vector__XXX
 SG_ PCS2_a120_triggerOdin m1 : 63|1@1+ (1,0) [0|0] "" Vector__XXX
 SG_ PCS2_a059_dcdcEnableLineDeassert m0 : 62|1@1+ (1,0) [0|0] "" Vector__XXX
 SG_ PCS2_a119_useMaxCapForHvImpedanc m1 : 62|1@1+ (1,0) [0|0] "" Vector__XXX
 SG_ PCS2_a058_cycloBTankUncalibrated m0 : 61|1@1+ (1,0) [0|0] "" Vector__XXX
 SG_ PCS2_a118_dcdcFailedToPrechargeT m1 : 61|1@1+ (1,0) [0|0] "" Vector__XXX
 SG_ PCS2_a178_eculogAborted m2 : 61|1@1+ (1,0) [0|0] "" Vector__XXX
 SG_ PCS2_a057_cycloATankUncalibrated m0 : 60|1@1+ (1,0) [0|0] "" Vector__XXX
 SG_ PCS2_a117_vcrightMia m1 : 60|1@1+ (1,0) [0|0] "" Vector__XXX
 SG_ PCS2_a177_unused m2 : 60|1@1+ (1,0) [0|0] "" Vector__XXX
 SG_ PCS2_a056_dcdcBTankUncalibrated m0 : 59|1@1+ (1,0) [0|0] "" Vector__XXX
 SG_ PCS2_a116_chgPersistentFault m1 : 59|1@1+ (1,0) [0|0] "" Vector__XXX
 SG_ PCS2_a176_unused m2 : 59|1@1+ (1,0) [0|0] "" Vector__XXX
 SG_ PCS2_a055_dcdcATankUncalibrated m0 : 58|1@1+ (1,0) [0|0] "" Vector__XXX
 SG_ PCS2_a115_chgWallPowerRemoval m1 : 58|1@1+ (1,0) [0|0] "" Vector__XXX
 SG_ PCS2_a175_LVUVSurgePowerEvent m2 : 58|1@1+ (1,0) [0|0] "" Vector__XXX
 SG_ PCS2_a054_uiMia m0 : 57|1@1+ (1,0) [0|0] "" Vector__XXX
 SG_ PCS2_a114_hvBusEstimatedImpedanc m1 : 57|1@1+ (1,0) [0|0] "" Vector__XXX
 SG_ PCS2_a174_unused m2 : 57|1@1+ (1,0) [0|0] "" Vector__XXX
 SG_ PCS2_a053_hvDcdcControlMIA m0 : 56|1@1+ (1,0) [0|0] "" Vector__XXX
 SG_ PCS2_a113_dcdcTransientCapabilit m1 : 56|1@1+ (1,0) [0|0] "" Vector__XXX
 SG_ PCS2_a173_DcdcALv1OverTemp m2 : 56|1@1+ (1,0) [0|0] "" Vector__XXX
 SG_ PCS2_a052_cpMia m0 : 55|1@1+ (1,0) [0|0] "" Vector__XXX
 SG_ PCS2_a112_chgInputVDropTooHigh m1 : 55|1@1+ (1,0) [0|0] "" Vector__XXX
 SG_ PCS2_a172_llcDcdcLvBusContention m2 : 55|1@1+ (1,0) [0|0] "" Vector__XXX
 SG_ PCS2_a051_bmsMia m0 : 54|1@1+ (1,0) [0|0] "" Vector__XXX
 SG_ PCS2_a111_unused m1 : 54|1@1+ (1,0) [0|0] "" Vector__XXX
 SG_ PCS2_a171_unused m2 : 54|1@1+ (1,0) [0|0] "" Vector__XXX
 SG_ PCS2_a050_vcPcsDCDCInterfaceMia m0 : 53|1@1+ (1,0) [0|0] "" Vector__XXX
 SG_ PCS2_a110_acCurrentIsLimited m1 : 53|1@1+ (1,0) [0|0] "" Vector__XXX
 SG_ PCS2_a170_acChargePowerIsLimited m2 : 53|1@1+ (1,0) [0|0] "" Vector__XXX
 SG_ PCS2_a049_dcacUnderVoltage m0 : 52|1@1+ (1,0) [0|0] "" Vector__XXX
 SG_ PCS2_a109_ACSurgeProtectionTrigg m1 : 52|1@1+ (1,0) [0|0] "" Vector__XXX
 SG_ PCS2_a169_cycloMosfetHealthCheck m2 : 52|1@1+ (1,0) [0|0] "" Vector__XXX
 SG_ PCS2_a048_dcacOverVoltage m0 : 51|1@1+ (1,0) [0|0] "" Vector__XXX
 SG_ PCS2_a108_FunctionalTestModeActi m1 : 51|1@1+ (1,0) [0|0] "" Vector__XXX
 SG_ PCS2_a168_gridFormVoltageDropped m2 : 51|1@1+ (1,0) [0|0] "" Vector__XXX
 SG_ PCS2_a047_hvBattBotUnderVoltage m0 : 50|1@1+ (1,0) [0|0] "" Vector__XXX
 SG_ PCS2_a107_cycloLostCurrentContro m1 : 50|1@1+ (1,0) [0|0] "" Vector__XXX
 SG_ PCS2_a167_unused m2 : 50|1@1+ (1,0) [0|0] "" Vector__XXX
 SG_ PCS2_a046_hvBattBotOverVoltage m0 : 49|1@1+ (1,0) [0|0] "" Vector__XXX
 SG_ PCS2_a106_systemNeutralChassisRm m1 : 49|1@1+ (1,0) [0|0] "" Vector__XXX
 SG_ PCS2_a166_dcdcEnableLinePWMTripM m2 : 49|1@1+ (1,0) [0|0] "" Vector__XXX
 SG_ PCS2_a045_hvBattTopUnderVoltage m0 : 48|1@1+ (1,0) [0|0] "" Vector__XXX
 SG_ PCS2_a105_LineToLineRmsUV m1 : 48|1@1+ (1,0) [0|0] "" Vector__XXX
 SG_ PCS2_a165_dcdc_hwZcdFault2 m2 : 48|1@1+ (1,0) [0|0] "" Vector__XXX
 SG_ PCS2_a044_hvBattTopOverVoltage m0 : 47|1@1+ (1,0) [0|0] "" Vector__XXX
 SG_ PCS2_a104_LineChassisRmsUV m1 : 47|1@1+ (1,0) [0|0] "" Vector__XXX
 SG_ PCS2_a164_dcdc_hwZcdFault1 m2 : 47|1@1+ (1,0) [0|0] "" Vector__XXX
 SG_ PCS2_a043_hvBattUnderVoltage m0 : 46|1@1+ (1,0) [0|0] "" Vector__XXX
 SG_ PCS2_a103_IsoTempSensorIrrationa m1 : 46|1@1+ (1,0) [0|0] "" Vector__XXX
 SG_ PCS2_a163_cycloBRoutineTankInduc m2 : 46|1@1+ (1,0) [0|0] "" Vector__XXX
 SG_ PCS2_a042_hvBattOverVoltage m0 : 45|1@1+ (1,0) [0|0] "" Vector__XXX
 SG_ PCS2_a102_LineToLineInstantaneou m1 : 45|1@1+ (1,0) [0|0] "" Vector__XXX
 SG_ PCS2_a162_cycloARoutineTankInduc m2 : 45|1@1+ (1,0) [0|0] "" Vector__XXX
 SG_ PCS2_a041_hvBusBotUnderVoltage m0 : 44|1@1+ (1,0) [0|0] "" Vector__XXX
 SG_ PCS2_a101_LineChassisInstantaneo m1 : 44|1@1+ (1,0) [0|0] "" Vector__XXX
 SG_ PCS2_a161_vcrearMia m2 : 44|1@1+ (1,0) [0|0] "" Vector__XXX
 SG_ PCS2_a040_hvBusBotOverVoltage m0 : 43|1@1+ (1,0) [0|0] "" Vector__XXX
 SG_ PCS2_a100_LineToLineRmsOV m1 : 43|1@1+ (1,0) [0|0] "" Vector__XXX
 SG_ PCS2_a160_vcleftMia m2 : 43|1@1+ (1,0) [0|0] "" Vector__XXX
 SG_ PCS2_a039_hvBusTopUnderVoltage m0 : 42|1@1+ (1,0) [0|0] "" Vector__XXX
 SG_ PCS2_a099_LineChassisRmsOV m1 : 42|1@1+ (1,0) [0|0] "" Vector__XXX
 SG_ PCS2_a159_dcdcGdpsHealthCheckFai m2 : 42|1@1+ (1,0) [0|0] "" Vector__XXX
 SG_ PCS2_a038_hvBusTopOverVoltage m0 : 41|1@1+ (1,0) [0|0] "" Vector__XXX
 SG_ PCS2_a098_eggright3Mia m1 : 41|1@1+ (1,0) [0|0] "" Vector__XXX
 SG_ PCS2_a158_DcdcHvMosfetTempTooHig m2 : 41|1@1+ (1,0) [0|0] "" Vector__XXX
 SG_ PCS2_a037_hvBusUnderVoltage m0 : 40|1@1+ (1,0) [0|0] "" Vector__XXX
 SG_ PCS2_a097_gtwMia m1 : 40|1@1+ (1,0) [0|0] "" Vector__XXX
 SG_ PCS2_a157_VC_pcsManagementMia m2 : 40|1@1+ (1,0) [0|0] "" Vector__XXX
 SG_ PCS2_a036_hvBusOverVoltage m0 : 39|1@1+ (1,0) [0|0] "" Vector__XXX
 SG_ PCS2_a096_vcsuperMia m1 : 39|1@1+ (1,0) [0|0] "" Vector__XXX
 SG_ PCS2_a156_vcfrontMia m2 : 39|1@1+ (1,0) [0|0] "" Vector__XXX
 SG_ PCS2_a035_lvBusUnderVoltage m0 : 38|1@1+ (1,0) [0|0] "" Vector__XXX
 SG_ PCS2_a095_powershareUnavailable m1 : 38|1@1+ (1,0) [0|0] "" Vector__XXX
 SG_ PCS2_a155_vcbatteryMia m2 : 38|1@1+ (1,0) [0|0] "" Vector__XXX
 SG_ PCS2_a034_lvBusOverVoltage m0 : 37|1@1+ (1,0) [0|0] "" Vector__XXX
 SG_ PCS2_a094_acChargingUnavailable m1 : 37|1@1+ (1,0) [0|0] "" Vector__XXX
 SG_ PCS2_a154_adcReferenceUncalibrat m2 : 37|1@1+ (1,0) [0|0] "" Vector__XXX
 SG_ PCS2_a033_swCoreExcessiveUsage m0 : 36|1@1+ (1,0) [0|0] "" Vector__XXX
 SG_ PCS2_a093_cycloPwmsNotInterleave m1 : 36|1@1+ (1,0) [0|0] "" Vector__XXX
 SG_ PCS2_a153_cyclo_itankZcdIrration m2 : 36|1@1+ (1,0) [0|0] "" Vector__XXX
 SG_ PCS2_a032_DcacBAc2TempTooHigh m0 : 35|1@1+ (1,0) [0|0] "" Vector__XXX
 SG_ PCS2_a092_dcdc_itankZcdIrrationa m1 : 35|1@1+ (1,0) [0|0] "" Vector__XXX
 SG_ PCS2_a152_DcdcBLv3OverTemp m2 : 35|1@1+ (1,0) [0|0] "" Vector__XXX
 SG_ PCS2_a031_DcacBAc1TempTooHigh m0 : 34|1@1+ (1,0) [0|0] "" Vector__XXX
 SG_ PCS2_a091_DcdcTxWindingTempTooHi m1 : 34|1@1+ (1,0) [0|0] "" Vector__XXX
 SG_ PCS2_a151_DcdcBLv1OverTemp m2 : 34|1@1+ (1,0) [0|0] "" Vector__XXX
 SG_ PCS2_a030_DcacAAc2TempTooHigh m0 : 33|1@1+ (1,0) [0|0] "" Vector__XXX
 SG_ PCS2_a090_DcdcLvMosfetTempTooHig m1 : 33|1@1+ (1,0) [0|0] "" Vector__XXX
 SG_ PCS2_a150_dcdcBurstTimingNotMet m2 : 33|1@1+ (1,0) [0|0] "" Vector__XXX
 SG_ PCS2_a029_DcacAAc1TempTooHigh m0 : 32|1@1+ (1,0) [0|0] "" Vector__XXX
 SG_ PCS2_a089_EndOfLineModeActivated m1 : 32|1@1+ (1,0) [0|0] "" Vector__XXX
 SG_ PCS2_a149_buckBoostFault m2 : 32|1@1+ (1,0) [0|0] "" Vector__XXX
 SG_ PCS2_a028_CoolantTempTooHigh m0 : 31|1@1+ (1,0) [0|0] "" Vector__XXX
 SG_ PCS2_a088_chgInputVDropHigh m1 : 31|1@1+ (1,0) [0|0] "" Vector__XXX
 SG_ PCS2_a148_acRelayVoltageIrration m2 : 31|1@1+ (1,0) [0|0] "" Vector__XXX
 SG_ PCS2_a027_AmbientTempTooHigh m0 : 30|1@1+ (1,0) [0|0] "" Vector__XXX
 SG_ PCS2_a087_dcacLVOverVoltage m1 : 30|1@1+ (1,0) [0|0] "" Vector__XXX
 SG_ PCS2_a147_powerRailOverVoltage m2 : 30|1@1+ (1,0) [0|0] "" Vector__XXX
 SG_ PCS2_a026_AcConnectorTempTooHigh m0 : 29|1@1+ (1,0) [0|0] "" Vector__XXX
 SG_ PCS2_a086_dcacLVUnderVoltage m1 : 29|1@1+ (1,0) [0|0] "" Vector__XXX
 SG_ PCS2_a146_acLineSharedCurrentCon m2 : 29|1@1+ (1,0) [0|0] "" Vector__XXX
 SG_ PCS2_a025_DcacBTxTempTooHigh m0 : 28|1@1+ (1,0) [0|0] "" Vector__XXX
 SG_ PCS2_a085_dcacEnableLineDeassert m1 : 28|1@1+ (1,0) [0|0] "" Vector__XXX
 SG_ PCS2_a145_DcdcHvdcGdpsUncalibrat m2 : 28|1@1+ (1,0) [0|0] "" Vector__XXX
 SG_ PCS2_a024_DcacATxTempTooHigh m0 : 27|1@1+ (1,0) [0|0] "" Vector__XXX
 SG_ PCS2_a084_acNCurrentOffsetIrrati m1 : 27|1@1+ (1,0) [0|0] "" Vector__XXX
 SG_ PCS2_a144_DcTankGdpsUncalibrated m2 : 27|1@1+ (1,0) [0|0] "" Vector__XXX
 SG_ PCS2_a023_dcdcEnableFunctionalit m0 : 26|1@1+ (1,0) [0|0] "" Vector__XXX
 SG_ PCS2_a083_acL3CurrentOffsetIrrat m1 : 26|1@1+ (1,0) [0|0] "" Vector__XXX
 SG_ PCS2_a143_AcTankGdpsUncalibrated m2 : 26|1@1+ (1,0) [0|0] "" Vector__XXX
 SG_ PCS2_a022_dcacEnableFunctionalit m0 : 25|1@1+ (1,0) [0|0] "" Vector__XXX
 SG_ PCS2_a082_acL2CurrentOffsetIrrat m1 : 25|1@1+ (1,0) [0|0] "" Vector__XXX
 SG_ PCS2_a142_AcLineGdpsUncalibrated m2 : 25|1@1+ (1,0) [0|0] "" Vector__XXX
 SG_ PCS2_a021_powerRailUnderVoltage m0 : 24|1@1+ (1,0) [0|0] "" Vector__XXX
 SG_ PCS2_a081_acL1CurrentOffsetIrrat m1 : 24|1@1+ (1,0) [0|0] "" Vector__XXX
 SG_ PCS2_a141_boostOverCurrent m2 : 24|1@1+ (1,0) [0|0] "" Vector__XXX
 SG_ PCS2_a020_DcacBDcTempTooHigh m0 : 23|1@1+ (1,0) [0|0] "" Vector__XXX
 SG_ PCS2_a080_acL3NVoltageOffsetIrra m1 : 23|1@1+ (1,0) [0|0] "" Vector__XXX
 SG_ PCS2_a140_dcdcHalfBusBalancerSat m2 : 23|1@1+ (1,0) [0|0] "" Vector__XXX
 SG_ PCS2_a019_DcacADcTempTooHigh m0 : 22|1@1+ (1,0) [0|0] "" Vector__XXX
 SG_ PCS2_a079_acL2NVoltageOffsetIrra m1 : 22|1@1+ (1,0) [0|0] "" Vector__XXX
 SG_ PCS2_a139_unused m2 : 22|1@1+ (1,0) [0|0] "" Vector__XXX
 SG_ PCS2_a018_dcdcBTankOverCurrent m0 : 21|1@1+ (1,0) [0|0] "" Vector__XXX
 SG_ PCS2_a078_acL1NVoltageOffsetIrra m1 : 21|1@1+ (1,0) [0|0] "" Vector__XXX
 SG_ PCS2_a138_unused m2 : 21|1@1+ (1,0) [0|0] "" Vector__XXX
 SG_ PCS2_a017_DcdcBLv2OverTemp m0 : 20|1@1+ (1,0) [0|0] "" Vector__XXX
 SG_ PCS2_a077_lvBusVoltSensorIrratio m1 : 20|1@1+ (1,0) [0|0] "" Vector__XXX
 SG_ PCS2_a137_cycloBMosfetHealthChec m2 : 20|1@1+ (1,0) [0|0] "" Vector__XXX
 SG_ PCS2_a016_dcdcATankOverCurrent m0 : 19|1@1+ (1,0) [0|0] "" Vector__XXX
 SG_ PCS2_a076_hvBusFullSensorIrratio m1 : 19|1@1+ (1,0) [0|0] "" Vector__XXX
 SG_ PCS2_a136_cycloAMosfetHealthChec m2 : 19|1@1+ (1,0) [0|0] "" Vector__XXX
 SG_ PCS2_a015_DcdcAHvOverTemp m0 : 18|1@1+ (1,0) [0|0] "" Vector__XXX
 SG_ PCS2_a075_hvBattFullSensorIrrati m1 : 18|1@1+ (1,0) [0|0] "" Vector__XXX
 SG_ PCS2_a135_backgroundTaskOverRun m2 : 18|1@1+ (1,0) [0|0] "" Vector__XXX
 SG_ PCS2_a014_cycloBTankOverCurrent m0 : 17|1@1+ (1,0) [0|0] "" Vector__XXX
 SG_ PCS2_a074_hvBusTopSensorIrration m1 : 17|1@1+ (1,0) [0|0] "" Vector__XXX
 SG_ PCS2_a134_unused m2 : 17|1@1+ (1,0) [0|0] "" Vector__XXX
 SG_ PCS2_a013_DcdcALv2OverTemp m0 : 16|1@1+ (1,0) [0|0] "" Vector__XXX
 SG_ PCS2_a073_hvBusBotSensorIrration m1 : 16|1@1+ (1,0) [0|0] "" Vector__XXX
 SG_ PCS2_a133_unused m2 : 16|1@1+ (1,0) [0|0] "" Vector__XXX
 SG_ PCS2_a012_cycloATankOverCurrent m0 : 15|1@1+ (1,0) [0|0] "" Vector__XXX
 SG_ PCS2_a072_hvBattTopSensorIrratio m1 : 15|1@1+ (1,0) [0|0] "" Vector__XXX
 SG_ PCS2_a132_microgridDroopDetected m2 : 15|1@1+ (1,0) [0|0] "" Vector__XXX
 SG_ PCS2_a011_hvdcOverCurrent m0 : 14|1@1+ (1,0) [0|0] "" Vector__XXX
 SG_ PCS2_a071_hvBattBotSensorIrratio m1 : 14|1@1+ (1,0) [0|0] "" Vector__XXX
 SG_ PCS2_a131_microgridHeartbeatDete m2 : 14|1@1+ (1,0) [0|0] "" Vector__XXX
 SG_ PCS2_a010_acLNOverCurrent m0 : 13|1@1+ (1,0) [0|0] "" Vector__XXX
 SG_ PCS2_a070_dcdcBlifetimeEnergyRec m1 : 13|1@1+ (1,0) [0|0] "" Vector__XXX
 SG_ PCS2_a130_IONVMMServerRetryEvent m2 : 13|1@1+ (1,0) [0|0] "" Vector__XXX
 SG_ PCS2_a009_acL3OverCurrent m0 : 12|1@1+ (1,0) [0|0] "" Vector__XXX
 SG_ PCS2_a069_dcdcAlifetimeEnergyRec m1 : 12|1@1+ (1,0) [0|0] "" Vector__XXX
 SG_ PCS2_a129_lossOfZcdEventControl m2 : 12|1@1+ (1,0) [0|0] "" Vector__XXX
 SG_ PCS2_a008_acL3NOverVoltage m0 : 11|1@1+ (1,0) [0|0] "" Vector__XXX
 SG_ PCS2_a068_nvmSubsystemStalled m1 : 11|1@1+ (1,0) [0|0] "" Vector__XXX
 SG_ PCS2_a128_cycloBgdpsHealthCheckF m2 : 11|1@1+ (1,0) [0|0] "" Vector__XXX
 SG_ PCS2_a007_acL2OverCurrent m0 : 10|1@1+ (1,0) [0|0] "" Vector__XXX
 SG_ PCS2_a067_cycloBTankParametersOu m1 : 10|1@1+ (1,0) [0|0] "" Vector__XXX
 SG_ PCS2_a127_cycloAgdpsHealthCheckF m2 : 10|1@1+ (1,0) [0|0] "" Vector__XXX
 SG_ PCS2_a006_acL2NOverVoltage m0 : 9|1@1+ (1,0) [0|0] "" Vector__XXX
 SG_ PCS2_a066_cycloATankParametersOu m1 : 9|1@1+ (1,0) [0|0] "" Vector__XXX
 SG_ PCS2_a126_ipcSuccessiveLockGrabF m2 : 9|1@1+ (1,0) [0|0] "" Vector__XXX
 SG_ PCS2_a005_acL1OverCurrent m0 : 8|1@1+ (1,0) [0|0] "" Vector__XXX
 SG_ PCS2_a065_dcdcBTankParametersOut m1 : 8|1@1+ (1,0) [0|0] "" Vector__XXX
 SG_ PCS2_a125_cycloIdleShortingNeutr m2 : 8|1@1+ (1,0) [0|0] "" Vector__XXX
 SG_ PCS2_a004_acL1NOverVoltage m0 : 7|1@1+ (1,0) [0|0] "" Vector__XXX
 SG_ PCS2_a064_dcdcATankParametersOut m1 : 7|1@1+ (1,0) [0|0] "" Vector__XXX
 SG_ PCS2_a124_dcacItankSoftwareOC m2 : 7|1@1+ (1,0) [0|0] "" Vector__XXX
 SG_ PCS2_a003_softwareAssertion m0 : 6|1@1+ (1,0) [0|0] "" Vector__XXX
 SG_ PCS2_a063_chgUnknownGridConfig m1 : 6|1@1+ (1,0) [0|0] "" Vector__XXX
 SG_ PCS2_a123_DcdcBHvOverTemp m2 : 6|1@1+ (1,0) [0|0] "" Vector__XXX
 SG_ PCS2_a002_canRationality m0 : 5|1@1+ (1,0) [0|0] "" Vector__XXX
 SG_ PCS2_a062_acVoltageNotPresent m1 : 5|1@1+ (1,0) [0|0] "" Vector__XXX
 SG_ PCS2_a122_dcacLifetimekVAhRecord m2 : 5|1@1+ (1,0) [0|0] "" Vector__XXX
 SG_ PCS2_a001_watchdogAlarmed m0 : 4|1@1+ (1,0) [0|0] "" Vector__XXX
 SG_ PCS2_a061_cycloBFaulted m1 : 4|1@1+ (1,0) [0|0] "" Vector__XXX
 SG_ PCS2_a121_insufficientCoolingDet m2 : 4|1@1+ (1,0) [0|0] "" Vector__XXX
 SG_ PCS2_d181_dcdcConverterVoltSenso m3 : 4|1@1+ (1,0) [0|0] "" Vector__XXX
 SG_ PCS2_matrixIndex M : 0|4@1+ (1,0) [0|0] "" Vector__XXX

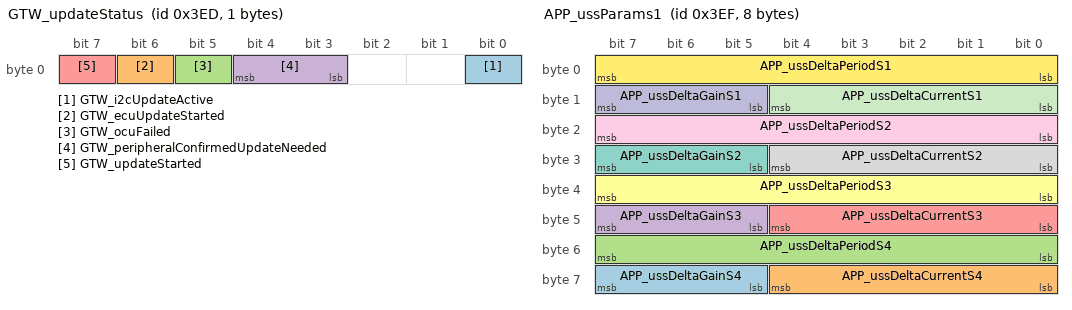
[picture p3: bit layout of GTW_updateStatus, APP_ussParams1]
BO_ 1005 GTW_updateStatus: 1 Vector__XXX
 SG_ GTW_i2cUpdateActive : 0|1@0+ (1,0) [0|0] "" Vector__XXX
 SG_ GTW_ecuUpdateStarted : 6|1@1+ (1,0) [0|0] "" Vector__XXX
 SG_ GTW_ocuFailed : 5|1@1+ (1,0) [0|0] "" Vector__XXX
 SG_ GTW_peripheralConfirmedUpdateNeeded : 4|2@0+ (1,0) [0|0] "" Vector__XXX
 SG_ GTW_updateStarted : 7|1@0+ (1,0) [0|0] "" Vector__XXX

BO_ 1007 APP_ussParams1: 8 Vector__XXX
 SG_ APP_ussDeltaGainS4 : 61|3@1- (1,0) [0|0] "" Vector__XXX
 SG_ APP_ussDeltaCurrentS4 : 56|5@1- (1,0) [0|0] "" Vector__XXX
 SG_ APP_ussDeltaPeriodS4 : 48|8@1- (1,0) [0|0] "" Vector__XXX
 SG_ APP_ussDeltaGainS3 : 45|3@1- (1,0) [0|0] "" Vector__XXX
 SG_ APP_ussDeltaCurrentS3 : 40|5@1- (1,0) [0|0] "" Vector__XXX
 SG_ APP_ussDeltaPeriodS3 : 32|8@1- (1,0) [0|0] "" Vector__XXX
 SG_ APP_ussDeltaGainS2 : 29|3@1- (1,0) [0|0] "" Vector__XXX
 SG_ APP_ussDeltaCurrentS2 : 24|5@1- (1,0) [0|0] "" Vector__XXX
 SG_ APP_ussDeltaPeriodS2 : 16|8@1- (1,0) [0|0] "" Vector__XXX
 SG_ APP_ussDeltaGainS1 : 13|3@1- (1,0) [0|0] "" Vector__XXX
 SG_ APP_ussDeltaCurrentS1 : 8|5@1- (1,0) [0|0] "" Vector__XXX
 SG_ APP_ussDeltaPeriodS1 : 0|8@1- (1,0) [0|0] "" Vector__XXX

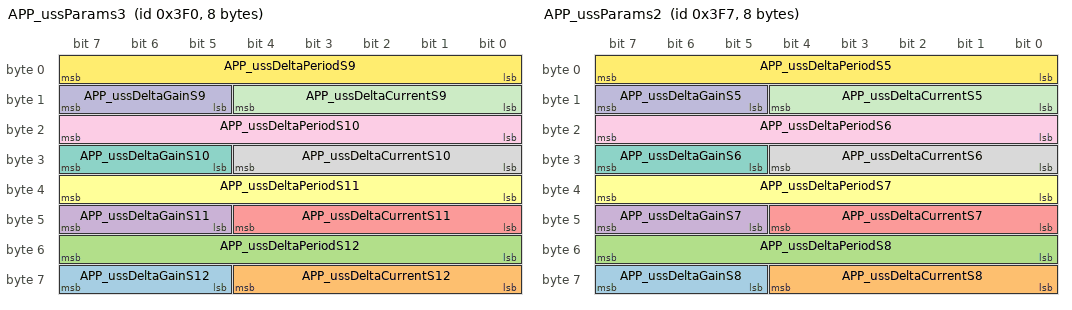
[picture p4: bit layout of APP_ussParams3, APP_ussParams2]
BO_ 1008 APP_ussParams3: 8 Vector__XXX
 SG_ APP_ussDeltaGainS12 : 61|3@1- (1,0) [0|0] "" Vector__XXX
 SG_ APP_ussDeltaCurrentS12 : 56|5@1- (1,0) [0|0] "" Vector__XXX
 SG_ APP_ussDeltaPeriodS12 : 48|8@1- (1,0) [0|0] "" Vector__XXX
 SG_ APP_ussDeltaGainS11 : 45|3@1- (1,0) [0|0] "" Vector__XXX
 SG_ APP_ussDeltaCurrentS11 : 40|5@1- (1,0) [0|0] "" Vector__XXX
 SG_ APP_ussDeltaPeriodS11 : 32|8@1- (1,0) [0|0] "" Vector__XXX
 SG_ APP_ussDeltaGainS10 : 29|3@1- (1,0) [0|0] "" Vector__XXX
 SG_ APP_ussDeltaCurrentS10 : 24|5@1- (1,0) [0|0] "" Vector__XXX
 SG_ APP_ussDeltaPeriodS10 : 16|8@1- (1,0) [0|0] "" Vector__XXX
 SG_ APP_ussDeltaGainS9 : 13|3@1- (1,0) [0|0] "" Vector__XXX
 SG_ APP_ussDeltaCurrentS9 : 8|5@1- (1,0) [0|0] "" Vector__XXX
 SG_ APP_ussDeltaPeriodS9 : 0|8@1- (1,0) [0|0] "" Vector__XXX

BO_ 1013 VCFRONT_lighting: 8 Vector__XXX
 SG_ VCFRONT_indicatorRightInternal : 52|2@1+ (1,0) [0|0] "" Vector__XXX
 SG_ VCFRONT_indicatorLeftInternal : 50|2@1+ (1,0) [0|0] "" Vector__XXX
 SG_ VC_fastFlashHazardsActive : 49|1@1+ (1,0) [0|0] "" Vector__XXX
 SG_ VCFRONT_lightingCustomState : 44|5@1+ (1,0) [0|0] "" Vector__XXX
 SG_ VCFRONT_highBeamLatchingState : 42|2@1+ (1,0) [0|0] "" Vector__XXX
 SG_ VCFRONT_turnIndicatorStalk : 40|2@1+ (1,0) [0|0] "" Vector__XXX
 SG_ VCFRONT_headlightsReadyOrTimedOut : 39|1@1+ (1,0) [0|0] "" Vector__XXX
 SG_ VCFRONT_frontFogFunctionState : 38|1@1+ (1,0) [0|0] "" Vector__XXX
 SG_ VCFRONT_latchedHighBeamsFunctionState : 37|1@1+ (1,0) [0|0] "" Vector__XXX
 SG_ VCFRONT_intHighBeamsFunctionState : 36|1@1+ (1,0) [0|0] "" Vector__XXX
 SG_ VCFRONT_lightingCoreState : 32|4@1+ (1,0) [0|0] "" Vector__XXX
 SG_ VCFRONT_dynamicBrakeLightState : 30|2@1+ (1,0) [0|0] "" Vector__XXX
 SG_ VCFRONT_highBeamControlState : 28|2@1+ (1,0) [0|0] "" Vector__XXX
 SG_ VCFRONT_hazardSwitchBacklight : 27|1@1+ (1,0) [0|0] "" Vector__XXX
 SG_ VCFRONT_courtesyLightingRequest : 24|1@1+ (1,0) [0|0] "" Vector__XXX
 SG_ VCFRONT_switchLightingBrightness : 16|8@1+ (0.5,0) [0|0] "" Vector__XXX
 SG_ VCFRONT_ambientLightingBrightnes : 8|8@1+ (0.5,0) [0|0] "" Vector__XXX
 SG_ VCFRONT_hazardLightRequest : 4|4@1+ (1,0) [0|0] "" Vector__XXX
 SG_ VCFRONT_indicatorRightRequest : 2|2@1+ (1,0) [0|0] "" Vector__XXX
 SG_ VCFRONT_indicatorLeftRequest : 0|2@1+ (1,0) [0|0] "" Vector__XXX

BO_ 1014 VCFRONT_lightStatus: 8 Vector__XXX
 SG_ VC_hcmrMigrationWindowOpen m0 : 63|1@1+ (1,0) [0|0] "" Vector__XXX
 SG_ VC_hcmrMigrationStallDetectionEnabled m0 : 62|1@1+ (1,0) [0|0] "" Vector__XXX
 SG_ VC_hcmrMigrationMigrationNotStarted m0 : 61|1@1+ (1,0) [0|0] "" Vector__XXX
 SG_ VC_hcmrMigrationOnLVSupport m0 : 60|1@1+ (1,0) [0|0] "" Vector__XXX
 SG_ VC_hcmrMigrationVehicleUpdateActive m0 : 59|1@1+ (1,0) [0|0] "" Vector__XXX
 SG_ VC_hcmrMigrationOTAStateNotActive m0 : 58|1@1+ (1,0) [0|0] "" Vector__XXX
 SG_ VC_hcmrMigrationOTAStateWasActive m0 : 57|1@1+ (1,0) [0|0] "" Vector__XXX
 SG_ VC_hcmrMigrationValidWeather m0 : 56|1@1+ (1,0) [0|0] "" Vector__XXX
 SG_ VCFRONT_headlampRoadClass m1 : 55|2@1+ (1,0) [0|0] "" Vector__XXX
 SG_ VC_hcmlMigrationWindowOpen m0 : 55|1@1+ (1,0) [0|0] "" Vector__XXX
 SG_ VC_hcmlMigrationStallDetectionEnabled m0 : 54|1@1+ (1,0) [0|0] "" Vector__XXX
 SG_ VC_hcmlMigrationMigrationNotStarted m0 : 53|1@1+ (1,0) [0|0] "" Vector__XXX
 SG_ VC_hcmlMigrationOnLVSupport m0 : 52|1@1+ (1,0) [0|0] "" Vector__XXX
 SG_ VC_hcmlMigrationVehicleUpdateActive m0 : 51|1@1+ (1,0) [0|0] "" Vector__XXX
 SG_ VC_hcmlMigrationOTAStateNotActive m0 : 50|1@1+ (1,0) [0|0] "" Vector__XXX
 SG_ VC_hcmlMigrationOTAStateWasActive m0 : 49|1@1+ (1,0) [0|0] "" Vector__XXX
 SG_ VC_hcmlMigrationValidWeather m0 : 48|1@1+ (1,0) [0|0] "" Vector__XXX
 SG_ VCFRONT_headlampBendAngle m1 : 47|8@1- (0.1,0) [0|0] "" Vector__XXX
 SG_ VCFRONT_advancedDrivingBeamStatus m1 : 45|2@1+ (1,0) [0|0] "" Vector__XXX
 SG_ VCFRONT_isBendLightingAvailable m1 : 44|1@1+ (1,0) [0|0] "" Vector__XXX
 SG_ VCFRONT_isAdaptiveHighBeamFaulted m1 : 43|1@1+ (1,0) [0|0] "" Vector__XXX
 SG_ VCFRONT_isAdaptiveHighBeamAvailable m1 : 42|1@1+ (1,0) [0|0] "" Vector__XXX
 SG_ VCFRONT_lightStatusMuxIndex M : 39|3@1+ (1,0) [0|0] "" Vector__XXX
 SG_ VC_leftHeadlampHealth : 36|3@1+ (1,0) [0|0] "" Vector__XXX
 SG_ VC_rightHeadlampHealth : 33|3@1+ (1,0) [0|0] "" Vector__XXX
 SG_ VCFRONT_lowBeamsOnForDRL : 32|1@1+ (1,0) [0|0] "" Vector__XXX
 SG_ VCFRONT_lowBeamRightReadyForAiming : 31|1@1+ (1,0) [0|0] "" Vector__XXX
 SG_ VCFRONT_lowBeamLeftReadyForAiming : 30|1@1+ (1,0) [0|0] "" Vector__XXX
 SG_ VCFRONT_parkRightStatus : 28|2@1+ (1,0) [0|0] "" Vector__XXX
 SG_ VCFRONT_parkLeftStatus : 26|2@1+ (1,0) [0|0] "" Vector__XXX
 SG_ VCFRONT_turnSignalRightStatus : 24|2@1+ (1,0) [0|0] "" Vector__XXX
 SG_ VCFRONT_turnSignalLeftStatus : 22|2@1+ (1,0) [0|0] "" Vector__XXX
 SG_ VCFRONT_sideRepeaterRightStatus : 20|2@1+ (1,0) [0|0] "" Vector__XXX
 SG_ VCFRONT_sideRepeaterLeftStatus : 18|2@1+ (1,0) [0|0] "" Vector__XXX
 SG_ VCFRONT_sideMarkersStatus : 16|2@1+ (1,0) [0|0] "" Vector__XXX
 SG_ VCFRONT_fogRightStatus : 14|2@1+ (1,0) [0|0] "" Vector__XXX
 SG_ VCFRONT_fogLeftStatus : 12|2@1+ (1,0) [0|0] "" Vector__XXX
 SG_ VCFRONT_DRLRightStatus : 10|2@1+ (1,0) [0|0] "" Vector__XXX
 SG_ VCFRONT_DRLLeftStatus : 8|2@1+ (1,0) [0|0] "" Vector__XXX
 SG_ VCFRONT_highBeamRightStatus : 6|2@1+ (1,0) [0|0] "" Vector__XXX
 SG_ VCFRONT_highBeamLeftStatus : 4|2@1+ (1,0) [0|0] "" Vector__XXX
 SG_ VCFRONT_lowBeamRightStatus : 2|2@1+ (1,0) [0|0] "" Vector__XXX
 SG_ VCFRONT_lowBeamLeftStatus : 0|2@1+ (1,0) [0|0] "" Vector__XXX

BO_ 1015 APP_ussParams2: 8 Vector__XXX
 SG_ APP_ussDeltaGainS8 : 61|3@1- (1,0) [0|0] "" Vector__XXX
 SG_ APP_ussDeltaCurrentS8 : 56|5@1- (1,0) [0|0] "" Vector__XXX
 SG_ APP_ussDeltaPeriodS8 : 48|8@1- (1,0) [0|0] "" Vector__XXX
 SG_ APP_ussDeltaGainS7 : 45|3@1- (1,0) [0|0] "" Vector__XXX
 SG_ APP_ussDeltaCurrentS7 : 40|5@1- (1,0) [0|0] "" Vector__XXX
 SG_ APP_ussDeltaPeriodS7 : 32|8@1- (1,0) [0|0] "" Vector__XXX
 SG_ APP_ussDeltaGainS6 : 29|3@1- (1,0) [0|0] "" Vector__XXX
 SG_ APP_ussDeltaCurrentS6 : 24|5@1- (1,0) [0|0] "" Vector__XXX
 SG_ APP_ussDeltaPeriodS6 : 16|8@1- (1,0) [0|0] "" Vector__XXX
 SG_ APP_ussDeltaGainS5 : 13|3@1- (1,0) [0|0] "" Vector__XXX
 SG_ APP_ussDeltaCurrentS5 : 8|5@1- (1,0) [0|0] "" Vector__XXX
 SG_ APP_ussDeltaPeriodS5 : 0|8@1- (1,0) [0|0] "" Vector__XXX

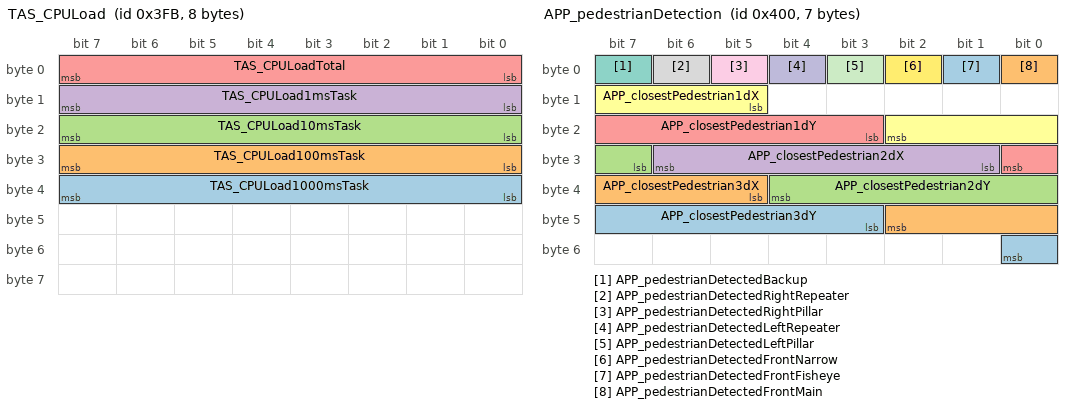
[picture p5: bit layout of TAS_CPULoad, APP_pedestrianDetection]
BO_ 1019 TAS_CPULoad: 8 Vector__XXX
 SG_ TAS_CPULoad1000msTask : 32|8@1+ (1,0) [0|0] "" Vector__XXX
 SG_ TAS_CPULoad100msTask : 24|8@1+ (1,0) [0|0] "" Vector__XXX
 SG_ TAS_CPULoad10msTask : 16|8@1+ (1,0) [0|0] "" Vector__XXX
 SG_ TAS_CPULoad1msTask : 8|8@1+ (1,0) [0|0] "" Vector__XXX
 SG_ TAS_CPULoadTotal : 0|8@1+ (1,0) [0|0] "" Vector__XXX

BO_ 1023 APS_selfTest: 8 Vector__XXX
 SG_ APS_selfTestReserved : 0|64@1+ (1,0) [0|0] "" Vector__XXX

BO_ 1024 APP_pedestrianDetection: 7 Vector__XXX
 SG_ APP_closestPedestrian3dY : 43|6@1- (0.4,0) [0|0] "" Vector__XXX
 SG_ APP_closestPedestrian3dX : 37|6@1- (0.4,0) [0|0] "" Vector__XXX
 SG_ APP_closestPedestrian2dY : 31|6@1- (0.4,0) [0|0] "" Vector__XXX
 SG_ APP_closestPedestrian2dX : 25|6@1- (0.4,0) [0|0] "" Vector__XXX
 SG_ APP_closestPedestrian1dY : 19|6@1- (0.4,0) [0|0] "" Vector__XXX
 SG_ APP_closestPedestrian1dX : 13|6@1- (0.4,0) [0|0] "" Vector__XXX
 SG_ APP_pedestrianDetectedBackup : 7|1@1+ (1,0) [0|0] "" Vector__XXX
 SG_ APP_pedestrianDetectedRightRepeater : 6|1@1+ (1,0) [0|0] "" Vector__XXX
 SG_ APP_pedestrianDetectedRightPillar : 5|1@1+ (1,0) [0|0] "" Vector__XXX
 SG_ APP_pedestrianDetectedLeftRepeater : 4|1@1+ (1,0) [0|0] "" Vector__XXX
 SG_ APP_pedestrianDetectedLeftPillar : 3|1@1+ (1,0) [0|0] "" Vector__XXX
 SG_ APP_pedestrianDetectedFrontNarrow : 2|1@1+ (1,0) [0|0] "" Vector__XXX
 SG_ APP_pedestrianDetectedFrontFisheye : 1|1@1+ (1,0) [0|0] "" Vector__XXX
 SG_ APP_pedestrianDetectedFrontMain : 0|1@1+ (1,0) [0|0] "" Vector__XXX

BO_ 1027 VCFRONT1_eFuseDebugStatus: 8 Vector__XXX
 SG_ VCFRONT1_EPAS2EFuseOCThreshold m0 : 48|5@1+ (1,0) [0|0] "" Vector__XXX
 SG_ VCFRONT1_autopilot2EFuseOCThresh m3 : 48|5@1+ (1,0) [0|0] "" Vector__XXX
 SG_ VCFRONT1_brakeMotorECU2EFuseOCTh m4 : 48|5@1+ (1,0) [0|0] "" Vector__XXX
 SG_ VCFRONT1_bridgeEFuseOCThreshold m5 : 48|5@1+ (1,0) [0|0] "" Vector__XXX
 SG_ VCFRONT1_pcsEFuseOCThreshold m2 : 48|5@1+ (1,0) [0|0] "" Vector__XXX
 SG_ VCFRONT1_rightControllerEFuseOCT m1 : 48|5@1+ (1,0) [0|0] "" Vector__XXX
 SG_ VCFRONT1_EPAS2EFuseHardShortThre m0 : 44|4@1+ (1,0) [0|0] "" Vector__XXX
 SG_ VCFRONT1_autopilot2EFuseHardShor m3 : 44|4@1+ (1,0) [0|0] "" Vector__XXX
 SG_ VCFRONT1_brakeMotorECU2EFuseHard m4 : 44|4@1+ (1,0) [0|0] "" Vector__XXX
 SG_ VCFRONT1_bridgeEFuseHardShortThr m5 : 44|4@1+ (1,0) [0|0] "" Vector__XXX
 SG_ VCFRONT1_pcsEFuseHardShortThresh m2 : 44|4@1+ (1,0) [0|0] "" Vector__XXX
 SG_ VCFRONT1_rightControllerEFuseHar m1 : 44|4@1+ (1,0) [0|0] "" Vector__XXX
 SG_ VCFRONT1_EPAS2EFuseManagerState m0 : 40|4@1+ (1,0) [0|0] "" Vector__XXX
 SG_ VCFRONT1_autopilot2EFuseManagerS m3 : 40|4@1+ (1,0) [0|0] "" Vector__XXX
 SG_ VCFRONT1_brakeMotorECU2EFuseMana m4 : 40|4@1+ (1,0) [0|0] "" Vector__XXX
 SG_ VCFRONT1_bridgeEFuseManagerState m5 : 40|4@1+ (1,0) [0|0] "" Vector__XXX
 SG_ VCFRONT1_pcsEFuseManagerState m2 : 40|4@1+ (1,0) [0|0] "" Vector__XXX
 SG_ VCFRONT1_rightControllerEFuseMan m1 : 40|4@1+ (1,0) [0|0] "" Vector__XXX
 SG_ VCFRONT1_EPAS2EFuseTemperature m0 : 32|8@1+ (1,-40) [0|0] "" Vector__XXX
 SG_ VCFRONT1_autopilot2EFuseTemperat m3 : 32|8@1+ (1,-40) [0|0] "" Vector__XXX
 SG_ VCFRONT1_brakeMotorECU2EFuseTemp m4 : 32|8@1+ (1,-40) [0|0] "" Vector__XXX
 SG_ VCFRONT1_bridgeEFuseTemperature m5 : 32|8@1+ (1,-40) [0|0] "" Vector__XXX
 SG_ VCFRONT1_pcsEFuseTemperature m2 : 32|8@1+ (1,-40) [0|0] "" Vector__XXX
 SG_ VCFRONT1_rightControllerEFuseTem m1 : 32|8@1+ (1,-40) [0|0] "" Vector__XXX
 SG_ VCFRONT1_EPAS2EFuseVoltage m0 : 24|8@1+ (0.07,0) [0|0] "" Vector__XXX
 SG_ VCFRONT1_autopilot2EFuseVoltage m3 : 24|8@1+ (0.07,0) [0|0] "" Vector__XXX
 SG_ VCFRONT1_brakeMotorECU2EFuseVolt m4 : 24|8@1+ (0.07,0) [0|0] "" Vector__XXX
 SG_ VCFRONT1_bridgeEFuseVoltage m5 : 24|8@1+ (0.07,0) [0|0] "" Vector__XXX
 SG_ VCFRONT1_pcsEFuseVoltage m2 : 24|8@1+ (0.07,0) [0|0] "" Vector__XXX
 SG_ VCFRONT1_rightControllerEFuseVol m1 : 24|8@1+ (0.07,0) [0|0] "" Vector__XXX
 SG_ VCFRONT1_EPAS2EFuseBypassDesired m0 : 23|1@1+ (1,0) [0|0] "" Vector__XXX
 SG_ VCFRONT1_autopilot2EFuseBypassDe m3 : 23|1@1+ (1,0) [0|0] "" Vector__XXX
 SG_ VCFRONT1_brakeMotorECU2EFus_0000 m4 : 23|1@1+ (1,0) [0|0] "" Vector__XXX
 SG_ VCFRONT1_bridgeEFuseBypassDesire m5 : 23|1@1+ (1,0) [0|0] "" Vector__XXX
 SG_ VCFRONT1_pcsEFuseBypassDesired m2 : 23|1@1+ (1,0) [0|0] "" Vector__XXX
 SG_ VCFRONT1_rightControllerEFu_0000 m1 : 23|1@1+ (1,0) [0|0] "" Vector__XXX
 SG_ VCFRONT1_EPAS2EFuseBypass m0 : 22|1@1+ (1,0) [0|0] "" Vector__XXX
 SG_ VCFRONT1_autopilot2EFuseBypass m3 : 22|1@1+ (1,0) [0|0] "" Vector__XXX
 SG_ VCFRONT1_brakeMotorECU2EFuseBypa m4 : 22|1@1+ (1,0) [0|0] "" Vector__XXX
 SG_ VCFRONT1_bridgeEFuseBypass m5 : 22|1@1+ (1,0) [0|0] "" Vector__XXX
 SG_ VCFRONT1_pcsEFuseBypass m2 : 22|1@1+ (1,0) [0|0] "" Vector__XXX
 SG_ VCFRONT1_rightControllerEFuseByp m1 : 22|1@1+ (1,0) [0|0] "" Vector__XXX
 SG_ VCFRONT1_EPAS2EFuseOutputDesired m0 : 21|1@1+ (1,0) [0|0] "" Vector__XXX
 SG_ VCFRONT1_autopilot2EFuseOutputDe m3 : 21|1@1+ (1,0) [0|0] "" Vector__XXX
 SG_ VCFRONT1_brakeMotorECU2EFus_0001 m4 : 21|1@1+ (1,0) [0|0] "" Vector__XXX
 SG_ VCFRONT1_bridgeEFuseOutputDesire m5 : 21|1@1+ (1,0) [0|0] "" Vector__XXX
 SG_ VCFRONT1_pcsEFuseOutputDesired m2 : 21|1@1+ (1,0) [0|0] "" Vector__XXX
 SG_ VCFRONT1_rightControllerEFu_0001 m1 : 21|1@1+ (1,0) [0|0] "" Vector__XXX
 SG_ VCFRONT1_EPAS2EFuseOutput m0 : 20|1@1+ (1,0) [0|0] "" Vector__XXX
 SG_ VCFRONT1_autopilot2EFuseOutput m3 : 20|1@1+ (1,0) [0|0] "" Vector__XXX
 SG_ VCFRONT1_brakeMotorECU2EFuseOutp m4 : 20|1@1+ (1,0) [0|0] "" Vector__XXX
 SG_ VCFRONT1_bridgeEFuseOutput m5 : 20|1@1+ (1,0) [0|0] "" Vector__XXX
 SG_ VCFRONT1_pcsEFuseOutput m2 : 20|1@1+ (1,0) [0|0] "" Vector__XXX
 SG_ VCFRONT1_rightControllerEFuseOut m1 : 20|1@1+ (1,0) [0|0] "" Vector__XXX
 SG_ VCFRONT1_EPAS2EFuseCurrent m0 : 8|12@1+ (0.05,0) [0|0] "" Vector__XXX
 SG_ VCFRONT1_autopilot2EFuseCurrent m3 : 8|12@1+ (0.05,0) [0|0] "" Vector__XXX
 SG_ VCFRONT1_brakeMotorECU2EFuseCurr m4 : 8|12@1+ (0.05,0) [0|0] "" Vector__XXX
 SG_ VCFRONT1_bridgeEFuseCurrent m5 : 8|12@1+ (0.05,0) [0|0] "" Vector__XXX
 SG_ VCFRONT1_pcsEFuseCurrent m2 : 8|12@1+ (0.05,0) [0|0] "" Vector__XXX
 SG_ VCFRONT1_rightControllerEFuseCur m1 : 8|12@1+ (0.05,0) [0|0] "" Vector__XXX
 SG_ VCFRONT1_EPAS2EFuseState m0 : 3|3@1+ (1,0) [0|0] "" Vector__XXX
 SG_ VCFRONT1_autopilot2EFuseState m3 : 3|3@1+ (1,0) [0|0] "" Vector__XXX
 SG_ VCFRONT1_brakeMotorECU2EFuseStat m4 : 3|3@1+ (1,0) [0|0] "" Vector__XXX
 SG_ VCFRONT1_bridgeEFuseState m5 : 3|3@1+ (1,0) [0|0] "" Vector__XXX
 SG_ VCFRONT1_pcsEFuseState m2 : 3|3@1+ (1,0) [0|0] "" Vector__XXX
 SG_ VCFRONT1_rightControllerEFuseSta m1 : 3|3@1+ (1,0) [0|0] "" Vector__XXX
 SG_ VCFRONT1_eFuseDebugStatusIndex M : 0|3@1+ (1,0) [0|0] "" Vector__XXX

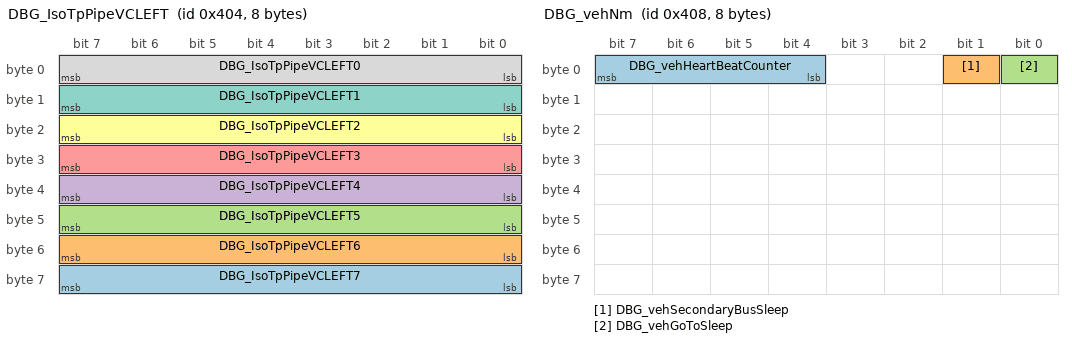
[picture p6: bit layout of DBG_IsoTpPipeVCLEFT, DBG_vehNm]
BO_ 1028 DBG_IsoTpPipeVCLEFT: 8 Vector__XXX
 SG_ DBG_IsoTpPipeVCLEFT7 : 56|8@1+ (1,0) [0|0] "" Vector__XXX
 SG_ DBG_IsoTpPipeVCLEFT6 : 48|8@1+ (1,0) [0|0] "" Vector__XXX
 SG_ DBG_IsoTpPipeVCLEFT5 : 40|8@1+ (1,0) [0|0] "" Vector__XXX
 SG_ DBG_IsoTpPipeVCLEFT4 : 32|8@1+ (1,0) [0|0] "" Vector__XXX
 SG_ DBG_IsoTpPipeVCLEFT3 : 24|8@1+ (1,0) [0|0] "" Vector__XXX
 SG_ DBG_IsoTpPipeVCLEFT2 : 16|8@1+ (1,0) [0|0] "" Vector__XXX
 SG_ DBG_IsoTpPipeVCLEFT1 : 8|8@1+ (1,0) [0|0] "" Vector__XXX
 SG_ DBG_IsoTpPipeVCLEFT0 : 0|8@1+ (1,0) [0|0] "" Vector__XXX

BO_ 1030 VCBATT1_eFuseDebugStatus: 8 Vector__XXX
 SG_ VCBATT1_EPAS1EFuseOCThreshold m1 : 48|5@1+ (1,0) [0|0] "" Vector__XXX
 SG_ VCBATT1_autopilot1EFuseOCThresho m3 : 48|5@1+ (1,0) [0|0] "" Vector__XXX
 SG_ VCBATT1_brakeMotorECU1EFuseOCThr m5 : 48|5@1+ (1,0) [0|0] "" Vector__XXX
 SG_ VCBATT1_bridgeEFuseOCThreshold m2 : 48|5@1+ (1,0) [0|0] "" Vector__XXX
 SG_ VCBATT1_leftControllerEFuseOCThr m0 : 48|5@1+ (1,0) [0|0] "" Vector__XXX
 SG_ VCBATT1_loadshedEFuseOCThreshold m4 : 48|5@1+ (1,0) [0|0] "" Vector__XXX
 SG_ VCBATT1_EPAS1EFuseHardShortThres m1 : 44|4@1+ (1,0) [0|0] "" Vector__XXX
 SG_ VCBATT1_autopilot1EFuseHardShort m3 : 44|4@1+ (1,0) [0|0] "" Vector__XXX
 SG_ VCBATT1_brakeMotorECU1EFuseHardS m5 : 44|4@1+ (1,0) [0|0] "" Vector__XXX
 SG_ VCBATT1_bridgeEFuseHardShortThre m2 : 44|4@1+ (1,0) [0|0] "" Vector__XXX
 SG_ VCBATT1_leftControllerEFuseHardS m0 : 44|4@1+ (1,0) [0|0] "" Vector__XXX
 SG_ VCBATT1_loadshedEFuseHardShortTh m4 : 44|4@1+ (1,0) [0|0] "" Vector__XXX
 SG_ VCBATT1_EPAS1EFuseManagerState m1 : 40|4@1+ (1,0) [0|0] "" Vector__XXX
 SG_ VCBATT1_autopilot1EFuseManagerSt m3 : 40|4@1+ (1,0) [0|0] "" Vector__XXX
 SG_ VCBATT1_brakeMotorECU1EFuseManag m5 : 40|4@1+ (1,0) [0|0] "" Vector__XXX
 SG_ VCBATT1_bridgeEFuseManagerState m2 : 40|4@1+ (1,0) [0|0] "" Vector__XXX
 SG_ VCBATT1_leftControllerEFuseManag m0 : 40|4@1+ (1,0) [0|0] "" Vector__XXX
 SG_ VCBATT1_loadshedEFuseManagerStat m4 : 40|4@1+ (1,0) [0|0] "" Vector__XXX
 SG_ VCBATT1_EPAS1EFuseTemperature m1 : 32|8@1+ (1,-40) [0|0] "" Vector__XXX
 SG_ VCBATT1_autopilot1EFuseTemperatu m3 : 32|8@1+ (1,-40) [0|0] "" Vector__XXX
 SG_ VCBATT1_brakeMotorECU1EFuseTempe m5 : 32|8@1+ (1,-40) [0|0] "" Vector__XXX
 SG_ VCBATT1_bridgeEFuseTemperature m2 : 32|8@1+ (1,-40) [0|0] "" Vector__XXX
 SG_ VCBATT1_leftControllerEFuseTempe m0 : 32|8@1+ (1,-40) [0|0] "" Vector__XXX
 SG_ VCBATT1_loadshedEFuseTemperature m4 : 32|8@1+ (1,-40) [0|0] "" Vector__XXX
 SG_ VCBATT1_EPAS1EFuseVoltage m1 : 24|8@1+ (0.07,0) [0|0] "" Vector__XXX
 SG_ VCBATT1_autopilot1EFuseVoltage m3 : 24|8@1+ (0.07,0) [0|0] "" Vector__XXX
 SG_ VCBATT1_brakeMotorECU1EFuseVolta m5 : 24|8@1+ (0.07,0) [0|0] "" Vector__XXX
 SG_ VCBATT1_bridgeEFuseVoltage m2 : 24|8@1+ (0.07,0) [0|0] "" Vector__XXX
 SG_ VCBATT1_leftControllerEFuseVolta m0 : 24|8@1+ (0.07,0) [0|0] "" Vector__XXX
 SG_ VCBATT1_loadshedEFuseVoltage m4 : 24|8@1+ (0.07,0) [0|0] "" Vector__XXX
 SG_ VCBATT1_sleepBypassVoltage m7 : 24|16@1+ (0.1,0) [0|0] "" Vector__XXX
 SG_ VCBATT1_EPAS1EFuseBypassDesired m1 : 23|1@1+ (1,0) [0|0] "" Vector__XXX
 SG_ VCBATT1_autopilot1EFuseBypassDes m3 : 23|1@1+ (1,0) [0|0] "" Vector__XXX
 SG_ VCBATT1_brakeMotorECU1EFuse_0000 m5 : 23|1@1+ (1,0) [0|0] "" Vector__XXX
 SG_ VCBATT1_bridgeEFuseBypassDesired m2 : 23|1@1+ (1,0) [0|0] "" Vector__XXX
 SG_ VCBATT1_leftControllerEFuse_0000 m0 : 23|1@1+ (1,0) [0|0] "" Vector__XXX
 SG_ VCBATT1_loadshedEFuseBypassDesir m4 : 23|1@1+ (1,0) [0|0] "" Vector__XXX
 SG_ VCBATT1_EPAS1EFuseBypass m1 : 22|1@1+ (1,0) [0|0] "" Vector__XXX
 SG_ VCBATT1_autopilot1EFuseBypass m3 : 22|1@1+ (1,0) [0|0] "" Vector__XXX
 SG_ VCBATT1_brakeMotorECU1EFuseBypas m5 : 22|1@1+ (1,0) [0|0] "" Vector__XXX
 SG_ VCBATT1_bridgeEFuseBypass m2 : 22|1@1+ (1,0) [0|0] "" Vector__XXX
 SG_ VCBATT1_leftControllerEFuseBypas m0 : 22|1@1+ (1,0) [0|0] "" Vector__XXX
 SG_ VCBATT1_loadshedEFuseBypass m4 : 22|1@1+ (1,0) [0|0] "" Vector__XXX
 SG_ VCBATT1_EPAS1EFuseOutputDesired m1 : 21|1@1+ (1,0) [0|0] "" Vector__XXX
 SG_ VCBATT1_autopilot1EFuseOutputDes m3 : 21|1@1+ (1,0) [0|0] "" Vector__XXX
 SG_ VCBATT1_brakeMotorECU1EFuse_0001 m5 : 21|1@1+ (1,0) [0|0] "" Vector__XXX
 SG_ VCBATT1_bridgeEFuseOutputDesired m2 : 21|1@1+ (1,0) [0|0] "" Vector__XXX
 SG_ VCBATT1_leftControllerEFuse_0001 m0 : 21|1@1+ (1,0) [0|0] "" Vector__XXX
 SG_ VCBATT1_loadshedEFuseOutputDesir m4 : 21|1@1+ (1,0) [0|0] "" Vector__XXX
 SG_ VCBATT1_EPAS1EFuseOutput m1 : 20|1@1+ (1,0) [0|0] "" Vector__XXX
 SG_ VCBATT1_autopilot1EFuseOutput m3 : 20|1@1+ (1,0) [0|0] "" Vector__XXX
 SG_ VCBATT1_brakeMotorECU1EFuseOutpu m5 : 20|1@1+ (1,0) [0|0] "" Vector__XXX
 SG_ VCBATT1_bridgeEFuseOutput m2 : 20|1@1+ (1,0) [0|0] "" Vector__XXX
 SG_ VCBATT1_leftControllerEFuseOutpu m0 : 20|1@1+ (1,0) [0|0] "" Vector__XXX
 SG_ VCBATT1_loadshedEFuseOutput m4 : 20|1@1+ (1,0) [0|0] "" Vector__XXX
 SG_ VCBATT1_mcuLogicVoltage m6 : 16|8@1+ (0.1,0) [0|0] "" Vector__XXX
 SG_ VCBATT1_EPAS1EFuseCurrent m1 : 8|12@1+ (0.05,0) [0|0] "" Vector__XXX
 SG_ VCBATT1_autopilot1EFuseCurrent m3 : 8|12@1+ (0.05,0) [0|0] "" Vector__XXX
 SG_ VCBATT1_brakeMotorECU1EFuseCurre m5 : 8|12@1+ (0.05,0) [0|0] "" Vector__XXX
 SG_ VCBATT1_bridgeEFuseCurrent m2 : 8|12@1+ (0.05,0) [0|0] "" Vector__XXX
 SG_ VCBATT1_leftControllerEFuseCurre m0 : 8|12@1+ (0.05,0) [0|0] "" Vector__XXX
 SG_ VCBATT1_loadshedEFuseCurrent m4 : 8|12@1+ (0.05,0) [0|0] "" Vector__XXX
 SG_ VCBATT1_mcuLogicCurrent m6 : 8|8@1+ (0.5,0) [0|0] "" Vector__XXX
 SG_ VCBATT1_sleepBypassCurrent m7 : 8|16@1+ (0.1,0) [0|0] "" Vector__XXX
 SG_ VCBATT1_sleepBypassFault m7 : 4|1@1+ (1,0) [0|0] "" Vector__XXX
 SG_ VCBATT1_EPAS1EFuseState m1 : 3|3@1+ (1,0) [0|0] "" Vector__XXX
 SG_ VCBATT1_autopilot1EFuseState m3 : 3|3@1+ (1,0) [0|0] "" Vector__XXX
 SG_ VCBATT1_brakeMotorECU1EFuseState m5 : 3|3@1+ (1,0) [0|0] "" Vector__XXX
 SG_ VCBATT1_bridgeEFuseState m2 : 3|3@1+ (1,0) [0|0] "" Vector__XXX
 SG_ VCBATT1_leftControllerEFuseState m0 : 3|3@1+ (1,0) [0|0] "" Vector__XXX
 SG_ VCBATT1_loadshedEFuseState m4 : 3|3@1+ (1,0) [0|0] "" Vector__XXX
 SG_ VCBATT1_sleepBypassState m7 : 3|1@1+ (1,0) [0|0] "" Vector__XXX
 SG_ VCBATT1_eFuseDebugStatusIndex M : 0|3@1+ (1,0) [0|0] "" Vector__XXX

BO_ 1031 DAS_bodyControls2: 8 Vector__XXX
 SG_ DAS_windowLockoutMode : 56|3@1+ (1,0) [0|0] "" Vector__XXX
 SG_ DAS_lightingAnimationRequest : 45|3@1+ (1,0) [0|0] "" Vector__XXX
 SG_ DAS_rearTrunkLockRequest : 43|2@1+ (1,0) [0|0] "" Vector__XXX
 SG_ DAS_doorLockRequestRR : 41|2@1+ (1,0) [0|0] "" Vector__XXX
 SG_ DAS_doorLockRequestRL : 39|2@1+ (1,0) [0|0] "" Vector__XXX
 SG_ DAS_doorLockRequestFR : 37|2@1+ (1,0) [0|0] "" Vector__XXX
 SG_ DAS_doorLockRequestFL : 35|2@1+ (1,0) [0|0] "" Vector__XXX
 SG_ DAS_frunkRequest : 33|2@1+ (1,0) [0|0] "" Vector__XXX
 SG_ DAS_windowRequestActiveRR : 32|1@1+ (1,0) [0|0] "" Vector__XXX
 SG_ DAS_windowRequestActiveRL : 31|1@1+ (1,0) [0|0] "" Vector__XXX
 SG_ DAS_windowRequestActiveFR : 30|1@1+ (1,0) [0|0] "" Vector__XXX
 SG_ DAS_windowRequestActiveFL : 29|1@1+ (1,0) [0|0] "" Vector__XXX
 SG_ DAS_windowRequest : 26|3@1+ (1,0) [0|0] "" Vector__XXX
 SG_ DAS_trunkRequest : 24|2@1+ (1,0) [0|0] "" Vector__XXX
 SG_ DAS_hornRequest : 22|2@1+ (1,0) [0|0] "" Vector__XXX
 SG_ DAS_parkingLightDimRequest : 21|1@1+ (1,0) [0|0] "" Vector__XXX
 SG_ DAS_airTankDischargeCmd : 20|1@1+ (1,0) [0|0] "" Vector__XXX
 SG_ DAS_airCleanPillarBackupCmd : 19|1@1+ (1,0) [0|0] "" Vector__XXX
 SG_ DAS_airCleanRepeaterCmd : 18|1@1+ (1,0) [0|0] "" Vector__XXX
 SG_ DAS_fluidCleanPillarBackupCmd : 17|1@1+ (1,0) [0|0] "" Vector__XXX
 SG_ DAS_fluidCleanRightRepeaterCmd : 16|1@1+ (1,0) [0|0] "" Vector__XXX
 SG_ DAS_fluidCleanLeftRepeaterCmd : 15|1@1+ (1,0) [0|0] "" Vector__XXX
 SG_ DAS_fluidCleanFasciaCmd : 14|1@1+ (1,0) [0|0] "" Vector__XXX
 SG_ DAS_narrowWipeRequest : 13|1@1+ (1,0) [0|0] "" Vector__XXX
 SG_ DAS_narrowWiperWashRequest : 12|1@1+ (1,0) [0|0] "" Vector__XXX
 SG_ DAS_bodyControls2Counter : 8|4@1+ (1,0) [0|0] "" Vector__XXX
 SG_ DAS_bodyControls2Checksum : 0|8@1+ (1,0) [0|0] "" Vector__XXX

BO_ 1032 DBG_vehNm: 8 Vector__XXX
 SG_ DBG_vehHeartBeatCounter : 4|4@1+ (1,0) [0|0] "" Vector__XXX
 SG_ DBG_vehSecondaryBusSleep : 1|1@1+ (1,0) [0|0] "" Vector__XXX
 SG_ DBG_vehGoToSleep : 0|1@1+ (1,0) [0|0] "" Vector__XXX

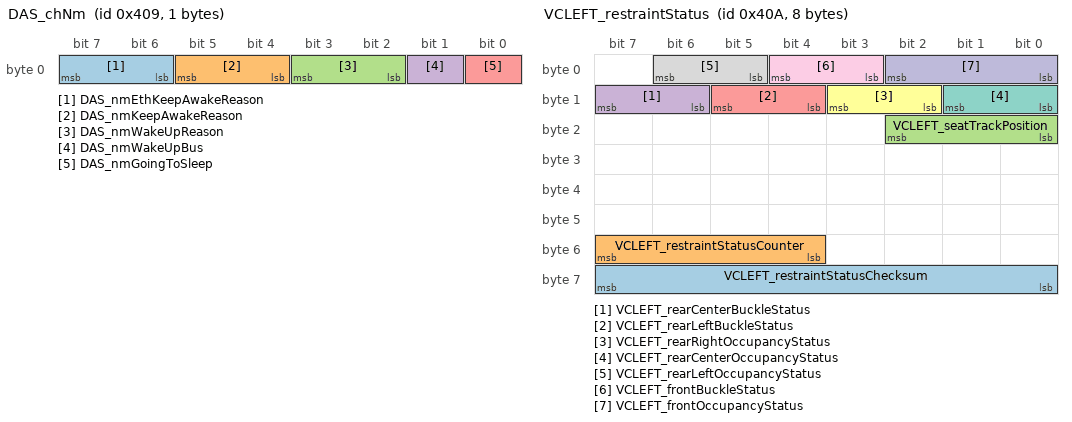
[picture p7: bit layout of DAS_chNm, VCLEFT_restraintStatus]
BO_ 1033 DAS_chNm: 1 Vector__XXX
 SG_ DAS_nmEthKeepAwakeReason : 6|2@1+ (1,0) [0|0] "" Vector__XXX
 SG_ DAS_nmKeepAwakeReason : 4|2@1+ (1,0) [0|0] "" Vector__XXX
 SG_ DAS_nmWakeUpReason : 2|2@1+ (1,0) [0|0] "" Vector__XXX
 SG_ DAS_nmWakeUpBus : 1|1@1+ (1,0) [0|0] "" Vector__XXX
 SG_ DAS_nmGoingToSleep : 0|1@1+ (1,0) [0|0] "" Vector__XXX

BO_ 1034 VCLEFT_restraintStatus: 8 Vector__XXX
 SG_ VCLEFT_restraintStatusChecksum : 56|8@1+ (1,0) [0|0] "" Vector__XXX
 SG_ VCLEFT_restraintStatusCounter : 52|4@1+ (1,0) [0|0] "" Vector__XXX
 SG_ VCLEFT_seatTrackPosition : 16|3@1+ (1,0) [0|0] "" Vector__XXX
 SG_ VCLEFT_rearCenterBuckleStatus : 14|2@1+ (1,0) [0|0] "" Vector__XXX
 SG_ VCLEFT_rearLeftBuckleStatus : 12|2@1+ (1,0) [0|0] "" Vector__XXX
 SG_ VCLEFT_rearRightOccupancyStatus : 10|2@1+ (1,0) [0|0] "" Vector__XXX
 SG_ VCLEFT_rearCenterOccupancyStatus : 8|2@1+ (1,0) [0|0] "" Vector__XXX
 SG_ VCLEFT_rearLeftOccupancyStatus : 5|2@1+ (1,0) [0|0] "" Vector__XXX
 SG_ VCLEFT_frontBuckleStatus : 3|2@1+ (1,0) [0|0] "" Vector__XXX
 SG_ VCLEFT_frontOccupancyStatus : 0|3@1+ (1,0) [0|0] "" Vector__XXX

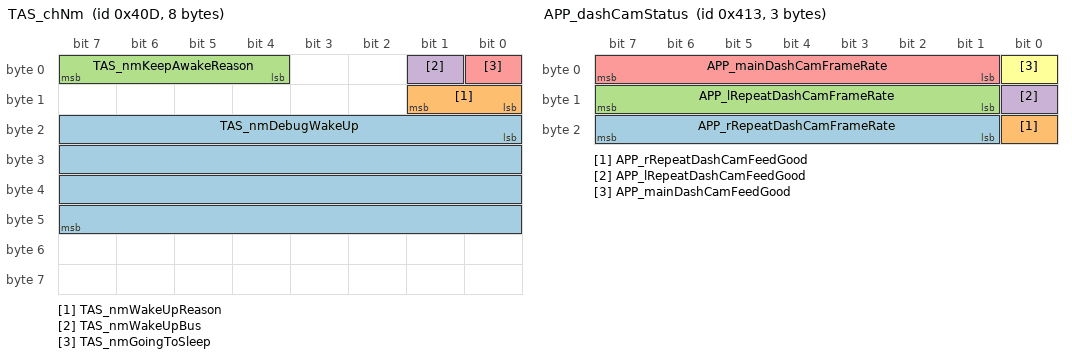
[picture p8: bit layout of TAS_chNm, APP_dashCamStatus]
BO_ 1037 TAS_chNm: 8 Vector__XXX
 SG_ TAS_nmDebugWakeUp : 16|32@1+ (1,0) [0|0] "" Vector__XXX
 SG_ TAS_nmWakeUpReason : 8|2@1+ (1,0) [0|0] "" Vector__XXX
 SG_ TAS_nmKeepAwakeReason : 4|4@1+ (1,0) [0|0] "" Vector__XXX
 SG_ TAS_nmWakeUpBus : 1|1@1+ (1,0) [0|0] "" Vector__XXX
 SG_ TAS_nmGoingToSleep : 0|1@1+ (1,0) [0|0] "" Vector__XXX

BO_ 1039 PCS2_v2xInfo2: 8 Vector__XXX
 SG_ PCS2_v2xMaxChargePowerAvailable : 16|8@1+ (0.1,0) [0|0] "" Vector__XXX
 SG_ PCS2_v2xUserPower : 0|10@1- (0.05,0) [0|0] "" Vector__XXX

BO_ 1042 BMS_xcpResponse: 8 Vector__XXX
 SG_ BMS_xcpResponse : 0|64@1+ (1,0) [0|0] "" Vector__XXX

BO_ 1043 APP_dashCamStatus: 3 Vector__XXX
 SG_ APP_rRepeatDashCamFrameRate : 17|7@1+ (1,0) [0|0] "" Vector__XXX
 SG_ APP_rRepeatDashCamFeedGood : 16|1@1+ (1,0) [0|0] "" Vector__XXX
 SG_ APP_lRepeatDashCamFrameRate : 9|7@1+ (1,0) [0|0] "" Vector__XXX
 SG_ APP_lRepeatDashCamFeedGood : 8|1@1+ (1,0) [0|0] "" Vector__XXX
 SG_ APP_mainDashCamFrameRate : 1|7@1+ (1,0) [0|0] "" Vector__XXX
 SG_ APP_mainDashCamFeedGood : 0|1@1+ (1,0) [0|0] "" Vector__XXX

BO_ 1044 GTW_chargingID: 8 Vector__XXX
 SG_ GTW_chargingIDHigh m16 : 47|24@0+ (1,0) [0|0] "" Vector__XXX
 SG_ GTW_chargingIDLow m18 : 15|56@0+ (1,0) [0|0] "" Vector__XXX
 SG_ GTW_chargingIDMid m17 : 15|56@0+ (1,0) [0|0] "" Vector__XXX
 SG_ GTW_chargingIDIndex M : 7|8@0+ (1,0) [0|0] "" Vector__XXX

BO_ 1045 APP_backupDashCamStatus: 1 Vector__XXX
 SG_ APP_backupDashCamFrameRate : 1|7@1+ (1,0) [0|0] "" Vector__XXX
 SG_ APP_backupDashCamFeedGood : 0|1@1+ (1,0) [0|0] "" Vector__XXX

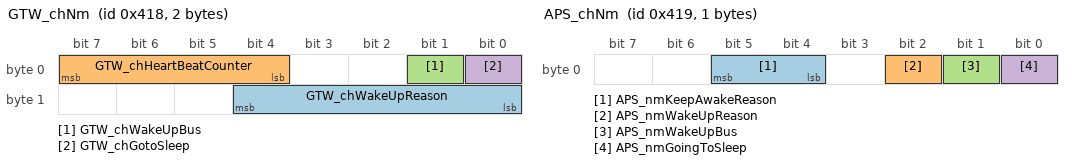
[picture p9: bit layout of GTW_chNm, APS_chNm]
BO_ 1048 GTW_chNm: 2 Vector__XXX
 SG_ GTW_chWakeUpReason : 8|5@1+ (1,0) [0|0] "" Vector__XXX
 SG_ GTW_chHeartBeatCounter : 4|4@1+ (1,0) [0|0] "" Vector__XXX
 SG_ GTW_chWakeUpBus : 1|1@1+ (1,0) [0|0] "" Vector__XXX
 SG_ GTW_chGotoSleep : 0|1@1+ (1,0) [0|0] "" Vector__XXX

BO_ 1049 APS_chNm: 1 Vector__XXX
 SG_ APS_nmKeepAwakeReason : 4|2@1+ (1,0) [0|0] "" Vector__XXX
 SG_ APS_nmWakeUpReason : 2|1@1+ (1,0) [0|0] "" Vector__XXX
 SG_ APS_nmWakeUpBus : 1|1@1+ (1,0) [0|0] "" Vector__XXX
 SG_ APS_nmGoingToSleep : 0|1@1+ (1,0) [0|0] "" Vector__XXX

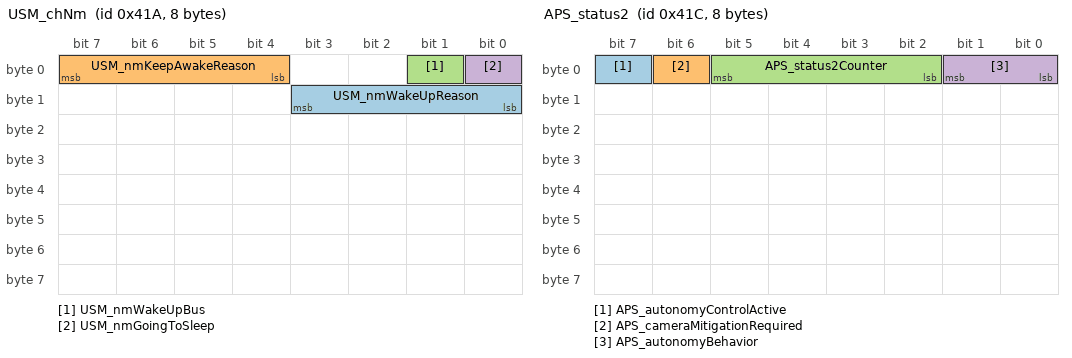
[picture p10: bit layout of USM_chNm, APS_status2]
BO_ 1050 USM_chNm: 8 Vector__XXX
 SG_ USM_nmWakeUpReason : 8|4@1+ (1,0) [0|0] "" Vector__XXX
 SG_ USM_nmKeepAwakeReason : 4|4@1+ (1,0) [0|0] "" Vector__XXX
 SG_ USM_nmWakeUpBus : 1|1@1+ (1,0) [0|0] "" Vector__XXX
 SG_ USM_nmGoingToSleep : 0|1@1+ (1,0) [0|0] "" Vector__XXX

BO_ 1052 APS_status2: 8 Vector__XXX
 SG_ APS_autonomyControlActive : 7|1@1+ (1,0) [0|0] "" Vector__XXX
 SG_ APS_cameraMitigationRequired : 6|1@1+ (1,0) [0|0] "" Vector__XXX
 SG_ APS_status2Counter : 2|4@1+ (1,0) [0|0] "" Vector__XXX
 SG_ APS_autonomyBehavior : 0|2@1+ (1,0) [0|0] "" Vector__XXX

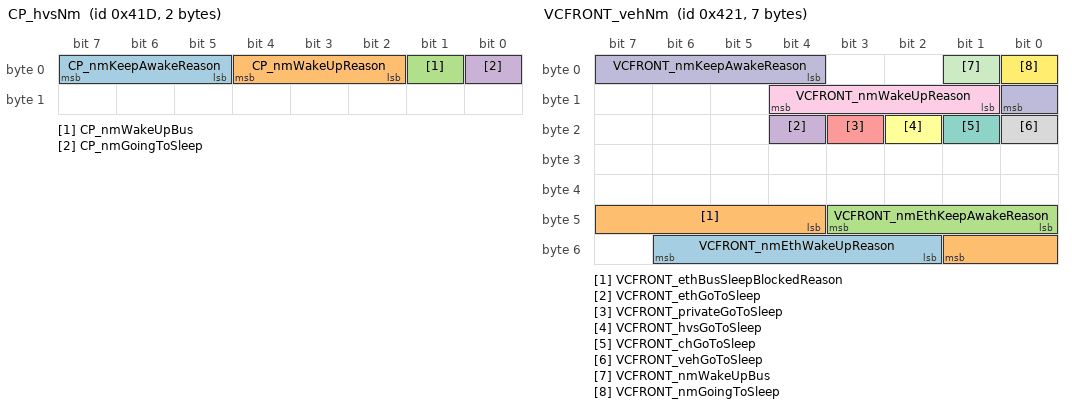
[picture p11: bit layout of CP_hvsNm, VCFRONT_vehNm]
BO_ 1053 CP_hvsNm: 2 Vector__XXX
 SG_ CP_nmKeepAwakeReason : 5|3@1+ (1,0) [0|0] "" Vector__XXX
 SG_ CP_nmWakeUpReason : 2|3@1+ (1,0) [0|0] "" Vector__XXX
 SG_ CP_nmWakeUpBus : 1|1@1+ (1,0) [0|0] "" Vector__XXX
 SG_ CP_nmGoingToSleep : 0|1@1+ (1,0) [0|0] "" Vector__XXX

BO_ 1056 APS_state: 8 Vector__XXX
 SG_ APS_stateCounter : 55|4@1+ (1,0) [0|0] "" Vector__XXX
 SG_ APS_B_faultInduced : 54|1@1+ (1,0) [0|0] "" Vector__XXX
 SG_ APS_A_faultInduced : 53|1@1+ (1,0) [0|0] "" Vector__XXX
 SG_ APS_eplannerState : 50|3@1+ (1,0) [0|0] "" Vector__XXX
 SG_ APS_B_autosteerMonitorState : 47|3@1+ (1,0) [0|0] "" Vector__XXX
 SG_ APS_A_autosteerMonitorState : 44|3@1+ (1,0) [0|0] "" Vector__XXX
 SG_ APS_B_faultState : 39|5@1+ (1,0) [0|0] "" Vector__XXX
 SG_ APS_B_resetState : 36|3@1+ (1,0) [0|0] "" Vector__XXX
 SG_ APS_B_sleepState : 32|4@1+ (1,0) [0|0] "" Vector__XXX
 SG_ APS_B_powerState : 27|5@1+ (1,0) [0|0] "" Vector__XXX
 SG_ APS_B_arbState : 24|3@1+ (1,0) [0|0] "" Vector__XXX
 SG_ APS_secondaryTurbo : 22|2@1+ (1,0) [0|0] "" Vector__XXX
 SG_ APS_A_faultState : 17|5@1+ (1,0) [0|0] "" Vector__XXX
 SG_ APS_A_resetState : 14|3@1+ (1,0) [0|0] "" Vector__XXX
 SG_ APS_A_sleepState : 10|4@1+ (1,0) [0|0] "" Vector__XXX
 SG_ APS_A_powerState : 5|5@1+ (1,0) [0|0] "" Vector__XXX
 SG_ APS_A_arbState : 2|3@1+ (1,0) [0|0] "" Vector__XXX
 SG_ APS_primaryTurbo : 0|2@1+ (1,0) [0|0] "" Vector__XXX

BO_ 1057 VCFRONT_vehNm: 7 Vector__XXX
 SG_ VCFRONT_nmEthWakeUpReason : 50|5@1+ (1,0) [0|0] "" Vector__XXX
 SG_ VCFRONT_ethBusSleepBlockedReason : 44|6@1+ (1,0) [0|0] "" Vector__XXX
 SG_ VCFRONT_nmEthKeepAwakeReason : 40|4@1+ (1,0) [0|0] "" Vector__XXX
 SG_ VCFRONT_ethGoToSleep : 20|1@1+ (1,0) [0|0] "" Vector__XXX
 SG_ VCFRONT_privateGoToSleep : 19|1@1+ (1,0) [0|0] "" Vector__XXX
 SG_ VCFRONT_hvsGoToSleep : 18|1@1+ (1,0) [0|0] "" Vector__XXX
 SG_ VCFRONT_chGoToSleep : 17|1@1+ (1,0) [0|0] "" Vector__XXX
 SG_ VCFRONT_vehGoToSleep : 16|1@1+ (1,0) [0|0] "" Vector__XXX
 SG_ VCFRONT_nmWakeUpReason : 9|4@1+ (1,0) [0|0] "" Vector__XXX
 SG_ VCFRONT_nmKeepAwakeReason : 4|5@1+ (1,0) [0|0] "" Vector__XXX
 SG_ VCFRONT_nmWakeUpBus : 1|1@1+ (1,0) [0|0] "" Vector__XXX
 SG_ VCFRONT_nmGoingToSleep : 0|1@1+ (1,0) [0|0] "" Vector__XXX

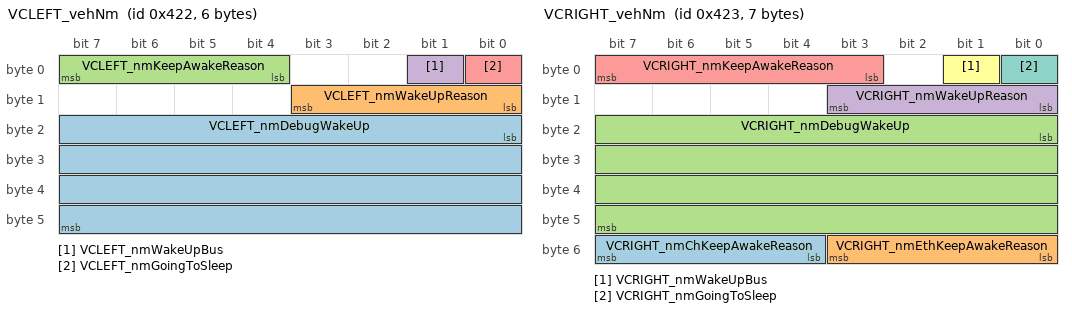
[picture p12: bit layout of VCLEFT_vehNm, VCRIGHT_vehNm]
BO_ 1058 VCLEFT_vehNm: 6 Vector__XXX
 SG_ VCLEFT_nmDebugWakeUp : 16|32@1+ (1,0) [0|0] "" Vector__XXX
 SG_ VCLEFT_nmWakeUpReason : 8|4@1+ (1,0) [0|0] "" Vector__XXX
 SG_ VCLEFT_nmKeepAwakeReason : 4|4@1+ (1,0) [0|0] "" Vector__XXX
 SG_ VCLEFT_nmWakeUpBus : 1|1@1+ (1,0) [0|0] "" Vector__XXX
 SG_ VCLEFT_nmGoingToSleep : 0|1@1+ (1,0) [0|0] "" Vector__XXX

BO_ 1059 VCRIGHT_vehNm: 7 Vector__XXX
 SG_ VCRIGHT_nmChKeepAwakeReason : 52|4@1+ (1,0) [0|0] "" Vector__XXX
 SG_ VCRIGHT_nmEthKeepAwakeReason : 48|4@1+ (1,0) [0|0] "" Vector__XXX
 SG_ VCRIGHT_nmDebugWakeUp : 16|32@1+ (1,0) [0|0] "" Vector__XXX
 SG_ VCRIGHT_nmWakeUpReason : 8|4@1+ (1,0) [0|0] "" Vector__XXX
 SG_ VCRIGHT_nmKeepAwakeReason : 3|5@1+ (1,0) [0|0] "" Vector__XXX
 SG_ VCRIGHT_nmWakeUpBus : 1|1@1+ (1,0) [0|0] "" Vector__XXX
 SG_ VCRIGHT_nmGoingToSleep : 0|1@1+ (1,0) [0|0] "" Vector__XXX

BO_ 1060 PCS_alertLog: 8 Vector__XXX
 SG_ PCS_alertSource : 61|3@1+ (1,0) [0|0] "" Vector__XXX
 SG_ PCS_a038_dcdcPwmEnableLine m38 : 60|1@1+ (1,0) [0|0] "" Vector__XXX
 SG_ PCS_a089_slowDischargeMode m89 : 60|1@1+ (1,0) [0|0] "" Vector__XXX
 SG_ PCS_a089_fastDischargeMode m89 : 59|1@1+ (1,0) [0|0] "" Vector__XXX
 SG_ PCS_a093_irrational5VNRail m93 : 59|1@1+ (1,0) [0|0] "" Vector__XXX
 SG_ PCS_a103_usingReducedMinPrecharg m103 : 59|1@1+ (1,0) [0|0] "" Vector__XXX
 SG_ PCS_a090_phCSourceMissing m90 : 58|1@1+ (1,0) [0|0] "" Vector__XXX
 SG_ PCS_a093_irrational3V3Rail m93 : 58|1@1+ (1,0) [0|0] "" Vector__XXX
 SG_ PCS_a101_retryCount m101 : 58|2@1+ (1,0) [0|0] "" Vector__XXX
 SG_ PCS_a105_L1L2Status m105 : 58|2@1+ (1,0) [0|0] "" Vector__XXX
 SG_ PCS_a090_phBSourceMissing m90 : 57|1@1+ (1,0) [0|0] "" Vector__XXX
 SG_ PCS_a093_irrational1V5Rail m93 : 57|1@1+ (1,0) [0|0] "" Vector__XXX
 SG_ PCS_a027_chgPhCNoFlowBucket m27 : 56|5@1+ (0.2,0) [0|0] "" Vector__XXX
 SG_ PCS_a053_phaseConfig m53 : 56|4@1+ (1,0) [0|0] "" Vector__XXX
 SG_ PCS_a054_phaseConfig m54 : 56|4@1+ (1,0) [0|0] "" Vector__XXX
 SG_ PCS_a073_cpType m73 : 56|2@1+ (1,0) [0|0] "" Vector__XXX
 SG_ PCS_a079_eepromErrorCount m79 : 56|5@1+ (1,0) [0|0] "" Vector__XXX
 SG_ PCS_a090_phASourceMissing m90 : 56|1@1+ (1,0) [0|0] "" Vector__XXX
 SG_ PCS_a093_irrational1V2Rail m93 : 56|1@1+ (1,0) [0|0] "" Vector__XXX
 SG_ PCS_a105_L3NStatus m105 : 56|2@1+ (1,0) [0|0] "" Vector__XXX
 SG_ PCS_a018_L1L2Locked m18 : 55|1@1+ (1,0) [0|0] "" Vector__XXX
 SG_ PCS_a051_intBusStaticRipple m51 : 55|6@1+ (1,0) [0|0] "" Vector__XXX
 SG_ PCS_a006_inputFrequency m6 : 54|7@1+ (1,40) [0|0] "" Vector__XXX
 SG_ PCS_a013_inputFrequency m13 : 54|7@1+ (1,40) [0|0] "" Vector__XXX
 SG_ PCS_a018_L3NLocked m18 : 54|1@1+ (1,0) [0|0] "" Vector__XXX
 SG_ PCS_a105_L2NStatus m105 : 54|2@1+ (1,0) [0|0] "" Vector__XXX
 SG_ PCS_a007_inputIrms m7 : 53|8@1+ (0.5,0) [0|0] "" Vector__XXX
 SG_ PCS_a018_L2NLocked m18 : 53|1@1+ (1,0) [0|0] "" Vector__XXX
 SG_ PCS_a038_dcdcPwmEnableDeasserted m38 : 53|7@1+ (1,0) [0|0] "" Vector__XXX
 SG_ PCS_a092_chgTempPhC m92 : 53|8@1- (1,40) [0|0] "" Vector__XXX
 SG_ PCS_a009_intBusV m9 : 52|8@1+ (2,0) [0|0] "" Vector__XXX
 SG_ PCS_a011_outputV m11 : 52|8@1+ (2,0) [0|0] "" Vector__XXX
 SG_ PCS_a012_transientRetryCount m12 : 52|9@1+ (0.1,0) [0|0] "" Vector__XXX
 SG_ PCS_a018_L1NLocked m18 : 52|1@1+ (1,0) [0|0] "" Vector__XXX
 SG_ PCS_a073_phaseConfig m73 : 52|4@1+ (1,0) [0|0] "" Vector__XXX
 SG_ PCS_a090_evaluatedGridConfig m90 : 52|4@1+ (1,0) [0|0] "" Vector__XXX
 SG_ PCS_a105_L1NStatus m105 : 52|2@1+ (1,0) [0|0] "" Vector__XXX
 SG_ PCS_a061_PllSourceIrrational_L1L m61 : 51|1@1+ (1,0) [0|0] "" Vector__XXX
 SG_ PCS_a091_phaseTemp m91 : 51|8@1- (1,0) [0|0] "" Vector__XXX
 SG_ PCS_a103_lvBusCurrentMax m103 : 51|8@1+ (1,0) [0|0] "" Vector__XXX
 SG_ PCS_a061_PllSourceIrrational_L3N m61 : 50|1@1+ (1,0) [0|0] "" Vector__XXX
 SG_ PCS_a089_Freq m89 : 50|9@1+ (1,0) [0|0] "" Vector__XXX
 SG_ PCS_a103_faultPresent m103 : 50|1@1+ (1,0) [0|0] "" Vector__XXX
 SG_ PCS_a010_intBusVTarget m10 : 49|9@1+ (1,0) [0|0] "" Vector__XXX
 SG_ PCS_a061_PllSourceIrrational_L2N m61 : 49|1@1+ (1,0) [0|0] "" Vector__XXX
 SG_ PCS_a069_inputFrequency m69 : 49|9@1+ (0.1,40) [0|0] "" Vector__XXX
 SG_ PCS_a070_inputFrequency m70 : 49|9@1+ (0.1,40) [0|0] "" Vector__XXX
 SG_ PCS_a101_phInputVoltage m101 : 49|9@1+ (1,0) [0|0] "" Vector__XXX
 SG_ PCS_a027_chgPhBNoFlowBucket m27 : 48|5@1+ (0.2,0) [0|0] "" Vector__XXX
 SG_ PCS_a029_phaseConfig m29 : 48|4@1+ (1,0) [0|0] "" Vector__XXX
 SG_ PCS_a048_16bitsData1 m48 : 48|8@1+ (1,0) [0|0] "" Vector__XXX
 SG_ PCS_a061_PllSourceIrrational_L1N m61 : 48|1@1+ (1,0) [0|0] "" Vector__XXX
 SG_ PCS_a071_llcFrequency m71 : 48|8@1+ (1,50) [0|0] "" Vector__XXX
 SG_ PCS_a078_ptCoolantTemp m78 : 48|8@1- (1,40) [0|0] "" Vector__XXX
 SG_ PCS_a093_powerRail1V2 m93 : 48|8@1+ (0.01,0) [0|0] "" Vector__XXX
 SG_ PCS_a100_phKwhCounterDeltaFromMa m100 : 48|13@1+ (1,0) [0|0] "" Vector__XXX
 SG_ PCS_a006_inputVToIntBusDeltaMax m6 : 47|7@1+ (1,0) [0|0] "" Vector__XXX
 SG_ PCS_a013_inputVToIntBusDeltaMax m13 : 47|7@1+ (1,0) [0|0] "" Vector__XXX
 SG_ PCS_a053_startingInputVrms m53 : 47|9@1+ (1,0) [0|0] "" Vector__XXX
 SG_ PCS_a054_startingInputVrms m54 : 47|9@1+ (1,0) [0|0] "" Vector__XXX
 SG_ PCS_a051_intBusVTarget m51 : 46|9@1+ (1,0) [0|0] "" Vector__XXX
 SG_ PCS_a001_intBusV m1 : 45|9@1+ (1,0) [0|0] "" Vector__XXX
 SG_ PCS_a032_phCFaulted m32 : 45|1@1+ (1,0) [0|0] "" Vector__XXX
 SG_ PCS_a089_PhaseShift m89 : 45|5@1+ (0.5,0) [0|0] "" Vector__XXX
 SG_ PCS_a092_chgTempPhB m92 : 45|8@1- (1,40) [0|0] "" Vector__XXX
 SG_ PCS_a007_inputVrms m7 : 44|9@1+ (1,0) [0|0] "" Vector__XXX
 SG_ PCS_a009_llcCurrent m9 : 44|8@1+ (0.1,0) [0|0] "" Vector__XXX
 SG_ PCS_a011_intBusV m11 : 44|8@1+ (2,0) [0|0] "" Vector__XXX
 SG_ PCS_a032_phBFaulted m32 : 44|1@1+ (1,0) [0|0] "" Vector__XXX
 SG_ PCS_a088_phCFrequency m88 : 44|12@1+ (0.01,40) [0|0] "" Vector__XXX
 SG_ PCS_a096_phCFrequency m96 : 44|12@1+ (0.01,40) [0|0] "" Vector__XXX
 SG_ PCS_a098_phCFrequency m98 : 44|12@1+ (0.01,40) [0|0] "" Vector__XXX
 SG_ PCS_a099_phCFrequency m99 : 44|12@1+ (0.01,40) [0|0] "" Vector__XXX
 SG_ PCS_a012_batteryV m12 : 43|9@1+ (1,0) [0|0] "" Vector__XXX
 SG_ PCS_a018_PhaseDiff_L1L2_L1N m18 : 43|9@1+ (1,-1) [0|0] "" Vector__XXX
 SG_ PCS_a032_phAFaulted m32 : 43|1@1+ (1,0) [0|0] "" Vector__XXX
 SG_ PCS_a038_dcdcLvBusCurrent_A m38 : 43|10@1- (0.78125,0) [0|0] "" Vector__XXX
 SG_ PCS_a073_inputNGVrms m73 : 43|9@1+ (1,0) [0|0] "" Vector__XXX
 SG_ PCS_a090_vRmsL1L2 m90 : 43|9@1+ (1,0) [0|0] "" Vector__XXX
 SG_ PCS_a105_vRmsL1L2 m105 : 43|9@1+ (1,0) [0|0] "" Vector__XXX
 SG_ PCS_a019_phCFaulted m19 : 42|1@1+ (1,0) [0|0] "" Vector__XXX
 SG_ PCS_a084_dcdcHvBusVDropRate m84 : 42|12@1+ (1,0) [0|0] "" Vector__XXX
 SG_ PCS_a091_phaseInputVrms m91 : 42|9@1+ (1,0) [0|0] "" Vector__XXX
 SG_ PCS_a019_phBFaulted m19 : 41|1@1+ (1,0) [0|0] "" Vector__XXX
 SG_ PCS_a103_hvPrechargeTargetV m103 : 41|9@1+ (1,0) [0|0] "" Vector__XXX
 SG_ PCS_a008_inputIrms m8 : 40|10@1+ (0.1,0) [0|0] "" Vector__XXX
 SG_ PCS_a010_intBusV m10 : 40|9@1+ (1,0) [0|0] "" Vector__XXX
 SG_ PCS_a014_phcTemperature m14 : 40|11@1- (0.1,40) [0|0] "" Vector__XXX
 SG_ PCS_a019_phAFaulted m19 : 40|1@1+ (1,0) [0|0] "" Vector__XXX
 SG_ PCS_a027_chgPhANoFlowBucket m27 : 40|5@1+ (0.2,0) [0|0] "" Vector__XXX
 SG_ PCS_a029_bmsPowerCommand m29 : 40|8@1+ (0.1,0) [0|0] "" Vector__XXX
 SG_ PCS_a043_hvPrechargeTargetV m43 : 40|12@1+ (0.146484375,0) [0|0] "" Vector__XXX
 SG_ PCS_a048_8bitsData2 m48 : 40|8@1+ (1,0) [0|0] "" Vector__XXX
 SG_ PCS_a053_acChargeCurrentLimit m53 : 40|7@1+ (1,0) [0|0] "" Vector__XXX
 SG_ PCS_a054_acChargeCurrentLimit m54 : 40|7@1+ (1,0) [0|0] "" Vector__XXX
 SG_ PCS_a061_chgInputVdcOffset_L1L2 m61 : 40|8@1+ (1,0) [0|0] "" Vector__XXX
 SG_ PCS_a067_vcfrontVcrightVoltage m67 : 40|10@1+ (0.1,0) [0|0] "" Vector__XXX
 SG_ PCS_a069_intBusV m69 : 40|9@1+ (1,0) [0|0] "" Vector__XXX
 SG_ PCS_a070_intBusV m70 : 40|9@1+ (1,0) [0|0] "" Vector__XXX
 SG_ PCS_a075_dcdcSubState m75 : 40|5@1+ (1,0) [0|0] "" Vector__XXX
 SG_ PCS_a078_dcdcTemperature m78 : 40|8@1- (1,40) [0|0] "" Vector__XXX
 SG_ PCS_a079_operationAddress m79 : 40|16@1+ (1,0) [0|0] "" Vector__XXX
 SG_ PCS_a081_faultedSubstate m81 : 40|5@1+ (1,0) [0|0] "" Vector__XXX
 SG_ PCS_a082_faultedSubstate m82 : 40|5@1+ (1,0) [0|0] "" Vector__XXX
 SG_ PCS_a086_vcfrontPTCoolantTemp m86 : 40|12@1- (0.1,0) [0|0] "" Vector__XXX
 SG_ PCS_a093_powerRail1V5 m93 : 40|8@1+ (0.01,0) [0|0] "" Vector__XXX
 SG_ PCS_a101_phMachineModelCurrent m101 : 40|9@1+ (0.1,0) [0|0] "" Vector__XXX
 SG_ PCS_a102_dcdcEnableLine m102 : 40|1@1+ (1,0) [0|0] "" Vector__XXX
 SG_ PCS_a071_inputFrequency m71 : 39|9@1+ (0.1,40) [0|0] "" Vector__XXX
 SG_ PCS_a006_inputVrms m6 : 38|9@1+ (1,0) [0|0] "" Vector__XXX
 SG_ PCS_a013_inputVrms m13 : 38|9@1+ (1,0) [0|0] "" Vector__XXX
 SG_ PCS_a044_vTankPeak_abs_V m44 : 38|10@1+ (1,0) [0|0] "" Vector__XXX
 SG_ PCS_a007_ambientTemperature m7 : 37|7@1+ (1,0) [0|0] "" Vector__XXX
 SG_ PCS_a051_intBusV m51 : 37|9@1+ (1,0) [0|0] "" Vector__XXX
 SG_ PCS_a092_chgTempPhA m92 : 37|8@1- (1,40) [0|0] "" Vector__XXX
 SG_ PCS_a001_pfcCurrentRms m1 : 36|9@1+ (0.1,0) [0|0] "" Vector__XXX
 SG_ PCS_a011_llcFrequency m11 : 36|8@1+ (1,50) [0|0] "" Vector__XXX
 SG_ PCS_a012_outOfIBandDuration m12 : 36|7@1+ (0.05,0) [0|0] "" Vector__XXX
 SG_ PCS_a089_HV_busV m89 : 36|9@1+ (0.8203125,0) [0|0] "" Vector__XXX
 SG_ PCS_a018_PhaseDiff_L1N_L3N m18 : 34|9@1+ (1,-1) [0|0] "" Vector__XXX
 SG_ PCS_a032_phCTransientRetryCount m32 : 34|9@1+ (0.1,0) [0|0] "" Vector__XXX
 SG_ PCS_a073_inputL3NVrms m73 : 34|9@1+ (1,0) [0|0] "" Vector__XXX
 SG_ PCS_a090_vRmsL3N m90 : 34|9@1+ (1,0) [0|0] "" Vector__XXX
 SG_ PCS_a091_pfcCurrentIrms m91 : 34|8@1+ (0.1,0) [0|0] "" Vector__XXX
 SG_ PCS_a100_phKwhCounter m100 : 34|13@1+ (1,0) [0|0] "" Vector__XXX
 SG_ PCS_a105_vRmsL3N m105 : 34|9@1+ (1,0) [0|0] "" Vector__XXX
 SG_ PCS_a038_dcdcHvBusV m38 : 33|10@1+ (0.5859375,0) [0|0] "" Vector__XXX
 SG_ PCS_a001_phState m1 : 32|4@1+ (1,0) [0|0] "" Vector__XXX
 SG_ PCS_a009_pfcCurrentTarget m9 : 32|12@1+ (0.01,0) [0|0] "" Vector__XXX
 SG_ PCS_a010_llcCurrent m10 : 32|8@1+ (0.1,0) [0|0] "" Vector__XXX
 SG_ PCS_a019_userPowerRequest m19 : 32|8@1+ (0.1,0) [0|0] "" Vector__XXX
 SG_ PCS_a025_cpu2StoredAppCrcLsb16 m25 : 32|16@1+ (1,0) [0|0] "" Vector__XXX
 SG_ PCS_a027_chgPhCTemp m27 : 32|8@1- (1,40) [0|0] "" Vector__XXX
 SG_ PCS_a029_chgInputPower m29 : 32|8@1+ (0.1,0) [0|0] "" Vector__XXX
 SG_ PCS_a040_dcdcLvOutputCurrent m40 : 32|13@1- (0.1,0) [0|0] "" Vector__XXX
 SG_ PCS_a048_8bitsData1 m48 : 32|8@1+ (1,0) [0|0] "" Vector__XXX
 SG_ PCS_a061_chgInputVdcOffset_L3N m61 : 32|8@1+ (1,0) [0|0] "" Vector__XXX
 SG_ PCS_a066_hvpHvLinkVoltage m66 : 32|11@1- (1,0) [0|0] "" Vector__XXX
 SG_ PCS_a068_dcdcTankVoltOffset m68 : 32|16@1- (0.001525878906,0) [0|0] "" Vector__XXX
 SG_ PCS_a078_phcTemperature m78 : 32|8@1- (1,40) [0|0] "" Vector__XXX
 SG_ PCS_a079_eepromOperationErrorCod m79 : 32|5@1+ (1,0) [0|0] "" Vector__XXX
 SG_ PCS_a084_dcdcHvBusV m84 : 32|10@1+ (0.5859375,0) [0|0] "" Vector__XXX
 SG_ PCS_a088_phBFrequency m88 : 32|12@1+ (0.01,40) [0|0] "" Vector__XXX
 SG_ PCS_a089_G m89 : 32|4@1+ (0.2,0) [0|0] "" Vector__XXX
 SG_ PCS_a096_phBFrequency m96 : 32|12@1+ (0.01,40) [0|0] "" Vector__XXX
 SG_ PCS_a098_phBFrequency m98 : 32|12@1+ (0.01,40) [0|0] "" Vector__XXX
 SG_ PCS_a099_phBFrequency m99 : 32|12@1+ (0.01,40) [0|0] "" Vector__XXX
 SG_ PCS_a103_hvBusVoltMax m103 : 32|9@1+ (1,0) [0|0] "" Vector__XXX
 SG_ PCS_a008_inputVrms m8 : 31|9@1+ (1,0) [0|0] "" Vector__XXX
 SG_ PCS_a007_phCTemperature m7 : 30|7@1+ (1,0) [0|0] "" Vector__XXX
 SG_ PCS_a069_inputVrms m69 : 30|10@1+ (0.5,0) [0|0] "" Vector__XXX
 SG_ PCS_a070_inputVrms m70 : 30|10@1+ (0.5,0) [0|0] "" Vector__XXX
 SG_ PCS_a071_intBusV m71 : 30|9@1+ (1,0) [0|0] "" Vector__XXX
 SG_ PCS_a092_pfcIrmsPhC m92 : 30|7@1+ (0.2,0) [0|0] "" Vector__XXX
 SG_ PCS_a006_intBusV m6 : 29|9@1+ (1,0) [0|0] "" Vector__XXX
 SG_ PCS_a013_intBusV m13 : 29|9@1+ (1,0) [0|0] "" Vector__XXX
 SG_ PCS_a025_bootromRequestStatusFla m25 : 29|1@1+ (1,0) [0|0] "" Vector__XXX
 SG_ PCS_a026_systemResetRegisters m26 : 29|11@1+ (1,0) [0|0] "" Vector__XXX
 SG_ PCS_a051_llcCurrent m51 : 29|8@1+ (0.1,0) [0|0] "" Vector__XXX
 SG_ PCS_a067_vcfrontPcsEFuseV m67 : 29|10@1+ (0.1,0) [0|0] "" Vector__XXX
 SG_ PCS_a102_systemResetRegisters m102 : 29|11@1+ (1,0) [0|0] "" Vector__XXX
 SG_ PCS_a011_llcCurrentTarget m11 : 28|8@1+ (0.1,0) [0|0] "" Vector__XXX
 SG_ PCS_a012_llcCurrent m12 : 28|8@1+ (0.1,0) [0|0] "" Vector__XXX
 SG_ PCS_a025_bootromRequestFlag m25 : 28|1@1+ (1,0) [0|0] "" Vector__XXX
 SG_ PCS_a044_dcdcLvBusCurrent_A m44 : 28|10@1+ (0.39100684261974583,0) [0|0] "" Vector__XXX
 SG_ PCS_a086_pcsAmbientTemperature m86 : 28|12@1- (0.1,0) [0|0] "" Vector__XXX
 SG_ PCS_a101_phMachineModelFreq m101 : 28|12@1+ (0.01,40) [0|0] "" Vector__XXX
 SG_ PCS_a014_phbTemperature m14 : 27|11@1- (0.1,40) [0|0] "" Vector__XXX
 SG_ PCS_a080_phCNVRAMStoredState m80 : 27|3@1+ (1,0) [0|0] "" Vector__XXX
 SG_ PCS_a097_phCNVRAMStoredState m97 : 27|3@1+ (1,0) [0|0] "" Vector__XXX
 SG_ PCS_a028_outputVUvThreshold m28 : 26|10@1+ (0.5,0) [0|0] "" Vector__XXX
 SG_ PCS_a043_dcdcHvBusV m43 : 26|12@1+ (0.146484375,0) [0|0] "" Vector__XXX
 SG_ PCS_a045_hvBusEstimated_R_kOhm m45 : 26|10@1+ (0.04887585532746823,0) [0|0] "" Vector__XXX
 SG_ PCS_a046_hvBusEstimated_R_kOhm m46 : 26|10@1+ (0.04887585532746823,0) [0|0] "" Vector__XXX
 SG_ PCS_a057_inputFrequency m57 : 26|9@1+ (0.1,40) [0|0] "" Vector__XXX
 SG_ PCS_a058_inputFrequency m58 : 26|12@1+ (0.01,40) [0|0] "" Vector__XXX
 SG_ PCS_a059_inputOvRmsThreshold m59 : 26|10@1+ (0.5,0) [0|0] "" Vector__XXX
 SG_ PCS_a060_inputOvPeakThreshold m60 : 26|10@1+ (0.5,0) [0|0] "" Vector__XXX
 SG_ PCS_a063_hvpHvLinkVoltage m63 : 26|11@1- (1,0) [0|0] "" Vector__XXX
 SG_ PCS_a065_inputFrequency m65 : 26|9@1+ (0.1,40) [0|0] "" Vector__XXX
 SG_ PCS_a074_dcdcHvBusV m74 : 26|12@1+ (0.146484375,0) [0|0] "" Vector__XXX
 SG_ PCS_a075_dcdcHvBusV m75 : 26|12@1+ (0.146484375,0) [0|0] "" Vector__XXX
 SG_ PCS_a081_dcdcHvBusV m81 : 26|12@1+ (0.146484375,0) [0|0] "" Vector__XXX
 SG_ PCS_a082_dcdcHvBusV m82 : 26|12@1+ (0.146484375,0) [0|0] "" Vector__XXX
 SG_ PCS_a093_powerRail3V3 m93 : 26|10@1+ (0.01,0) [0|0] "" Vector__XXX
 SG_ PCS_a095_pcsControlRequest m95 : 26|2@1+ (1,0) [0|0] "" Vector__XXX
 SG_ PCS_a018_PhaseDiff_L2N_L3N m18 : 25|9@1+ (1,-1) [0|0] "" Vector__XXX
 SG_ PCS_a032_phBTransientRetryCount m32 : 25|9@1+ (0.1,0) [0|0] "" Vector__XXX
 SG_ PCS_a038_dcdcLvBusV m38 : 25|8@1+ (0.15625,0) [0|0] "" Vector__XXX
 SG_ PCS_a053_inputIrms m53 : 25|10@1+ (0.1,0) [0|0] "" Vector__XXX
 SG_ PCS_a054_inputIrms m54 : 25|10@1+ (0.1,0) [0|0] "" Vector__XXX
 SG_ PCS_a073_inputL2NVrms m73 : 25|9@1+ (1,0) [0|0] "" Vector__XXX
 SG_ PCS_a090_vRmsL2N m90 : 25|9@1+ (1,0) [0|0] "" Vector__XXX
 SG_ PCS_a091_intBusMaxRippleLevel m91 : 25|9@1+ (0.1,0) [0|0] "" Vector__XXX
 SG_ PCS_a100_phIntBusVolt m100 : 25|9@1+ (1,0) [0|0] "" Vector__XXX
 SG_ PCS_a105_vRmsL2N m105 : 25|9@1+ (1,0) [0|0] "" Vector__XXX
 SG_ PCS_a109_inputL3NVrms m109 : 25|9@1+ (1,0) [0|0] "" Vector__XXX
 SG_ PCS_a001_llcCurrent m1 : 24|8@1+ (0.1,0) [0|0] "" Vector__XXX
 SG_ PCS_a005_outputVOvThreshold m5 : 24|8@1+ (2,0) [0|0] "" Vector__XXX
 SG_ PCS_a019_utilityPowerAvailable m19 : 24|8@1+ (0.1,0) [0|0] "" Vector__XXX
 SG_ PCS_a025_bootloaderStatus m25 : 24|4@1+ (1,0) [0|0] "" Vector__XXX
 SG_ PCS_a027_chgPhBTemp m27 : 24|8@1- (1,40) [0|0] "" Vector__XXX
 SG_ PCS_a030_canID m30 : 24|16@1+ (1,0) [0|0] "" Vector__XXX
 SG_ PCS_a040_dcdcLvVoltage m40 : 24|8@1+ (0.1,0) [0|0] "" Vector__XXX
 SG_ PCS_a047_calculatedBootloaderCrc m47 : 24|32@1+ (1,0) [0|0] "" Vector__XXX
 SG_ PCS_a048_4bitsData2 m48 : 24|4@1+ (1,0) [0|0] "" Vector__XXX
 SG_ PCS_a061_chgInputVdcOffset_L2N m61 : 24|8@1+ (1,0) [0|0] "" Vector__XXX
 SG_ PCS_a076_dcdcPwmEnableDeasserted m76 : 24|8@1+ (1,0) [0|0] "" Vector__XXX
 SG_ PCS_a078_phbTemperature m78 : 24|8@1- (1,40) [0|0] "" Vector__XXX
 SG_ PCS_a079_recordID m79 : 24|8@1+ (1,0) [0|0] "" Vector__XXX
 SG_ PCS_a080_phBNVRAMStoredState m80 : 24|3@1+ (1,0) [0|0] "" Vector__XXX
 SG_ PCS_a084_dcdcLvBusV m84 : 24|8@1+ (0.15625,0) [0|0] "" Vector__XXX
 SG_ PCS_a087_recordStatus m87 : 24|16@1+ (1,0) [0|0] "" Vector__XXX
 SG_ PCS_a089_avgSlewRate m89 : 24|8@1- (2,0) [0|0] "" Vector__XXX
 SG_ PCS_a097_phBNVRAMStoredState m97 : 24|3@1+ (1,0) [0|0] "" Vector__XXX
 SG_ PCS_a103_lvBusVoltMax m103 : 24|8@1+ (0.1,0) [0|0] "" Vector__XXX
 SG_ PCS_a007_phBTemperature m7 : 23|7@1+ (1,0) [0|0] "" Vector__XXX
 SG_ PCS_a076_dcdcEnableLine m76 : 23|1@1+ (1,0) [0|0] "" Vector__XXX
 SG_ PCS_a092_pfcIrmsPhB m92 : 23|7@1+ (0.2,0) [0|0] "" Vector__XXX
 SG_ PCS_a024_VCFRONT_LVPowerState m24 : 22|1@1+ (1,0) [0|0] "" Vector__XXX
 SG_ PCS_a024_VC_pcsManagement m24 : 21|1@1+ (1,0) [0|0] "" Vector__XXX
 SG_ PCS_a006_intBusPrechargeTarget m6 : 20|9@1+ (1,0) [0|0] "" Vector__XXX
 SG_ PCS_a008_phaseTemperature m8 : 20|11@1- (0.1,40) [0|0] "" Vector__XXX
 SG_ PCS_a009_pfcCurrentRms m9 : 20|9@1+ (0.1,0) [0|0] "" Vector__XXX
 SG_ PCS_a010_pfcCurrentRms m10 : 20|9@1+ (0.1,0) [0|0] "" Vector__XXX
 SG_ PCS_a011_llcCurrent m11 : 20|8@1+ (0.1,0) [0|0] "" Vector__XXX
 SG_ PCS_a012_llcFrequency m12 : 20|8@1+ (1,50) [0|0] "" Vector__XXX
 SG_ PCS_a013_intBusPrechargeTarget m13 : 20|9@1+ (1,0) [0|0] "" Vector__XXX
 SG_ PCS_a024_VCFRONT_vehNm m24 : 20|1@1+ (1,0) [0|0] "" Vector__XXX
 SG_ PCS_a025_bootromStatus m25 : 20|4@1+ (1,0) [0|0] "" Vector__XXX
 SG_ PCS_a038_dcdcSubState m38 : 20|5@1+ (1,0) [0|0] "" Vector__XXX
 SG_ PCS_a051_pfcCurrentRms m51 : 20|9@1+ (0.1,0) [0|0] "" Vector__XXX
 SG_ PCS_a069_inputIDelta m69 : 20|10@1+ (0.1,0) [0|0] "" Vector__XXX
 SG_ PCS_a070_inputVDelta m70 : 20|10@1+ (0.1,0) [0|0] "" Vector__XXX
 SG_ PCS_a071_inputVrms m71 : 20|10@1+ (0.5,0) [0|0] "" Vector__XXX
 SG_ PCS_a079_eepromOperationRegion m79 : 20|2@1+ (1,0) [0|0] "" Vector__XXX
 SG_ PCS_a088_phAFrequency m88 : 20|12@1+ (0.01,40) [0|0] "" Vector__XXX
 SG_ PCS_a096_phAFrequency m96 : 20|12@1+ (0.01,40) [0|0] "" Vector__XXX
 SG_ PCS_a098_phAFrequency m98 : 20|12@1+ (0.01,40) [0|0] "" Vector__XXX
 SG_ PCS_a099_phAFrequency m99 : 20|12@1+ (0.01,40) [0|0] "" Vector__XXX
 SG_ PCS_a024_VCFRONT_coolant m24 : 19|1@1+ (1,0) [0|0] "" Vector__XXX
 SG_ PCS_a080_phANVRAMStoredState m80 : 19|3@1+ (1,0) [0|0] "" Vector__XXX
 SG_ PCS_a097_phANVRAMStoredState m97 : 19|3@1+ (1,0) [0|0] "" Vector__XXX
 SG_ PCS_a016_phCVoltSrcMissingDetect m16 : 18|1@1+ (1,0) [0|0] "" Vector__XXX
 SG_ PCS_a024_VCFRONT_systemStatus m24 : 18|1@1+ (1,0) [0|0] "" Vector__XXX
 SG_ PCS_a026_NMIFlagRegisters m26 : 18|11@1+ (1,0) [0|0] "" Vector__XXX
 SG_ PCS_a044_shortTime_us m44 : 18|10@1+ (0.03128054740957967,0) [0|0] "" Vector__XXX
 SG_ PCS_a076_dcdcSubState m76 : 18|5@1+ (1,0) [0|0] "" Vector__XXX
 SG_ PCS_a080_phCDamaged m80 : 18|1@1+ (1,0) [0|0] "" Vector__XXX
 SG_ PCS_a097_phCDamaged m97 : 18|1@1+ (1,0) [0|0] "" Vector__XXX
 SG_ PCS_a102_NMIFlagRegisters m102 : 18|11@1+ (1,0) [0|0] "" Vector__XXX
 SG_ PCS_a016_phBVoltSrcMissingDetect m16 : 17|1@1+ (1,0) [0|0] "" Vector__XXX
 SG_ PCS_a020_chargeEnableCan m20 : 17|1@1+ (1,0) [0|0] "" Vector__XXX
 SG_ PCS_a022_BMS_chargeStatus m22 : 17|1@1+ (1,0) [0|0] "" Vector__XXX
 SG_ PCS_a023_CP_status m23 : 17|1@1+ (1,0) [0|0] "" Vector__XXX
 SG_ PCS_a024_VCFRONT_vehicleStatus m24 : 17|1@1+ (1,0) [0|0] "" Vector__XXX
 SG_ PCS_a026_CPU2_watchdog_alarmed m26 : 17|1@1+ (1,0) [0|0] "" Vector__XXX
 SG_ PCS_a039_SDModuleClockFault_LV m39 : 17|1@1+ (1,0) [0|0] "" Vector__XXX
 SG_ PCS_a042_dcdcEnableCan m42 : 17|1@1+ (1,0) [0|0] "" Vector__XXX
 SG_ PCS_a047_cpu2BootLoaderCrcMismat m47 : 17|1@1+ (1,0) [0|0] "" Vector__XXX
 SG_ PCS_a048_4bitsData1 m48 : 17|4@1+ (1,0) [0|0] "" Vector__XXX
 SG_ PCS_a072_task2Stopped m72 : 17|1@1+ (1,0) [0|0] "" Vector__XXX
 SG_ PCS_a080_phBDamaged m80 : 17|1@1+ (1,0) [0|0] "" Vector__XXX
 SG_ PCS_a097_phBDamaged m97 : 17|1@1+ (1,0) [0|0] "" Vector__XXX
 SG_ PCS_a001_llcFrequency m1 : 16|8@1+ (1,50) [0|0] "" Vector__XXX
 SG_ PCS_a002_phState m2 : 16|4@1+ (1,0) [0|0] "" Vector__XXX
 SG_ PCS_a003_phState m3 : 16|4@1+ (1,0) [0|0] "" Vector__XXX
 SG_ PCS_a004_phState m4 : 16|4@1+ (1,0) [0|0] "" Vector__XXX
 SG_ PCS_a005_outputV m5 : 16|8@1+ (2,0) [0|0] "" Vector__XXX
 SG_ PCS_a006_phState m6 : 16|4@1+ (1,0) [0|0] "" Vector__XXX
 SG_ PCS_a007_phATemperature m7 : 16|7@1+ (1,0) [0|0] "" Vector__XXX
 SG_ PCS_a008_phState m8 : 16|4@1+ (1,0) [0|0] "" Vector__XXX
 SG_ PCS_a009_phState m9 : 16|4@1+ (1,0) [0|0] "" Vector__XXX
 SG_ PCS_a010_phState m10 : 16|4@1+ (1,0) [0|0] "" Vector__XXX
 SG_ PCS_a011_phState m11 : 16|4@1+ (1,0) [0|0] "" Vector__XXX
 SG_ PCS_a012_phState m12 : 16|4@1+ (1,0) [0|0] "" Vector__XXX
 SG_ PCS_a013_phState m13 : 16|4@1+ (1,0) [0|0] "" Vector__XXX
 SG_ PCS_a014_phaTemperature m14 : 16|11@1- (0.1,40) [0|0] "" Vector__XXX
 SG_ PCS_a015_lvBusVoltage m15 : 16|8@1+ (0.15625,0) [0|0] "" Vector__XXX
 SG_ PCS_a016_phAVoltSrcMissingDetect m16 : 16|1@1+ (1,0) [0|0] "" Vector__XXX
 SG_ PCS_a018_PhaseDiff_L1N_L2N m18 : 16|9@1+ (1,-1) [0|0] "" Vector__XXX
 SG_ PCS_a019_pcsMaxAvailablePower m19 : 16|8@1+ (0.1,0) [0|0] "" Vector__XXX
 SG_ PCS_a020_chargeEnableLine m20 : 16|1@1+ (1,0) [0|0] "" Vector__XXX
 SG_ PCS_a021_HVP_hvsControl m21 : 16|1@1+ (1,0) [0|0] "" Vector__XXX
 SG_ PCS_a022_BMS_pcsRequest m22 : 16|1@1+ (1,0) [0|0] "" Vector__XXX
 SG_ PCS_a023_CP_chargeStatus m23 : 16|1@1+ (1,0) [0|0] "" Vector__XXX
 SG_ PCS_a024_VCFRONT_sensors m24 : 16|1@1+ (1,0) [0|0] "" Vector__XXX
 SG_ PCS_a025_cpu2ErrorCode m25 : 16|4@1+ (1,0) [0|0] "" Vector__XXX
 SG_ PCS_a026_CPU1_watchdog_alarmed m26 : 16|1@1+ (1,0) [0|0] "" Vector__XXX
 SG_ PCS_a027_chgPhATemp m27 : 16|8@1- (1,40) [0|0] "" Vector__XXX
 SG_ PCS_a028_outputV m28 : 16|10@1+ (0.5,0) [0|0] "" Vector__XXX
 SG_ PCS_a029_inputVrms m29 : 16|9@1+ (1,0) [0|0] "" Vector__XXX
 SG_ PCS_a030_canRxErrorType m30 : 16|3@1+ (1,0) [0|0] "" Vector__XXX
 SG_ PCS_a031_UI_chargeRequest m31 : 16|1@1+ (1,0) [0|0] "" Vector__XXX
 SG_ PCS_a032_phATransientRetryCount m32 : 16|9@1+ (0.1,0) [0|0] "" Vector__XXX
 SG_ PCS_a033_HV_busV m33 : 16|12@1+ (0.146484375,0) [0|0] "" Vector__XXX
 SG_ PCS_a034_HV_busV m34 : 16|12@1+ (0.146484375,0) [0|0] "" Vector__XXX
 SG_ PCS_a035_LV_busV m35 : 16|12@1+ (0.009765625,0) [0|0] "" Vector__XXX
 SG_ PCS_a036_LV_busV m36 : 16|12@1+ (0.009765625,0) [0|0] "" Vector__XXX
 SG_ PCS_a037_dcdcPwmDeassertedCount m37 : 16|8@1+ (1,0) [0|0] "" Vector__XXX
 SG_ PCS_a038_dcdcClaFaultCode m38 : 16|4@1+ (1,0) [0|0] "" Vector__XXX
 SG_ PCS_a039_SDModuleClockFault_HV m39 : 16|1@1+ (1,0) [0|0] "" Vector__XXX
 SG_ PCS_a040_dcdcLvVoltageTarget m40 : 16|8@1+ (0.1,0) [0|0] "" Vector__XXX
 SG_ PCS_a041_dcdcTemperature m41 : 16|11@1- (0.1,40) [0|0] "" Vector__XXX
 SG_ PCS_a042_dcdcEnableLine m42 : 16|1@1+ (1,0) [0|0] "" Vector__XXX
 SG_ PCS_a043_dcdcLvBusV m43 : 16|10@1+ (0.0390625,0) [0|0] "" Vector__XXX
 SG_ PCS_a044_FaultReasonCode m44 : 16|2@1+ (1,0) [0|0] "" Vector__XXX
 SG_ PCS_a045_hvBusEstimated_C_uF m45 : 16|10@1+ (7.820136852394917,0) [0|0] "" Vector__XXX
 SG_ PCS_a046_hvBusEstimated_C_uF m46 : 16|10@1+ (7.820136852394917,0) [0|0] "" Vector__XXX
 SG_ PCS_a047_cpu1BootLoaderCrcMismat m47 : 16|1@1+ (1,0) [0|0] "" Vector__XXX
 SG_ PCS_a048_assertionReason m48 : 16|1@1+ (1,0) [0|0] "" Vector__XXX
 SG_ PCS_a049_dcdcTemperature m49 : 16|11@1- (0.1,40) [0|0] "" Vector__XXX
 SG_ PCS_a051_phState m51 : 16|4@1+ (1,0) [0|0] "" Vector__XXX
 SG_ PCS_a052_inputVrms m52 : 16|9@1+ (1,0) [0|0] "" Vector__XXX
 SG_ PCS_a053_inputVrms m53 : 16|9@1+ (1,0) [0|0] "" Vector__XXX
 SG_ PCS_a054_inputVrms m54 : 16|9@1+ (1,0) [0|0] "" Vector__XXX
 SG_ PCS_a057_inputVrms m57 : 16|10@1+ (0.5,0) [0|0] "" Vector__XXX
 SG_ PCS_a058_inputVrms m58 : 16|10@1+ (0.5,0) [0|0] "" Vector__XXX
 SG_ PCS_a059_inputVrms m59 : 16|10@1+ (0.5,0) [0|0] "" Vector__XXX
 SG_ PCS_a060_inputVPeak m60 : 16|10@1+ (0.5,0) [0|0] "" Vector__XXX
 SG_ PCS_a061_chgInputVdcOffset_L1N m61 : 16|8@1+ (1,0) [0|0] "" Vector__XXX
 SG_ PCS_a062_chgInputIOffset m62 : 16|12@1- (0.01,0) [0|0] "" Vector__XXX
 SG_ PCS_a063_chgOutputV m63 : 16|10@1+ (1,0) [0|0] "" Vector__XXX
 SG_ PCS_a064_chgOutputIOffset m64 : 16|12@1- (0.01,0) [0|0] "" Vector__XXX
 SG_ PCS_a065_inputVrms m65 : 16|10@1+ (0.5,0) [0|0] "" Vector__XXX
 SG_ PCS_a066_dcdcHvBusVolt m66 : 16|14@1+ (0.1,0) [0|0] "" Vector__XXX
 SG_ PCS_a067_dcdcLvBusVolt m67 : 16|13@1+ (0.01,0) [0|0] "" Vector__XXX
 SG_ PCS_a068_dcdcTankVolt m68 : 16|16@1- (0.03051757813,0) [0|0] "" Vector__XXX
 SG_ PCS_a069_phState m69 : 16|4@1+ (1,0) [0|0] "" Vector__XXX
 SG_ PCS_a070_phState m70 : 16|4@1+ (1,0) [0|0] "" Vector__XXX
 SG_ PCS_a071_phState m71 : 16|4@1+ (1,0) [0|0] "" Vector__XXX
 SG_ PCS_a072_task1Stopped m72 : 16|1@1+ (1,0) [0|0] "" Vector__XXX
 SG_ PCS_a073_inputL1NVrms m73 : 16|9@1+ (1,0) [0|0] "" Vector__XXX
 SG_ PCS_a074_dcdcLvBusV m74 : 16|10@1+ (0.0390625,0) [0|0] "" Vector__XXX
 SG_ PCS_a075_dcdcLvBusV m75 : 16|10@1+ (0.0390625,0) [0|0] "" Vector__XXX
 SG_ PCS_a076_pcsControlRequest m76 : 16|2@1+ (1,0) [0|0] "" Vector__XXX
 SG_ PCS_a078_phaTemperature m78 : 16|8@1- (1,40) [0|0] "" Vector__XXX
 SG_ PCS_a079_eepromOperation m79 : 16|4@1+ (1,0) [0|0] "" Vector__XXX
 SG_ PCS_a080_phADamaged m80 : 16|1@1+ (1,0) [0|0] "" Vector__XXX
 SG_ PCS_a081_dcdcLvBusV m81 : 16|10@1+ (0.0390625,0) [0|0] "" Vector__XXX
 SG_ PCS_a082_dcdcLvBusV m82 : 16|10@1+ (0.0390625,0) [0|0] "" Vector__XXX
 SG_ PCS_a083_logId m83 : 16|4@1+ (1,0) [0|0] "" Vector__XXX
 SG_ PCS_a084_dcdcSubState m84 : 16|5@1+ (1,0) [0|0] "" Vector__XXX
 SG_ PCS_a085_dcdcHalfPeriodUs m85 : 16|16@1+ (0.005,0) [0|0] "" Vector__XXX
 SG_ PCS_a086_dcdcTemperature m86 : 16|12@1- (0.1,0) [0|0] "" Vector__XXX
 SG_ PCS_a087_recordID m87 : 16|8@1+ (1,0) [0|0] "" Vector__XXX
 SG_ PCS_a088_gridConfig m88 : 16|4@1+ (1,0) [0|0] "" Vector__XXX
 SG_ PCS_a089_hvSlewRate m89 : 16|8@1- (2,0) [0|0] "" Vector__XXX
 SG_ PCS_a090_vRmsL1N m90 : 16|9@1+ (1,0) [0|0] "" Vector__XXX
 SG_ PCS_a091_intBusTarget m91 : 16|9@1+ (1,0) [0|0] "" Vector__XXX
 SG_ PCS_a092_pfcIrmsPhA m92 : 16|7@1+ (0.2,0) [0|0] "" Vector__XXX
 SG_ PCS_a093_powerRail5VN m93 : 16|10@1+ (0.01,0) [0|0] "" Vector__XXX
 SG_ PCS_a094_malfunctionCode m94 : 16|2@1+ (1,0) [0|0] "" Vector__XXX
 SG_ PCS_a095_powerRail5VN m95 : 16|10@1+ (0.01,0) [0|0] "" Vector__XXX
 SG_ PCS_a096_gridConfig m96 : 16|4@1+ (1,0) [0|0] "" Vector__XXX
 SG_ PCS_a097_phADamaged m97 : 16|1@1+ (1,0) [0|0] "" Vector__XXX
 SG_ PCS_a098_gridConfig m98 : 16|4@1+ (1,0) [0|0] "" Vector__XXX
 SG_ PCS_a099_gridConfig m99 : 16|4@1+ (1,0) [0|0] "" Vector__XXX
 SG_ PCS_a100_inputVrms m100 : 16|9@1+ (1,0) [0|0] "" Vector__XXX
 SG_ PCS_a101_phPllFreq m101 : 16|12@1+ (0.01,40) [0|0] "" Vector__XXX
 SG_ PCS_a102_pcsControlRequest m102 : 16|2@1+ (1,0) [0|0] "" Vector__XXX
 SG_ PCS_a103_lvBusVoltMin m103 : 16|8@1+ (0.1,0) [0|0] "" Vector__XXX
 SG_ PCS_a104_ambientTemperature m104 : 16|11@1- (0.1,40) [0|0] "" Vector__XXX
 SG_ PCS_a105_vRmsL1N m105 : 16|9@1+ (1,0) [0|0] "" Vector__XXX
 SG_ PCS_a107_VC_pcsInterface m107 : 16|1@1+ (1,0) [0|0] "" Vector__XXX
 SG_ PCS_a108_installedInAWrongPlatfo m108 : 16|1@1+ (1,0) [0|0] "" Vector__XXX
 SG_ PCS_a109_inputL2NVrms m109 : 16|9@1+ (1,0) [0|0] "" Vector__XXX
 SG_ PCS_alertSet : 15|1@1+ (1,0) [0|0] "" Vector__XXX
 SG_ PCS_alertID M : 0|7@1+ (1,0) [0|0] "" Vector__XXX

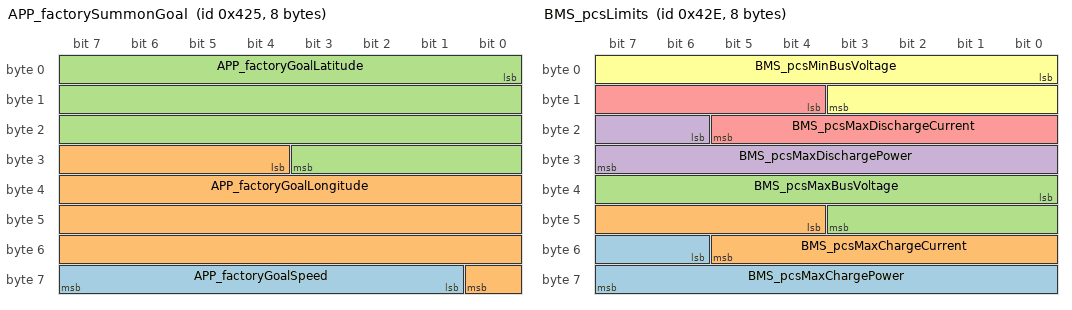
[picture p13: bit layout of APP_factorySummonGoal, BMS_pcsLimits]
BO_ 1061 APP_factorySummonGoal: 8 Vector__XXX
 SG_ APP_factoryGoalSpeed : 57|7@1+ (1,0) [0|0] "" Vector__XXX
 SG_ APP_factoryGoalLongitude : 28|29@1- (1e-06,0) [0|0] "" Vector__XXX
 SG_ APP_factoryGoalLatitude : 0|28@1- (1e-06,0) [0|0] "" Vector__XXX

BO_ 1070 BMS_pcsLimits: 8 Vector__XXX
 SG_ BMS_pcsMaxChargePower : 54|10@1+ (0.025,0) [0|0] "" Vector__XXX
 SG_ BMS_pcsMaxChargeCurrent : 44|10@1+ (0.1,0) [0|0] "" Vector__XXX
 SG_ BMS_pcsMaxBusVoltage : 32|12@1+ (0.25,0) [0|0] "" Vector__XXX
 SG_ BMS_pcsMaxDischargePower : 22|10@1+ (0.025,0) [0|0] "" Vector__XXX
 SG_ BMS_pcsMaxDischargeCurrent : 12|10@1+ (0.1,0) [0|0] "" Vector__XXX
 SG_ BMS_pcsMinBusVoltage : 0|12@1+ (0.25,0) [0|0] "" Vector__XXX

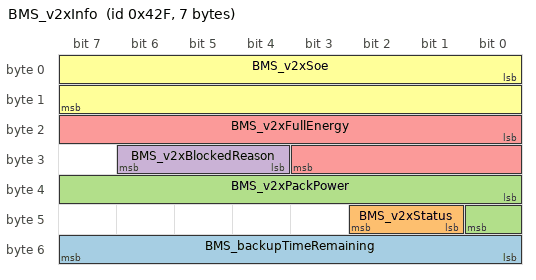
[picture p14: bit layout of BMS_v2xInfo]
BO_ 1071 BMS_v2xInfo: 7 Vector__XXX
 SG_ BMS_backupTimeRemaining : 48|8@1+ (1,0) [0|0] "" Vector__XXX
 SG_ BMS_v2xStatus : 41|2@1+ (1,0) [0|0] "" Vector__XXX
 SG_ BMS_v2xPackPower : 32|9@1+ (0.1,-25) [0|0] "" Vector__XXX
 SG_ BMS_v2xBlockedReason : 28|3@1+ (1,0) [0|0] "" Vector__XXX
 SG_ BMS_v2xFullEnergy : 16|12@1+ (0.05,0) [0|0] "" Vector__XXX
 SG_ BMS_v2xSoe : 0|16@1+ (0.002,0) [0|0] "" Vector__XXX

BO_ 1074 BMS_hvsNm: 8 Vector__XXX
 SG_ BMS_nmHeartbeatCounter : 1|4@1+ (1,0) [0|0] "" Vector__XXX
 SG_ BMS_hvsGoToSleep : 0|1@1+ (1,0) [0|0] "" Vector__XXX

CM_ BO_ 946 "ESP32-DualCAN Model3_VEH. Seen on this car: 8-byte frames; fit good (bits covered 100%, mux 96%, ranges 100%).";
VAL_ 946 BMS_dynamicEnergyBuffer 1023 "SNA" ;
VAL_ 946 BMS_idealEnergyFloor 1023 "SNA" ;
VAL_ 946 BMS_log2MuxId 0 "CAC1" 1 "CAC2" 2 "FLOOD_PORT" 3 "VSH_TEST" 4 "CHARGING" 5 "AHR_COUNTER" 6 "1HZ_TASK_STATS" 7 "10HZ_TASK_STATS" 8 "100HZ_1KHZ_TASK_STATS" 9 "CTR_RESISTANCE" 10 "POS_CTR_HEALTH_1" 11 "POS_CTR_HEALTH_2" 12 "POS_CTR_HEALTH_3" 13 "POS_CTR_HEALTH_4" 14 "NEG_CTR_HEALTH_1" 15 "NEG_CTR_HEALTH_2" 16 "NEG_CTR_HEALTH_3" 17 "NEG_CTR_HEALTH_4" 18 "HV_CHAIN_MODEL" 19 "ENERGY_RESERVE" 20 "FC_LINK_LEAKAGE_TEST" 21 "ENERGY_AND_REST_DATA" 22 "CAC3" 23 "BRICK_VOLTAGE_CHANGE" 24 "SOC_BY_OCV_CORRECTION" 25 "VSH_RES_1" 26 "VSH_RES_2" 27 "VSH_RES_3" 28 "HISTOGRAMS_0" 29 "HISTOGRAMS_1" 30 "HISTOGRAMS_2" 31 "HISTOGRAMS_3" 32 "HISTOGRAMS_4" 33 "ALPHA_1" 34 "BRICK_BALANCE_1" 35 "BRICK_BALANCE_2" 36 "BRICK_BALANCE_3" 37 "BRICK_BALANCE_4" 38 "LIFE_MODEL" 39 "BRICK_BLEED_TIMES_1" 40 "BRICK_BLEED_TIMES_2" 41 "BRICK_BLEED_TIMES_3" ;
CM_ BO_ 954 "ESP32-DualCAN Model3_CH. Not seen on this car in the logs.";
VAL_ 954 USM_matrixIndex 0 "AlertMatrix0" 1 "AlertMatrix1" 2 "AlertMatrix2" 3 "AlertMatrix3" 4 "AlertMatrix4" ;
CM_ BO_ 955 "ESP32-DualCAN Model3_VEH. Seen on this car: 3-byte frames; fit poor (bits covered 0%, mux 100%, ranges 100%).";
CM_ BO_ 956 "ESP32-DualCAN Model3_VEH. Seen on this car: 4-byte frames; fit poor (bits covered 0%, mux 100%, ranges 100%).";
CM_ BO_ 957 "ESP32-DualCAN Model3_VEH. Seen on this car: 8-byte frames; fit good (bits covered 100%, mux 100%, ranges 100%).";
VAL_ 957 VCFRONT_energyLossIndex 0 "STATUS" 1 "SINCE_LAST_DRIVE" 2 "SINCE_LAST_DRIVE2" 3 "SINCE_LAST_CHARGE" 4 "SINCE_LAST_CHARGE2" ;
CM_ BO_ 963 "ESP32-DualCAN Model3_VEH. Seen on this car: 8-byte frames; fit good (bits covered 100%, mux 100%, ranges 100%).";
VAL_ 963 VCRIGHT_rearRightOccupancySwitch 0 "SNA" 1 "OFF" 2 "ON" 3 "FAULT" ;
VAL_ 963 VCRIGHT_rearCenterBuckleSwitch 0 "SNA" 1 "OFF" 2 "ON" 3 "FAULT" ;
VAL_ 963 VCRIGHT_frontOccupancySwitch 0 "SNA" 1 "OFF" 2 "ON" 3 "FAULT" ;
VAL_ 963 VCRIGHT_frontBuckleSwitch 0 "SNA" 1 "OFF" 2 "ON" 3 "FAULT" ;
VAL_ 963 VCRIGHT_frontSeatLumbarOut 0 "SNA" 1 "OFF" 2 "ON" 3 "FAULT" ;
VAL_ 963 VCRIGHT_frontSeatLumbarIn 0 "SNA" 1 "OFF" 2 "ON" 3 "FAULT" ;
VAL_ 963 VCRIGHT_frontSeatLumbarUp 0 "SNA" 1 "OFF" 2 "ON" 3 "FAULT" ;
VAL_ 963 VCRIGHT_frontSeatLumbarDown 0 "SNA" 1 "OFF" 2 "ON" 3 "FAULT" ;
VAL_ 963 VCRIGHT_frontSeatBackrestForward 0 "SNA" 1 "OFF" 2 "ON" 3 "FAULT" ;
VAL_ 963 VCRIGHT_frontSeatBackrestBack 0 "SNA" 1 "OFF" 2 "ON" 3 "FAULT" ;
VAL_ 963 VCRIGHT_frontSeatLiftUp 0 "SNA" 1 "OFF" 2 "ON" 3 "FAULT" ;
VAL_ 963 VCRIGHT_frontSeatLiftDown 0 "SNA" 1 "OFF" 2 "ON" 3 "FAULT" ;
VAL_ 963 VCRIGHT_frontSeatTiltUp 0 "SNA" 1 "OFF" 2 "ON" 3 "FAULT" ;
VAL_ 963 VCRIGHT_frontSeatTiltDown 0 "SNA" 1 "OFF" 2 "ON" 3 "FAULT" ;
VAL_ 963 VCRIGHT_frontSeatTrackForward 0 "SNA" 1 "OFF" 2 "ON" 3 "FAULT" ;
VAL_ 963 VCRIGHT_frontSeatTrackBack 0 "SNA" 1 "OFF" 2 "ON" 3 "FAULT" ;
VAL_ 963 VCRIGHT_switchStatusIndex 0 "0" 1 "1" 2 "INVALID" ;
CM_ BO_ 971 "ESP32-DualCAN Model3_CH. Seen on this car: 5-byte frames; fit ok (bits covered 100%, mux 100%, ranges 100%).";
CM_ BO_ 972 "ESP32-DualCAN Model3_VEH. Seen on this car: 8-byte frames; fit good (bits covered 100%, mux 100%, ranges 100%).";
VAL_ 972 APS_arbState 0 "INIT" 1 "IDLE" 2 "PRIMARY" 3 "SECONDARY" 4 "FAULT" 5 "MIA" 6 "UNKNOWN" 7 "COUNT" ;
VAL_ 972 APS_heaterStateDebug 0 "OFF" 1 "ON_HEATING" 2 "ON_NOT_HEATING" 3 "FAULT_OPEN" 4 "FAULT_SHORT" 7 "SNA" ;
VAL_ 972 APS_apbPowerStateReason 0 "UI_POWER_STATE_REQUEST" 1 "AP_WDOG_UNHEALTHY" 2 "AP_NM_REASON_SET" 3 "AP_NOT_IN_PARK" 4 "GTW_GOTO_FULL_POWER" 5 "AP_POWER_REQUEST_HYSTERESIS" 6 "AP_POWER_REQUEST_OVERHEATING" 7 "AP_POWER_REQUEST_OVERRIDE" 8 "VC_POWER_REQUEST" 9 "LOADSHED_POWER_REQUEST_PENDING" ;
VAL_ 972 APS_apbPowerStateRequest 0 "NOMINAL" 1 "SENTRY" 2 "SUSPEND" 3 "SLEEP" ;
VAL_ 972 APS_appPowerStateReason 0 "UI_POWER_STATE_REQUEST" 1 "AP_WDOG_UNHEALTHY" 2 "AP_NM_REASON_SET" 3 "AP_NOT_IN_PARK" 4 "GTW_GOTO_FULL_POWER" 5 "AP_POWER_REQUEST_HYSTERESIS" 6 "AP_POWER_REQUEST_OVERHEATING" 7 "AP_POWER_REQUEST_OVERRIDE" 8 "VC_POWER_REQUEST" 9 "LOADSHED_POWER_REQUEST_PENDING" ;
VAL_ 972 APS_appPowerStateRequest 0 "NOMINAL" 1 "SENTRY" 2 "SUSPEND" 3 "SLEEP" ;
VAL_ 972 APS_locLimitReason 0 "NOMINAL_DEFAULT" 1 "NOT_IN_DRIVE" 2 "ACC_AND_AEB_UNAVAILABLE" 3 "PRIMARY_AP_NOT_HEALTHY" 4 "RADAR_NOT_HEALTHY" 5 "NO_RADAR_TARGET" 6 "LOC_MONITOR_UNAVAILABLE" 7 "LOC_LIMITS_EXTENDED" ;
VAL_ 972 APS_apbGpioState 0 "PWR_DOWN_REBOOT" 1 "DISABLED" 2 "CRITICAL" 3 "HEALTHY" ;
VAL_ 972 APS_apbStatusMonitorState 0 "STATE_UNKNOWN" 1 "STATE_PWR_OFF" 2 "STATE_INIT" 3 "STATE_NOMINAL" 4 "STATE_CRITICAL" 5 "STATE_SHUTTING_DOWN" 6 "STATE_RECOVERY" 7 "NUM_STATES" ;
VAL_ 972 APS_eacInternalState 0 "STATE_INIT" 1 "STATE_MOMENTARY" 2 "STATE_CONTINUOUS" 3 "STATE_AUTOPARK" 4 "STATE_INHIBIT" 5 "STATE_OVERRIDE" 6 "STATE_LSS" 7 "NUM_STATES" ;
VAL_ 972 APS_appGpioState 0 "PWR_DOWN_REBOOT" 1 "DISABLED" 2 "CRITICAL" 3 "HEALTHY" ;
VAL_ 972 APS_canMaster 0 "APS" 1 "APP" 2 "APB" 3 "SNA" ;
VAL_ 972 APS_vehBehaviorState 0 "STATE_UNKNOWN" 1 "STATE_APS_AVAILABLE" 2 "STATE_APS_CONTROL" 3 "STATE_APS_BRIDGE_APP" 4 "STATE_APS_BRIDGE_APB" 5 "STATE_APS_FAIL_SAFE" 6 "STATE_APS_OVERRIDE" 7 "STATE_SYSTEM_FAULT" 8 "NUM_STATES" ;
VAL_ 972 APS_appStatusMonitorState 0 "STATE_UNKNOWN" 1 "STATE_PWR_OFF" 2 "STATE_INIT" 3 "STATE_NOMINAL" 4 "STATE_CRITICAL" 5 "STATE_SHUTTING_DOWN" 6 "STATE_RECOVERY" 7 "NUM_STATES" ;
CM_ BO_ 974 "ESP32-DualCAN Model3_VEH. Not seen on this car in the logs.";
VAL_ 974 VCBATT1_matrixIndex 0 "AlertMatrix0" 1 "AlertMatrix1" 2 "AlertMatrix2" ;
CM_ BO_ 975 "ESP32-DualCAN Model3_VEH. Not seen on this car in the logs.";
VAL_ 975 VCBATT2_matrixIndex 0 "AlertMatrix0" 1 "AlertMatrix1" 2 "AlertMatrix2" ;
CM_ BO_ 977 "ESP32-DualCAN Model3_CH. Seen on this car: 8-byte frames; fit good (bits covered 100%, mux 100%, ranges 100%).";
VAL_ 977 EPAS3S_resyncStatus 0 "PENDING" 1 "COMPLETE" ;
CM_ BO_ 982 "ESP32-DualCAN Model3_VEH. Not seen on this car in the logs.";
CM_ BO_ 987 "ESP32-DualCAN Model3_VEH. Seen on this car: 8-byte frames; fit good (bits covered 100%, mux 100%, ranges 100%).";
CM_ BO_ 988 "ESP32-DualCAN Model3_CH. Seen on this car: 8-byte frames; fit weak (bits covered 0%, mux 100%, ranges 100%).";
CM_ BO_ 989 "ESP32-DualCAN Model3_VEH. Seen on this car: 8-byte frames; fit good (bits covered 100%, mux 91%, ranges 100%).";
VAL_ 989 CP_inletHeaterState 0 "DISABLED" 1 "ENABLED_HIGHTEMP" 2 "ENABLED_LOWTEMP" 3 "FAULTED" ;
VAL_ 989 CP_inlet2HarnessIdState 0 "UNKNOWN_SNA" 1 "INVALID" 2 "VALID" ;
VAL_ 989 CP_inlet1HarnessIdState 0 "UNKNOWN_SNA" 1 "INVALID" 2 "VALID" ;
VAL_ 989 CP_loggingSlowSelect 0 "0" 1 "1" 2 "2" 3 "3" 4 "4" 5 "5" ;
CM_ BO_ 992 "ESP32-DualCAN Model3_CH. Not seen on this car in the logs.";
CM_ BO_ 996 "ESP32-DualCAN Model3_VEH. Not seen on this car in the logs.";
VAL_ 996 PCS2_matrixIndex 0 "AlertMatrix0" 1 "AlertMatrix1" 2 "AlertMatrix2" ;
CM_ BO_ 1005 "ESP32-DualCAN Model3_VEH. Seen on this car: 1-byte frames; fit poor (bits covered 0%, mux 100%, ranges 100%).";
CM_ BO_ 1007 "ESP32-DualCAN Model3_CH. Not seen on this car in the logs.";
CM_ BO_ 1008 "ESP32-DualCAN Model3_CH. Not seen on this car in the logs.";
CM_ BO_ 1013 "ESP32-DualCAN Model3_VEH. Seen on this car: 8-byte frames; fit good (bits covered 100%, mux 100%, ranges 100%).";
VAL_ 1013 VCFRONT_highBeamLatchingState 0 "SNA" 1 "UNLATCHED" 2 "LATCHING" 3 "LATCHED" ;
VAL_ 1013 VCFRONT_lightingCoreState 0 "OFF" 1 "POS_PARK" 2 "DRL" 3 "DRL_PLUS_REAR_POS_PARK" 4 "LOW_BEAMS" 15 "SNA" ;
VAL_ 1013 VCFRONT_switchLightingBrightness 255 "SNA" ;
VAL_ 1013 VCFRONT_ambientLightingBrightnes 255 "SNA" ;
VAL_ 1013 VCFRONT_hazardLightRequest 0 "NONE" 1 "BUTTON" 2 "LOCK" 3 "UNLOCK" 4 "MISLOCK" 5 "CRASH" 6 "CAR_ALARM" 7 "DAS" 8 "UDS" ;
VAL_ 1013 VCFRONT_indicatorRightRequest 0 "OFF" 1 "ACTIVE_LOW" 2 "ACTIVE_HIGH" ;
VAL_ 1013 VCFRONT_indicatorLeftRequest 0 "OFF" 1 "ACTIVE_LOW" 2 "ACTIVE_HIGH" ;
CM_ BO_ 1014 "ESP32-DualCAN Model3_VEH. Seen on this car: 8-byte frames; fit good (bits covered 100%, mux 100%, ranges 100%).";
VAL_ 1014 VCFRONT_parkRightStatus 0 "OFF" 1 "ON" 2 "FAULT" 3 "SNA" ;
VAL_ 1014 VCFRONT_parkLeftStatus 0 "OFF" 1 "ON" 2 "FAULT" 3 "SNA" ;
VAL_ 1014 VCFRONT_turnSignalRightStatus 0 "OFF" 1 "ON" 2 "FAULT" 3 "SNA" ;
VAL_ 1014 VCFRONT_turnSignalLeftStatus 0 "OFF" 1 "ON" 2 "FAULT" 3 "SNA" ;
VAL_ 1014 VCFRONT_sideRepeaterRightStatus 0 "OFF" 1 "ON" 2 "FAULT" 3 "SNA" ;
VAL_ 1014 VCFRONT_sideRepeaterLeftStatus 0 "OFF" 1 "ON" 2 "FAULT" 3 "SNA" ;
VAL_ 1014 VCFRONT_sideMarkersStatus 0 "OFF" 1 "ON" 2 "FAULT" 3 "SNA" ;
VAL_ 1014 VCFRONT_fogRightStatus 0 "OFF" 1 "ON" 2 "FAULT" 3 "SNA" ;
VAL_ 1014 VCFRONT_fogLeftStatus 0 "OFF" 1 "ON" 2 "FAULT" 3 "SNA" ;
VAL_ 1014 VCFRONT_DRLRightStatus 0 "OFF" 1 "ON" 2 "FAULT" 3 "SNA" ;
VAL_ 1014 VCFRONT_DRLLeftStatus 0 "OFF" 1 "ON" 2 "FAULT" 3 "SNA" ;
VAL_ 1014 VCFRONT_highBeamRightStatus 0 "OFF" 1 "ON" 2 "FAULT" 3 "SNA" ;
VAL_ 1014 VCFRONT_highBeamLeftStatus 0 "OFF" 1 "ON" 2 "FAULT" 3 "SNA" ;
VAL_ 1014 VCFRONT_lowBeamRightStatus 0 "OFF" 1 "ON" 2 "FAULT" 3 "SNA" ;
VAL_ 1014 VCFRONT_lowBeamLeftStatus 0 "OFF" 1 "ON" 2 "FAULT" 3 "SNA" ;
CM_ BO_ 1015 "ESP32-DualCAN Model3_CH. Not seen on this car in the logs.";
CM_ BO_ 1019 "ESP32-DualCAN Model3_VEH. Not seen on this car in the logs.";
CM_ BO_ 1023 "ESP32-DualCAN Model3_VEH.";
CM_ BO_ 1024 "ESP32-DualCAN Model3_VEH. Seen on this car: 7-byte frames; fit ok (bits covered 100%, mux 100%, ranges 100%).";
CM_ BO_ 1027 "ESP32-DualCAN Model3_VEH. Not seen on this car in the logs.";
VAL_ 1027 VCFRONT1_bridgeEFuseHardShortThr 0 "20_MV" 1 "23_MV" 2 "26_4_MV" 3 "30_3_MV" 4 "34_8_MV" 5 "40_MV" 6 "45_9_MV" 7 "52_8_MV" 8 "60_6_MV" 9 "69_6_MV" 10 "80_MV" 11 "91_9_MV" 12 "105_6_MV" 13 "121_3_MV" 14 "139_3_MV" 15 "160_MV" ;
VAL_ 1027 VCFRONT1_pcsEFuseVoltage 1023 "SNA" ;
VAL_ 1027 VCFRONT1_bridgeEFuseState 0 "UNKNOWN" 1 "STANDBY" 2 "WAKEUP" 3 "CONFIGURATION" 4 "UNLOCKED" 5 "LOCKED" 6 "SELF_TEST_PREP" 7 "SELF_TEST" ;
VAL_ 1027 VCFRONT1_eFuseDebugStatusIndex 0 "VCRIGHT" 1 "VCLEFT" 2 "PCS" 3 "IBOOSTER" 4 "EPAS3P" 5 "EPAS3S" 6 "ESP_MOTOR" 7 "ESP_VALVE" 8 "AUTOPILOT_1" 9 "AUTOPILOT_2" 10 "SLEEP_BYPASS" 11 "UI" 12 "HEADLAMPS" 13 "VBAT_FUSED_HIGH_CURRENT" 14 "PUMPS" 15 "RAILS_A_B" 16 "MISC_RAILS" 17 "LV_BATTERY_DEBUG" 18 "INVALID" ;
CM_ BO_ 1028 "ESP32-DualCAN Model3_VEH. Not seen on this car in the logs.";
CM_ BO_ 1030 "ESP32-DualCAN Model3_VEH. Not seen on this car in the logs.";
VAL_ 1030 VCBATT1_bridgeEFuseHardShortThre 0 "20_MV" 1 "23_MV" 2 "26_4_MV" 3 "30_3_MV" 4 "34_8_MV" 5 "40_MV" 6 "45_9_MV" 7 "52_8_MV" 8 "60_6_MV" 9 "69_6_MV" 10 "80_MV" 11 "91_9_MV" 12 "105_6_MV" 13 "121_3_MV" 14 "139_3_MV" 15 "160_MV" ;
VAL_ 1030 VCBATT1_bridgeEFuseState 0 "UNKNOWN" 1 "STANDBY" 2 "WAKEUP" 3 "CONFIGURATION" 4 "UNLOCKED" 5 "LOCKED" 6 "SELF_TEST_PREP" 7 "SELF_TEST" ;
VAL_ 1030 VCBATT1_eFuseDebugStatusIndex 0 "VCRIGHT" 1 "VCLEFT" 2 "PCS" 3 "IBOOSTER" 4 "EPAS3P" 5 "EPAS3S" 6 "ESP_MOTOR" 7 "ESP_VALVE" 8 "AUTOPILOT_1" 9 "AUTOPILOT_2" 10 "SLEEP_BYPASS" 11 "UI" 12 "HEADLAMPS" 13 "VBAT_FUSED_HIGH_CURRENT" 14 "PUMPS" 15 "RAILS_A_B" 16 "MISC_RAILS" 17 "LV_BATTERY_DEBUG" 18 "INVALID" ;
CM_ BO_ 1031 "ESP32-DualCAN Model3_VEH. Seen on this car: 8-byte frames; fit good (bits covered 100%, mux 100%, ranges 100%, checksum 100%).";
VAL_ 1031 DAS_frunkRequest 0 "NONE" 1 "MOVE" 2 "STOP" 3 "SNA" ;
VAL_ 1031 DAS_windowRequest 0 "IDLE" 1 "GOTO_PERCENT" 2 "GOTO_VENT" 3 "GOTO_CLOSED" 4 "GOTO_OPEN" ;
VAL_ 1031 DAS_trunkRequest 0 "NONE" 1 "MOVE" 2 "STOP" 3 "SNA" ;
CM_ BO_ 1032 "ESP32-DualCAN Model3_VEH. Not seen on this car in the logs.";
CM_ BO_ 1033 "ESP32-DualCAN Model3_VEH. Seen on this car: 1-byte frames; fit ok (bits covered 100%, mux 100%, ranges 100%).";
VAL_ 1033 DAS_nmKeepAwakeReason 0 "NONE_SNA" 1 "CTRS_CLOSED" 2 "CRITICAL_ALERT" 3 "FC_CTR_CLEANING" 4 "HVP_ACTIVE" 5 "BMS_ACTIVE" 6 "CP_ACTIVE" ;
VAL_ 1033 DAS_nmWakeUpReason 0 "NONE" 1 "CAN_VEH" 2 "CAN_HVS" 3 "WANTTOCHARGE" 4 "CRITICALALERT" 5 "WANTTOWARM" ;
CM_ BO_ 1034 "ESP32-DualCAN Model3_VEH. Seen on this car: 8-byte frames; fit good (bits covered 100%, mux 100%, ranges 100%, checksum 100%).";
VAL_ 1034 VCLEFT_seatTrackPosition 0 "FORWARD" 1 "REARWARD" 2 "NOT_CONFIGURED" 3 "FAULTED" 7 "SNA" ;
VAL_ 1034 VCLEFT_rearCenterBuckleStatus 0 "UNLATCHED" 1 "LATCHED" 2 "FAULTED" 3 "SNA" ;
VAL_ 1034 VCLEFT_rearLeftBuckleStatus 0 "UNLATCHED" 1 "LATCHED" 2 "FAULTED" 3 "SNA" ;
VAL_ 1034 VCLEFT_rearRightOccupancyStatus 0 "UNOCCUPIED" 1 "OCCUPIED" 2 "OCCUPANCY_FAULTED" 3 "OCCUPANCY_SNA" ;
VAL_ 1034 VCLEFT_rearCenterOccupancyStatus 0 "UNOCCUPIED" 1 "OCCUPIED" 2 "OCCUPANCY_FAULTED" 3 "OCCUPANCY_SNA" ;
VAL_ 1034 VCLEFT_rearLeftOccupancyStatus 0 "UNOCCUPIED" 1 "OCCUPIED" 2 "OCCUPANCY_FAULTED" 3 "OCCUPANCY_SNA" ;
VAL_ 1034 VCLEFT_frontBuckleStatus 0 "UNLATCHED" 1 "LATCHED" 2 "FAULTED" 3 "SNA" ;
VAL_ 1034 VCLEFT_frontOccupancyStatus 0 "UNOCCUPIED" 1 "OCCUPIED" 2 "OCCUPANCY_FAULTED" 3 "NOT_CONFIGURED" 7 "OCCUPANCY_SNA" ;
CM_ BO_ 1037 "ESP32-DualCAN Model3_VEH. Not seen on this car in the logs.";
VAL_ 1037 TAS_nmDebugWakeUp 2147483648 "31" 1073741824 "30" 536870912 "29" 268435456 "28" 134217728 "27" 67108864 "26" 33554432 "25" 16777216 "24" 0 "NONE" 256 "8" 512 "9" 1024 "10" 2048 "11" 4096 "12" 8192 "13" 16384 "14" 32768 "15" 1 "0" 65536 "16" 2 "1" 131072 "17" 4 "2" 262144 "18" 8 "3" 524288 "19" 16 "4" 1048576 "20" 32 "5" 2097152 "21" 64 "6" 4194304 "22" 128 "7" 8388608 "23" ;
VAL_ 1037 TAS_nmWakeUpReason 0 "NONE" 1 "CAN_VEH" 2 "CAN_HVS" 3 "WANTTOCHARGE" 4 "CRITICALALERT" 5 "WANTTOWARM" ;
VAL_ 1037 TAS_nmKeepAwakeReason 0 "NONE_SNA" 1 "CTRS_CLOSED" 2 "CRITICAL_ALERT" 3 "FC_CTR_CLEANING" 4 "HVP_ACTIVE" 5 "BMS_ACTIVE" 6 "CP_ACTIVE" ;
CM_ BO_ 1039 "ESP32-DualCAN Model3_VEH. Not seen on this car in the logs.";
CM_ BO_ 1042 "ESP32-DualCAN Model3_VEH. Not seen on this car in the logs.";
CM_ BO_ 1043 "ESP32-DualCAN Model3_CH. Seen on this car: 3-byte frames; fit ok (bits covered 100%, mux 100%, ranges 100%).";
CM_ BO_ 1044 "ESP32-DualCAN Model3_VEH. Seen on this car: 8-byte frames; fit ok (bits covered 100%, mux 100%, ranges 100%).";
CM_ BO_ 1045 "ESP32-DualCAN Model3_CH. Seen on this car: 1-byte frames; fit ok (bits covered 100%, mux 100%, ranges 100%).";
CM_ BO_ 1048 "ESP32-DualCAN Model3_CH. Seen on this car: 2-byte frames; fit ok (bits covered 100%, mux 100%, ranges 100%).";
CM_ BO_ 1049 "ESP32-DualCAN Model3_VEH. Seen on this car: 1-byte frames; fit ok (bits covered 100%, mux 100%, ranges 100%).";
VAL_ 1049 APS_nmKeepAwakeReason 0 "NONE_SNA" 1 "CTRS_CLOSED" 2 "CRITICAL_ALERT" 3 "FC_CTR_CLEANING" 4 "HVP_ACTIVE" 5 "BMS_ACTIVE" 6 "CP_ACTIVE" ;
VAL_ 1049 APS_nmWakeUpReason 0 "NONE" 1 "CAN_VEH" 2 "CAN_HVS" 3 "WANTTOCHARGE" 4 "CRITICALALERT" 5 "WANTTOWARM" ;
CM_ BO_ 1050 "ESP32-DualCAN Model3_CH. Not seen on this car in the logs.";
VAL_ 1050 USM_nmWakeUpReason 0 "NONE" 1 "CAN_VEH" 2 "CAN_HVS" 3 "WANTTOCHARGE" 4 "CRITICALALERT" 5 "WANTTOWARM" ;
VAL_ 1050 USM_nmKeepAwakeReason 0 "NONE_SNA" 1 "CTRS_CLOSED" 2 "CRITICAL_ALERT" 3 "FC_CTR_CLEANING" 4 "HVP_ACTIVE" 5 "BMS_ACTIVE" 6 "CP_ACTIVE" ;
CM_ BO_ 1052 "ESP32-DualCAN Model3_CH. Not seen on this car in the logs.";
CM_ BO_ 1053 "ESP32-DualCAN Model3_VEH. Seen on this car: 2-byte frames; fit ok (bits covered 100%, mux 100%, ranges 100%).";
VAL_ 1053 CP_nmKeepAwakeReason 0 "NONE_SNA" 1 "CTRS_CLOSED" 2 "CRITICAL_ALERT" 3 "FC_CTR_CLEANING" 4 "HVP_ACTIVE" 5 "BMS_ACTIVE" 6 "CP_ACTIVE" ;
VAL_ 1053 CP_nmWakeUpReason 0 "NONE" 1 "CAN_VEH" 2 "CAN_HVS" 3 "WANTTOCHARGE" 4 "CRITICALALERT" 5 "WANTTOWARM" ;
CM_ BO_ 1056 "ESP32-DualCAN Model3_VEH. Seen on this car: 8-byte frames; fit good (bits covered 100%, mux 100%, ranges 100%).";
VAL_ 1056 APS_B_faultState 0 "NONE" 1 "GIC" 2 "MIF_ECC_CORRECTED" 3 "MIF_ECC_UNCORRECTED" 4 "MIF0_DFI_ALERT" 5 "MIF1_DFI_ALERT" 6 "MIF2_DFI_ALERT" 7 "MIF3_DFI_ALERT" 8 "MIF4_DFI_ALERT" 9 "MIF5_DFI_ALERT" 10 "MIF6_DFI_ALERT" 11 "MIF7_DFI_ALERT" 12 "MIF_ECC_AP" 13 "DROOP_CPUCL0" 14 "DROOP_CPUCL1" 15 "DROOP_CPUCL2" 16 "DROOP_GPU" 17 "DROOP_TRIP" 18 "CPU_FAULT" 19 "WDT" 20 "TRIP0_FAULT" 21 "TRIP1_FAULT" 22 "SOFTWARE_FAULT" 23 "SCS" 24 "UNEXPECTED" 25 "MIA" 26 "UNKNOWN" 27 "COUNT" ;
VAL_ 1056 APS_B_resetState 0 "NOT_RESETTING" 1 "RESETTING" 2 "FAULT" 3 "MIA" 4 "UNKNOWN" 5 "COUNT" ;
VAL_ 1056 APS_B_sleepState 0 "IDLE" 1 "WAIT_FOR_BUS_SILENCE" 2 "READY" 3 "GOING_TO_SLEEP" 4 "SLEEPING" 5 "ABORT" 6 "FAULT" 7 "MIA" 8 "UNKNOWN" 9 "COUNT" ;
VAL_ 1056 APS_B_powerState 0 "IDLE" 1 "AP_ON_PREPARE" 2 "AP_ON_PREPARE_WAIT_FOR_ACK" 3 "AP_ON_PREPARE_WAIT_FOR_RESPONSE" 4 "AP_ON_READY" 5 "AP_ON_READY_WAIT_FOR_ACK" 6 "AP_ON_READY_WAIT_FOR_RESPONSE" 7 "AP_BOOTING" 8 "AP_IN_COREBOOT" 9 "AP_ON" 10 "AP_WAIT_FOR_SHUTDOWN" 11 "AP_OFF_PREPARE" 12 "AP_OFF_READY" 13 "AP_OFF_READY_WAIT_FOR_ACK" 14 "AP_OFF_READY_WAIT_FOR_RESPONSE" 15 "AP_OFF_ABORT" 16 "AP_OFF_ABORT_WAIT_FOR_ACK" 17 "AP_SUSPENDED" 18 "SOC_OFF_READY" 19 "SOC_OFF" 20 "SOC_OFF_ABORT" 21 "FAULT" 22 "MIA" 23 "UNKNOWN" 24 "COUNT" ;
VAL_ 1056 APS_B_arbState 0 "INIT" 1 "IDLE" 2 "PRIMARY" 3 "SECONDARY" 4 "FAULT" 5 "MIA" 6 "UNKNOWN" 7 "COUNT" ;
VAL_ 1056 APS_secondaryTurbo 0 "A" 1 "B" 2 "UNKNOWN" ;
VAL_ 1056 APS_A_faultState 0 "NONE" 1 "GIC" 2 "MIF_ECC_CORRECTED" 3 "MIF_ECC_UNCORRECTED" 4 "MIF0_DFI_ALERT" 5 "MIF1_DFI_ALERT" 6 "MIF2_DFI_ALERT" 7 "MIF3_DFI_ALERT" 8 "MIF4_DFI_ALERT" 9 "MIF5_DFI_ALERT" 10 "MIF6_DFI_ALERT" 11 "MIF7_DFI_ALERT" 12 "MIF_ECC_AP" 13 "DROOP_CPUCL0" 14 "DROOP_CPUCL1" 15 "DROOP_CPUCL2" 16 "DROOP_GPU" 17 "DROOP_TRIP" 18 "CPU_FAULT" 19 "WDT" 20 "TRIP0_FAULT" 21 "TRIP1_FAULT" 22 "SOFTWARE_FAULT" 23 "SCS" 24 "UNEXPECTED" 25 "MIA" 26 "UNKNOWN" 27 "COUNT" ;
VAL_ 1056 APS_A_resetState 0 "NOT_RESETTING" 1 "RESETTING" 2 "FAULT" 3 "MIA" 4 "UNKNOWN" 5 "COUNT" ;
VAL_ 1056 APS_A_sleepState 0 "IDLE" 1 "WAIT_FOR_BUS_SILENCE" 2 "READY" 3 "GOING_TO_SLEEP" 4 "SLEEPING" 5 "ABORT" 6 "FAULT" 7 "MIA" 8 "UNKNOWN" 9 "COUNT" ;
VAL_ 1056 APS_A_powerState 0 "IDLE" 1 "AP_ON_PREPARE" 2 "AP_ON_PREPARE_WAIT_FOR_ACK" 3 "AP_ON_PREPARE_WAIT_FOR_RESPONSE" 4 "AP_ON_READY" 5 "AP_ON_READY_WAIT_FOR_ACK" 6 "AP_ON_READY_WAIT_FOR_RESPONSE" 7 "AP_BOOTING" 8 "AP_IN_COREBOOT" 9 "AP_ON" 10 "AP_WAIT_FOR_SHUTDOWN" 11 "AP_OFF_PREPARE" 12 "AP_OFF_READY" 13 "AP_OFF_READY_WAIT_FOR_ACK" 14 "AP_OFF_READY_WAIT_FOR_RESPONSE" 15 "AP_OFF_ABORT" 16 "AP_OFF_ABORT_WAIT_FOR_ACK" 17 "AP_SUSPENDED" 18 "SOC_OFF_READY" 19 "SOC_OFF" 20 "SOC_OFF_ABORT" 21 "FAULT" 22 "MIA" 23 "UNKNOWN" 24 "COUNT" ;
VAL_ 1056 APS_A_arbState 0 "INIT" 1 "IDLE" 2 "PRIMARY" 3 "SECONDARY" 4 "FAULT" 5 "MIA" 6 "UNKNOWN" 7 "COUNT" ;
VAL_ 1056 APS_primaryTurbo 0 "A" 1 "B" 2 "UNKNOWN" ;
CM_ BO_ 1057 "ESP32-DualCAN Model3_VEH. Seen on this car: 7-byte frames; fit ok (bits covered 100%, mux 100%, ranges 100%).";
VAL_ 1057 VCFRONT_nmWakeUpReason 0 "NONE" 1 "CAN_VEH" 2 "CAN_HVS" 3 "WANTTOCHARGE" 4 "CRITICALALERT" 5 "WANTTOWARM" ;
VAL_ 1057 VCFRONT_nmKeepAwakeReason 0 "NONE_SNA" 1 "CTRS_CLOSED" 2 "CRITICAL_ALERT" 3 "FC_CTR_CLEANING" 4 "HVP_ACTIVE" 5 "BMS_ACTIVE" 6 "CP_ACTIVE" ;
CM_ BO_ 1058 "ESP32-DualCAN Model3_VEH. Seen on this car: 6-byte frames; fit ok (bits covered 100%, mux 100%, ranges 100%).";
VAL_ 1058 VCLEFT_nmDebugWakeUp 2147483648 "31" 1073741824 "30" 536870912 "29" 268435456 "28" 134217728 "27" 67108864 "26" 33554432 "25" 16777216 "24" 0 "NONE" 256 "8" 512 "9" 1024 "10" 2048 "11" 4096 "12" 8192 "13" 16384 "14" 32768 "15" 1 "0" 65536 "16" 2 "1" 131072 "17" 4 "2" 262144 "18" 8 "3" 524288 "19" 16 "4" 1048576 "20" 32 "5" 2097152 "21" 64 "6" 4194304 "22" 128 "7" 8388608 "23" ;
VAL_ 1058 VCLEFT_nmWakeUpReason 0 "NONE" 1 "CAN_VEH" 2 "CAN_HVS" 3 "WANTTOCHARGE" 4 "CRITICALALERT" 5 "WANTTOWARM" ;
VAL_ 1058 VCLEFT_nmKeepAwakeReason 0 "NONE_SNA" 1 "CTRS_CLOSED" 2 "CRITICAL_ALERT" 3 "FC_CTR_CLEANING" 4 "HVP_ACTIVE" 5 "BMS_ACTIVE" 6 "CP_ACTIVE" ;
CM_ BO_ 1059 "ESP32-DualCAN Model3_VEH. Seen on this car: 7-byte frames; fit ok (bits covered 100%, mux 100%, ranges 100%).";
VAL_ 1059 VCRIGHT_nmDebugWakeUp 0 "NONE" 1 "0" 2 "1" 4 "2" 8 "3" 16 "4" 32 "5" 64 "6" 128 "7" 256 "8" 512 "9" 1024 "10" 2048 "11" 4096 "12" 8192 "13" 16384 "14" 32768 "15" 65536 "16" 131072 "17" 262144 "18" 524288 "19" 1048576 "20" 2097152 "21" 4194304 "22" 8388608 "23" 16777216 "24" 33554432 "25" 67108864 "26" 134217728 "27" 268435456 "28" 536870912 "29" 1073741824 "30" 2147483648 "31" ;
VAL_ 1059 VCRIGHT_nmWakeUpReason 0 "NONE" 1 "ECU_SPECIFIC" 2 "SWITCH_INPUT" 3 "RESET" 4 "DOOR_LATCH" 5 "INTERIOR_HANDLE" 6 "EXTERIOR_HANDLE" 7 "LIN_RX" 8 "TRUNK_SWITCH" 9 "TRUNK_LATCH" 10 "CABIN_HOT" 11 "POWER_ON_RESET" 15 "UNKNOWN" ;
VAL_ 1059 VCRIGHT_nmKeepAwakeReason 0 "NONE_SNA" 1 "EPB_STATE_NOT_SAVED" 2 "EPB_NOT_SECURE" 3 "HVAC_CABIN_PURGE" 4 "HVAC_PRECONDITIONING" 5 "CLOSURE_LATCH" 6 "EPB_SUMMON_ACTIVE" 7 "HANDLE" 8 "SEAT" 9 "TRUNK_LIGHT" 10 "UDS_ACTIVE" 11 "HVAC_EVAP_DRYING" 12 "TRUNK_SWITCH" 14 "OTHER" 15 "MULTIPLE" ;
CM_ BO_ 1060 "ESP32-DualCAN Model3_VEH. Not seen on this car in the logs.";
VAL_ 1060 PCS_a053_acChargeCurrentLimit 127 "SNA" ;
VAL_ 1060 PCS_a054_acChargeCurrentLimit 127 "SNA" ;
VAL_ 1060 PCS_a075_dcdcSubState 0 "PWR_UP_INIT" 1 "STANDBY" 2 "12V_SUPPORT_ACTIVE" 3 "FAST_DIS_HVBUS" 4 "SLOW_DIS_HVBUS" 5 "PCHG_FAST_DIS_HVBUS" 6 "PCHG_SLOW_DIS_HVBUS" 7 "PCHG_DWELL_CHARGE" 8 "PCHG_DWELL_WAIT" 9 "PCHG_DI_RECOVERY_WAIT" 10 "PCHG_ACTIVE" 11 "PCHG_FLT_FAST_DIS_HVBUS" 12 "SHUTDOWN" 13 "12V_SUPPORT_FAULTED" 14 "DIS_HVBUS_FAULTED" 15 "PCHG_FAULTED" 16 "CLEAR_FAULTS" 17 "FAULTED" 18 "NUM" ;
VAL_ 1060 PCS_a027_chgPhCTemp 4294966273 "SNA" ;
VAL_ 1060 PCS_a095_pcsControlRequest 0 "SHUTDOWN" 1 "SUPPORT" 2 "PRECHARGE" 3 "DISCHARGE" ;
VAL_ 1060 PCS_a027_chgPhBTemp 4294966273 "SNA" ;
VAL_ 1060 PCS_a038_dcdcSubState 0 "PWR_UP_INIT" 1 "STANDBY" 2 "12V_SUPPORT_ACTIVE" 3 "FAST_DIS_HVBUS" 4 "SLOW_DIS_HVBUS" 5 "PCHG_FAST_DIS_HVBUS" 6 "PCHG_SLOW_DIS_HVBUS" 7 "PCHG_DWELL_CHARGE" 8 "PCHG_DWELL_WAIT" 9 "PCHG_DI_RECOVERY_WAIT" 10 "PCHG_ACTIVE" 11 "PCHG_FLT_FAST_DIS_HVBUS" 12 "SHUTDOWN" 13 "12V_SUPPORT_FAULTED" 14 "DIS_HVBUS_FAULTED" 15 "PCHG_FAULTED" 16 "CLEAR_FAULTS" 17 "FAULTED" 18 "NUM" ;
VAL_ 1060 PCS_a024_VCFRONT_systemStatus 0 "UNKNOWN" 1 "RELEASED" 2 "PARKED" 3 "DYNAMIC" 4 "PARKING" 5 "RELEASING" 6 "FAULT" 7 "FAULT_SECURE" 8 "MISMATCH" ;
VAL_ 1060 PCS_a076_dcdcSubState 0 "PWR_UP_INIT" 1 "STANDBY" 2 "12V_SUPPORT_ACTIVE" 3 "FAST_DIS_HVBUS" 4 "SLOW_DIS_HVBUS" 5 "PCHG_FAST_DIS_HVBUS" 6 "PCHG_SLOW_DIS_HVBUS" 7 "PCHG_DWELL_CHARGE" 8 "PCHG_DWELL_WAIT" 9 "PCHG_DI_RECOVERY_WAIT" 10 "PCHG_ACTIVE" 11 "PCHG_FLT_FAST_DIS_HVBUS" 12 "SHUTDOWN" 13 "12V_SUPPORT_FAULTED" 14 "DIS_HVBUS_FAULTED" 15 "PCHG_FAULTED" 16 "CLEAR_FAULTS" 17 "FAULTED" 18 "NUM" ;
VAL_ 1060 PCS_a023_CP_status 0 "DISABLED" 1 "ENABLED" 2 "TEMPORARY_FAILURE" 3 "SNA" ;
VAL_ 1060 PCS_a027_chgPhATemp 4294966273 "SNA" ;
VAL_ 1060 PCS_a076_pcsControlRequest 0 "SHUTDOWN" 1 "SUPPORT" 2 "PRECHARGE" 3 "DISCHARGE" ;
VAL_ 1060 PCS_a084_dcdcSubState 0 "PWR_UP_INIT" 1 "STANDBY" 2 "12V_SUPPORT_ACTIVE" 3 "FAST_DIS_HVBUS" 4 "SLOW_DIS_HVBUS" 5 "PCHG_FAST_DIS_HVBUS" 6 "PCHG_SLOW_DIS_HVBUS" 7 "PCHG_DWELL_CHARGE" 8 "PCHG_DWELL_WAIT" 9 "PCHG_DI_RECOVERY_WAIT" 10 "PCHG_ACTIVE" 11 "PCHG_FLT_FAST_DIS_HVBUS" 12 "SHUTDOWN" 13 "12V_SUPPORT_FAULTED" 14 "DIS_HVBUS_FAULTED" 15 "PCHG_FAULTED" 16 "CLEAR_FAULTS" 17 "FAULTED" 18 "NUM" ;
VAL_ 1060 PCS_a088_gridConfig 0 "SNA" 1 "SINGLE_PHASE" 2 "THREE_PHASE" 3 "THREE_PHASE_DELTA" ;
VAL_ 1060 PCS_a096_gridConfig 0 "SNA" 1 "SINGLE_PHASE" 2 "THREE_PHASE" 3 "THREE_PHASE_DELTA" ;
VAL_ 1060 PCS_a098_gridConfig 0 "SNA" 1 "SINGLE_PHASE" 2 "THREE_PHASE" 3 "THREE_PHASE_DELTA" ;
VAL_ 1060 PCS_a099_gridConfig 0 "SNA" 1 "SINGLE_PHASE" 2 "THREE_PHASE" 3 "THREE_PHASE_DELTA" ;
VAL_ 1060 PCS_a102_pcsControlRequest 0 "SHUTDOWN" 1 "SUPPORT" 2 "PRECHARGE" 3 "DISCHARGE" ;
VAL_ 1060 PCS_alertID 0 "ALERT_DO_NOT_USE_ZERO" 1 "a001_DriverDoorOpen" 2 "a002_DoorOpen" 3 "a003_TrunkOpen" 4 "a004_FrunkOpen" 5 "a005_HeadlightsOnDoorOpen" 6 "a006_RemoteServiceAlert" 7 "a007_SoftPackConfigMismatch" 8 "a008_TouchScreenError" 9 "a009_SquashfsError" 10 "a010_MapsMissing" 11 "a011_IncorrectMap" 12 "a012_NotOnPrivateProperty" 13 "a013_TPMSHardWarning" 14 "a014_TPMSSoftWarning" 15 "a015_TPMSOverPressureWarning" 16 "a016_TPMSTemperatureWarning" 17 "a017_TPMSSystemFault" 18 "a018_SlipStartOn" 19 "a019_ParkBrakeFault" 20 "a020_SteeringReduced" 21 "a021_RearSeatbeltUnbuckled" 22 "a022_ApeFusesEtc" 23 "a023_CellInternetCheckFailed" 24 "a024_WifiInternetCheckFailed" 25 "a025_WifiOnlineCheckFailed" 26 "a026_ModemResetLoopDetected" 27 "a027_AutoSteerMIA" 28 "a028_FrontTrunkPopupClosed" 29 "a029_ModemMIA" 30 "a030_ModemVMCrash" 31 "a031_BrakeFluidLow" 32 "a032_CellModemRecoveryResets" 33 "a033_ApTrialExpired" 34 "a034_WakeupProblem" 35 "a035_AudioWatchdogKernelError" 36 "a036_AudioWatchdogHfpError" 37 "a037_AudioWatchdogXrunStormError" 38 "a038_AudioWatchdogA2bI2cLockupError" 39 "a039_AudioA2bNeedRediscovery" 40 "a040_HomelinkTransmit" 41 "a041_AudioDmesgXrun" 42 "a042_AudioDmesgRtThrottling" 43 "a043_InvalidMapDataOverride" 44 "a044_AudioDmesgDspException" 45 "a045_ECallNeedsService" 46 "a046_BackupCameraStreamError" 47 "a047_CellRoamingDisallowed" 48 "a048_AudioPremiumAmpCheckFailed" 49 "a049_BrakeShiftRequired" 50 "a050_BackupCameraIPUTimeout" 51 "a051_BackupCameraFrameTimeout" 52 "a052_KernelPanicReported" 53 "a053_QtCarExitError" 54 "a054_AudioBoostPowerBad" 55 "a055_ManualECallDisabled" 56 "a056_ManualECallButtonDisconnected" 57 "a057_CellAntennaDisconnected" 58 "a058_GPSAntennaDisconnected" 59 "a059_ECallSpeakerDisconnected" 60 "a060_ECallMicDisconnected" 61 "a061_SIMTestFailed" 62 "a062_ENSTestFailed" 63 "a063_CellularTestFailed" 64 "a064_ModemFirmwareTestFailed" 65 "a065_WiFiRecoveryReset" 66 "a066_GpuHangDetected" 67 "a067_WarnOnI915" 68 "a068_VideoUnexpectedExit" 69 "a069_VideoUDPTimeout" 70 "a070_VideoPipelineWarning" 71 "a071_VideoPipelineError" 72 "a072_ECallAnalogMicFailed" 73 "a073_ECallDigitalMicFailed" 74 "a074_EMMCHangDetected" 75 "a075_BackupCameraInitError" 76 "a076_NumFalseManualECalls" 77 "a077_AudioA2bMicChannelSwap" 78 "a078_DashcamUsbDriveUnmountable" 79 "a079_DashcamUsbDriveFull" 80 "a080_DashcamUsbDriveSlow" 81 "a081_CellModemSearchExpired" 82 "a082_NumModemRebootStuckInECall" 83 "a083_ECallProxyWatchdogTriggered" 84 "a084_SerializerError" 85 "a085_DeserializerError" 86 "a086_TouchEnumerationError" 87 "a087_BmpReset" 88 "a088_CellRemovableSimMissing" 89 "a089_RadioSoftResetError" 90 "a090_RadioPingFailError" 91 "a091_VehicleLinkStall" 92 "a092_updateStarted" 93 "a093_updateEnded" 94 "a094_ModemPowerOnFailure" 95 "a095_CidStorageRunningLow" 96 "a096_VideodPipelineIssueDetected" 97 "a097_AudiodRestarted" 98 "a098_DiskCheckFailure" 99 "a099_eMMCStatusError" 100 "a100_eMMCFTLError" 101 "a101_wifiStackProblem" 102 "a102_A2bDiscoveryFailed" 103 "a103_UsbHubNotEnumerating" 104 "a104_DashcamUsbDriveMissing" 105 "a105_firmwareReinstallRequested" 106 "a106_rebootBackstopTriggered" 107 "a107_DashcamUsbDriveTooBigForVfatFsck" 108 "a108_DashcamUsbDriveGettingFull" 109 "a109_DashcamUsbDriveTooSmall" 110 "a110_DashcamUsbDriveCorrupt" 111 "a111_DashcamUsbDriveWrongPort" 112 "a112_badUSBDevice" 113 "a113_DashcamHasOnboardSentryClips" ;
CM_ BO_ 1061 "ESP32-DualCAN Model3_CH. Seen on this car: 8-byte frames; fit weak (bits covered 0%, mux 100%, ranges 100%).";
CM_ BO_ 1070 "ESP32-DualCAN Model3_VEH. Seen on this car: 8-byte frames; fit weak (bits covered 0%, mux 100%, ranges 100%).";
CM_ BO_ 1071 "ESP32-DualCAN Model3_VEH. Seen on this car: 7-byte frames; fit ok (bits covered 96%, mux 100%, ranges 100%).";
CM_ BO_ 1074 "ESP32-DualCAN Model3_VEH. Not seen on this car in the logs.";
